[part 5 of 23: package /Cluster]
AUTOSAR XML (schema 4-3-0)
package /Cluster  (continued)
  can cluster E3V_EVCANFD: baudrate=500000, protocol-name=CAN, protocol-version=2.0, bus-off-recovery={bor-counter-l-1-to-l-2=1, bor-time-l-1=0.05, bor-time-l-2=0.2}, can-fd-baudrate=2000000  (continued)
    can physical channel CHNL: comm-connectors=CN_E3V_EVCANFD  (continued)
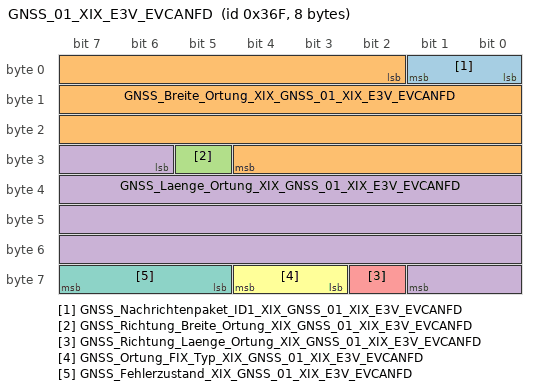
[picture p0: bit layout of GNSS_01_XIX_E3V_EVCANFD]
      frame GNSS_01_XIX_E3V_EVCANFD: id 0x36F, to Klima, frame-length=8, can-addressing-mode=STANDARD, can-frame-rx-behavior=CAN-FD, can-frame-tx-behavior=CAN-FD
        pdu GNSS_01_XIX_E3V_EVCANFD: length=8, transmission-mode-true-timing=cyclic-timing={time-offset=0.0, time-period=1.0}, unused-bit-pattern=0  # Nachricht 1 für Ortung: Position und Fixtyp.
          signal GNSS_Nachrichtenpaket_ID1_XIX_GNSS_01_XIX_E3V_EVCANFD: start 0, 2 bit, little-endian, data-type-policy=OVERRIDE, i-signal-type=PRIMITIVE, init-value=0, base-type=BT_GNSS_Nachrichtenpaket_ID1, compu {phys=raw for raw 0..3; unit Unit_Bit}, range phys 0..3 Unit_Bit, raw 0..3, unit=Unit_Bit, transfer-property=PENDING  # +1 für jedes neue Paket. Zyklische ID-Vergabe (Zähler). Zur Identifizierung zusammenhängender Nachrichten, die die Daten derselben GNSS-Ortung enthalten und somit zum selben Zyklus gehören. D.h. Daten in den Nachrichten wurden zur selben Zeit erzeugt. Der Zähler läuft um.
          signal GNSS_Breite_Ortung_XIX_GNSS_01_XIX_E3V_EVCANFD: start 2, 27 bit, little-endian, data-type-policy=OVERRIDE, i-signal-type=PRIMITIVE, init-value=134217726, base-type=BT_GNSS_Breite_Ortung, invalid-value=Invalid_GNSS_Breite_Ortung_XIX_GNSS_01_XIX_E3V_EVCANFD:134217727, compu {phys=raw*1e-06 for raw 0..90000000, 134217726=Cx7fffffe_Init (CM_GNSS_Breite_Ortung_Cx7fffffe_Init), 134217727=Cx7ffffff_Fehler (CM_GNSS_Breite_Ortung_Cx7ffffff_Fehler); unit Unit_DegreOfArc}, range phys 0..90 Unit_DegreOfArc, raw 0..134217727, unit=Unit_DegreOfArc, transfer-property=PENDING, to Klima(timeout 5 s)  # Breitengrad des Ortungsergebnisses nach WGS84 als Kombination von mehreren GNSSen
          signal GNSS_Richtung_Breite_Ortung_XIX_GNSS_01_XIX_E3V_EVCANFD: start 29, 1 bit, little-endian, data-type-policy=OVERRIDE, i-signal-type=PRIMITIVE, init-value=1, base-type=BT_GNSS_Richtung_Breite_Ortung, compu {0=Cx0_Nord (CM_GNSS_Richtung_Breite_Ortung_Cx0_Nord), 1=Cx1_Sued (CM_GNSS_Richtung_Breite_Ortung_Cx1_Sued)}, range raw 0..1, transfer-property=PENDING, to Klima(timeout 5 s)  # Richtung des Breitengrads des Ortungsergebnisses nach WGS84 als Kombination von mehreren GNSSen
          signal GNSS_Laenge_Ortung_XIX_GNSS_01_XIX_E3V_EVCANFD: start 30, 28 bit, little-endian, data-type-policy=OVERRIDE, i-signal-type=PRIMITIVE, init-value=268435454, base-type=BT_GNSS_Laenge_Ortung, invalid-value=Invalid_GNSS_Laenge_Ortung_XIX_GNSS_01_XIX_E3V_EVCANFD:268435455, compu {phys=raw*1e-06 for raw 0..180000000, 268435454=Cxffffffe_Init (CM_GNSS_Laenge_Ortung_Cxffffffe_Init), 268435455=Cxfffffff_Fehler (CM_GNSS_Laenge_Ortung_Cxfffffff_Fehler); unit Unit_DegreOfArc}, range phys 0..180 Unit_DegreOfArc, raw 0..268435455, unit=Unit_DegreOfArc, transfer-property=PENDING, to Klima(timeout 5 s)  # Längengrad des Ortungsergebnisses nach WGS84 als Kombination von mehreren GNSSen
          signal GNSS_Richtung_Laenge_Ortung_XIX_GNSS_01_XIX_E3V_EVCANFD: start 58, 1 bit, little-endian, data-type-policy=OVERRIDE, i-signal-type=PRIMITIVE, init-value=1, base-type=BT_GNSS_Richtung_Laenge_Ortung, compu {0=Cx0_Ost (CM_GNSS_Richtung_Laenge_Ortung_Cx0_Ost), 1=Cx1_West (CM_GNSS_Richtung_Laenge_Ortung_Cx1_West)}, range raw 0..1, transfer-property=PENDING, to Klima(timeout 5 s)  # Richtung des Längengrads des Ortungsergebnisses nach WGS84 als Kombination von mehreren GNSSen
          signal GNSS_Ortung_FIX_Typ_XIX_GNSS_01_XIX_E3V_EVCANFD: start 59, 2 bit, little-endian, data-type-policy=OVERRIDE, i-signal-type=PRIMITIVE, init-value=0, base-type=BT_GNSS_Ortung_FIX_Typ, compu {0=Cx0_Init (CM_GNSS_Ortung_FIX_Typ_Cx0_Init), 1=Cx1_No_Fix (CM_GNSS_Ortung_FIX_Typ_Cx1_No_Fix), 2=Cx2_2D_Fix (CM_GNSS_Ortung_FIX_Typ_Cx2_2D_Fix), 3=Cx3_3D_Fix (CM_GNSS_Ortung_FIX_Typ_Cx3_3D_Fix)}, range raw 0..3, transfer-property=PENDING  # Art des "GNSS-Fix" für die aktuelle Position auf Basis mehrerer GNSS Systeme.
          signal GNSS_Fehlerzustand_XIX_GNSS_01_XIX_E3V_EVCANFD: start 61, 3 bit, little-endian, data-type-policy=OVERRIDE, i-signal-type=PRIMITIVE, init-value=0, base-type=BT_GNSS_Fehlerzustand, compu {0=Cx0_Kein_Fehler (CM_GNSS_Fehlerzustand_Cx0_Kein_Fehler), 1=Cx1_P_Mode (CM_GNSS_Fehlerzustand_Cx1_P_Mode), 2=Cx2_T_Mode (CM_GNSS_Fehlerzustand_Cx2_T_Mode), 3=Cx3_GNSS_Receiver_Problem (CM_GNSS_Fehlerzustand_Cx3_GNSS_Receiver_Problem), 4=Cx4_Kommunikationsproblem_im_SG (CM_GNSS_Fehlerzustand_Cx4_Kommunikationsproblem_im_SG), 5=Cx5_Start_GNSS_Receiver (CM_GNSS_Fehlerzustand_Cx5_Start_GNSS_Receiver), 6=Cx6_GNSS_Receiver_aus (CM_GNSS_Fehlerzustand_Cx6_GNSS_Receiver_aus), 7=Cx7_SG_spezifischer_Fehler (CM_GNSS_Fehlerzustand_Cx7_SG_spezifischer_Fehler)}, range raw 0..7, transfer-property=PENDING  # Fehlerzustand von der GNSS-Funktion, daraufhin können keine GNSS-Daten geliefert werden
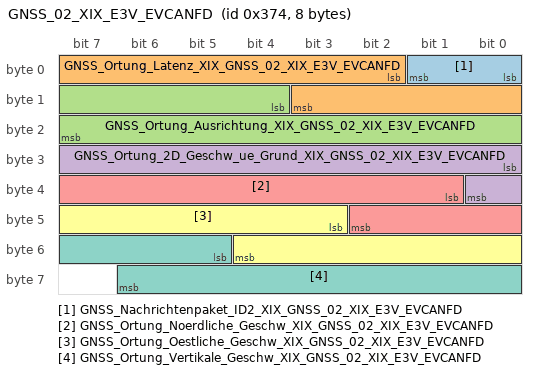
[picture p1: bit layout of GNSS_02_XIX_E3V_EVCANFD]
      frame GNSS_02_XIX_E3V_EVCANFD: id 0x374, to Klima, frame-length=8, can-addressing-mode=STANDARD, can-frame-rx-behavior=CAN-FD, can-frame-tx-behavior=CAN-FD
        pdu GNSS_02_XIX_E3V_EVCANFD: length=8, transmission-mode-true-timing=cyclic-timing={time-offset=0.0, time-period=1.0}, unused-bit-pattern=0  # Nachricht 2 für Ortung: Latenz, Geschwindigkeit und Richtung.
          signal GNSS_Nachrichtenpaket_ID2_XIX_GNSS_02_XIX_E3V_EVCANFD: start 0, 2 bit, little-endian, data-type-policy=OVERRIDE, i-signal-type=PRIMITIVE, init-value=0, base-type=BT_GNSS_Nachrichtenpaket_ID2, compu {phys=raw for raw 0..3; unit Unit_Bit}, range phys 0..3 Unit_Bit, raw 0..3, unit=Unit_Bit, transfer-property=PENDING  # +1 für jedes neue Paket. Zyklische ID-Vergabe (Zähler). Zur Identifizierung zusammenhängender Nachrichten, die die Daten derselben GNSS-Ortung enthalten und somit zum selben Zyklus gehören. D.h. Daten in den Nachrichten wurden zur selben Zeit erzeugt. Der Zähler läuft um.
          signal GNSS_Ortung_Latenz_XIX_GNSS_02_XIX_E3V_EVCANFD: start 2, 10 bit, little-endian, data-type-policy=OVERRIDE, i-signal-type=PRIMITIVE, init-value=1022, base-type=BT_GNSS_Ortung_Latenz, invalid-value=Invalid_GNSS_Ortung_Latenz_XIX_GNSS_02_XIX_E3V_EVCANFD:1023, compu {phys=raw for raw 0..1021, 1022=Cx3fe_Init (CM_GNSS_Ortung_Latenz_Cx3fe_Init), 1023=Cx3ff_Fehler (CM_GNSS_Ortung_Latenz_Cx3ff_Fehler); unit Unit_MilliSecon}, range phys 0..1021 Unit_MilliSecon, raw 0..1023, unit=Unit_MilliSecon, transfer-property=PENDING  # Latenz zwischen GNSS-Messung und aktueller Verteilung über CAN-Bus. Hinweis: Zur Stabilisierung der Latenz soll die GNSS-Zeit für die Bestimmung der CAN-Zyklendauer verwendet werden.
          signal GNSS_Ortung_Ausrichtung_XIX_GNSS_02_XIX_E3V_EVCANFD: start 12, 12 bit, little-endian, data-type-policy=OVERRIDE, i-signal-type=PRIMITIVE, init-value=4094, base-type=BT_GNSS_Ortung_Ausrichtung, invalid-value=Invalid_GNSS_Ortung_Ausrichtung_XIX_GNSS_02_XIX_E3V_EVCANFD:4095, compu {phys=raw*0.1 for raw 0..3599, 4094=Cxffe_Init (CM_GNSS_Ortung_Ausrichtung_Cxffe_Init), 4095=Cxfff_Fehler (CM_GNSS_Ortung_Ausrichtung_Cxfff_Fehler); unit Unit_DegreOfArc}, range phys 0..359.9 Unit_DegreOfArc, raw 0..4095, unit=Unit_DegreOfArc, transfer-property=PENDING, to Klima(timeout 5 s)  # Ausrichtung (Kurswinkel) der GNSS-Messung
          signal GNSS_Ortung_2D_Geschw_ue_Grund_XIX_GNSS_02_XIX_E3V_EVCANFD: start 24, 9 bit, little-endian, data-type-policy=OVERRIDE, i-signal-type=PRIMITIVE, init-value=510, base-type=BT_GNSS_Ortung_2D_Geschw_ue_Grund, invalid-value=Invalid_GNSS_Ortung_2D_Geschw_ue_Grund_XIX_GNSS_02_XIX_E3V_EVCANFD:511, compu {phys=raw*0.25 for raw 0..500, 510=Cx1fe_Init (CM_GNSS_Ortung_2D_Geschw_ue_Grund_Cx1fe_Init), 511=Cx1ff_Fehler (CM_GNSS_Ortung_2D_Geschw_ue_Grund_Cx1ff_Fehler); unit Unit_MeterPerSecon}, range phys 0..125 Unit_MeterPerSecon, raw 0..511, unit=Unit_MeterPerSecon, transfer-property=PENDING  # Geschwindigkeit in m pro Sekunde entsprechend dem GNSS-Empfänger
          signal GNSS_Ortung_Noerdliche_Geschw_XIX_GNSS_02_XIX_E3V_EVCANFD: start 33, 10 bit, little-endian, data-type-policy=OVERRIDE, i-signal-type=PRIMITIVE, init-value=1022, base-type=BT_GNSS_Ortung_Noerdliche_Geschw, invalid-value=Invalid_GNSS_Ortung_Noerdliche_Geschw_XIX_GNSS_02_XIX_E3V_EVCANFD:1023, compu {phys=raw*0.25-125 for raw 0..1000, 1022=Cx3fe_Init (CM_GNSS_Ortung_Noerdliche_Geschw_Cx3fe_Init), 1023=Cx3ff_Fehler (CM_GNSS_Ortung_Noerdliche_Geschw_Cx3ff_Fehler); unit Unit_MeterPerSecon}, range phys -125..125 Unit_MeterPerSecon, raw 0..1023, unit=Unit_MeterPerSecon, transfer-property=PENDING  # Geschwindigkeit in m pro Sekunde in Nordrichtung entsprechend dem GNSS-Empfänger
          signal GNSS_Ortung_Oestliche_Geschw_XIX_GNSS_02_XIX_E3V_EVCANFD: start 43, 10 bit, little-endian, data-type-policy=OVERRIDE, i-signal-type=PRIMITIVE, init-value=1022, base-type=BT_GNSS_Ortung_Oestliche_Geschw, invalid-value=Invalid_GNSS_Ortung_Oestliche_Geschw_XIX_GNSS_02_XIX_E3V_EVCANFD:1023, compu {phys=raw*0.25-125 for raw 0..1000, 1022=Cx3fe_Init (CM_GNSS_Ortung_Oestliche_Geschw_Cx3fe_Init), 1023=Cx3ff_Fehler (CM_GNSS_Ortung_Oestliche_Geschw_Cx3ff_Fehler); unit Unit_MeterPerSecon}, range phys -125..125 Unit_MeterPerSecon, raw 0..1023, unit=Unit_MeterPerSecon, transfer-property=PENDING  # Geschwindigkeit in m pro Sekunde in Ostrichtung entsprechend dem GNSS-Empfänger
          signal GNSS_Ortung_Vertikale_Geschw_XIX_GNSS_02_XIX_E3V_EVCANFD: start 53, 10 bit, little-endian, data-type-policy=OVERRIDE, i-signal-type=PRIMITIVE, init-value=1022, base-type=BT_GNSS_Ortung_Vertikale_Geschw, invalid-value=Invalid_GNSS_Ortung_Vertikale_Geschw_XIX_GNSS_02_XIX_E3V_EVCANFD:1023, compu {phys=raw*0.25-125 for raw 0..1000, 1022=Cx3fe_Init (CM_GNSS_Ortung_Vertikale_Geschw_Cx3fe_Init), 1023=Cx3ff_Fehler (CM_GNSS_Ortung_Vertikale_Geschw_Cx3ff_Fehler); unit Unit_MeterPerSecon}, range phys -125..125 Unit_MeterPerSecon, raw 0..1023, unit=Unit_MeterPerSecon, transfer-property=PENDING  # Geschwindigkeit in m pro Sekunde in vertikaler Richtung (aufwärts) entsprechend dem GNSS-Empfänger
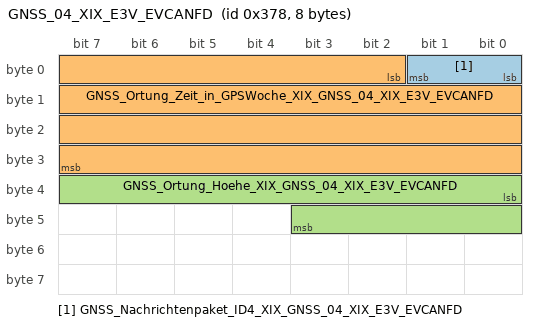
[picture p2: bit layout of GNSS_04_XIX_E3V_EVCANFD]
      frame GNSS_04_XIX_E3V_EVCANFD: id 0x378, to Klima, frame-length=8, can-addressing-mode=STANDARD, can-frame-rx-behavior=CAN-FD, can-frame-tx-behavior=CAN-FD
        pdu GNSS_04_XIX_E3V_EVCANFD: length=8, transmission-mode-true-timing=cyclic-timing={time-offset=0.0, time-period=1.0}, unused-bit-pattern=0  # Nachricht 4 für Ortung: Zeitstempel der Ortung.
          signal GNSS_Nachrichtenpaket_ID4_XIX_GNSS_04_XIX_E3V_EVCANFD: start 0, 2 bit, little-endian, data-type-policy=OVERRIDE, i-signal-type=PRIMITIVE, init-value=0, base-type=BT_GNSS_Nachrichtenpaket_ID4, compu {phys=raw for raw 0..3; unit Unit_Bit}, range phys 0..3 Unit_Bit, raw 0..3, unit=Unit_Bit, transfer-property=PENDING  # +1 für jedes neue Paket. Zyklische ID-Vergabe (Zähler). Zur Identifizierung zusammenhängender Nachrichten, die die Daten derselben GNSS-Ortung enthalten und somit zum selben Zyklus gehören. D.h. Daten in den Nachrichten wurden zur selben Zeit erzeugt. Der Zähler läuft um.
          signal GNSS_Ortung_Zeit_in_GPSWoche_XIX_GNSS_04_XIX_E3V_EVCANFD: start 2, 30 bit, little-endian, data-type-policy=OVERRIDE, i-signal-type=PRIMITIVE, init-value=1073741822, base-type=BT_GNSS_Ortung_Zeit_in_GPSWoche, invalid-value=Invalid_GNSS_Ortung_Zeit_in_GPSWoche_XIX_GNSS_04_XIX_E3V_EVCANFD:1073741823, compu {phys=raw for raw 0..604800001, 1073741822=Cx3ffffffe_Init (CM_GNSS_Ortung_Zeit_in_GPSWoche_Cx3ffffffe_Init), 1073741823=Cx3fffffff_Fehler (CM_GNSS_Ortung_Zeit_in_GPSWoche_Cx3fffffff_Fehler); unit Unit_MilliSecon}, range phys 0..604800001 Unit_MilliSecon, raw 0..1073741823, unit=Unit_MilliSecon, transfer-property=PENDING  # Zeitstempel für die Jitter-Prüfung aso. Zeit muss sychron zur Zeit der GNSS-Ortung sein.
          signal GNSS_Ortung_Hoehe_XIX_GNSS_04_XIX_E3V_EVCANFD: start 32, 12 bit, little-endian, data-type-policy=OVERRIDE, i-signal-type=PRIMITIVE, init-value=4094, base-type=BT_GNSS_Ortung_Hoehe, invalid-value=Invalid_GNSS_Ortung_Hoehe_XIX_GNSS_04_XIX_E3V_EVCANFD:4095, compu {phys=raw*2-500 for raw 0..4093, 4094=Cxffe_Init (CM_GNSS_Ortung_Hoehe_Cxffe_Init), 4095=Cxfff_Fehler (CM_GNSS_Ortung_Hoehe_Cxfff_Fehler); unit Unit_Meter}, range phys -500..7686 Unit_Meter, raw 0..4095, unit=Unit_Meter, transfer-property=PENDING, to Klima(timeout 5 s)  # Höhe über dem Meeresspiegel
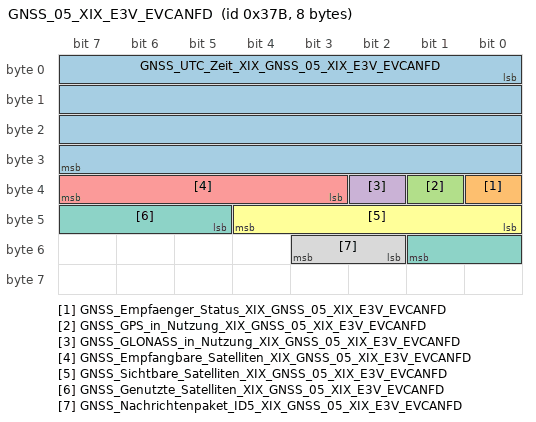
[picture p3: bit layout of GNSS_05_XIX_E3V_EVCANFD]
      frame GNSS_05_XIX_E3V_EVCANFD: id 0x37B, to Klima, frame-length=8, can-addressing-mode=STANDARD, can-frame-rx-behavior=CAN-FD, can-frame-tx-behavior=CAN-FD
        pdu GNSS_05_XIX_E3V_EVCANFD: length=8, transmission-mode-true-timing=cyclic-timing={time-offset=0.0, time-period=1.0}, unused-bit-pattern=0  # Nachricht 5: Empfängerstatus und UTC.
          signal GNSS_UTC_Zeit_XIX_GNSS_05_XIX_E3V_EVCANFD: start 0, 32 bit, little-endian, data-type-policy=OVERRIDE, i-signal-type=PRIMITIVE, init-value=0, base-type=BT_GNSS_UTC_Zeit, compu {0=Cx0_Init (CM_GNSS_UTC_Zeit_Cx0_Init), phys=raw for raw 1..4294967295; unit Unit_Secon}, range phys 1..4294967295 Unit_Secon, raw 0..4294967295, unit=Unit_Secon, transfer-property=PENDING, to Klima(timeout 5 s)  # UTC-Zeit, Sekunden seit dem 01.01.1970 00:00
          signal GNSS_Empfaenger_Status_XIX_GNSS_05_XIX_E3V_EVCANFD: start 32, 1 bit, little-endian, data-type-policy=OVERRIDE, i-signal-type=PRIMITIVE, init-value=0, base-type=BT_GNSS_Empfaenger_Status, compu {0=Cx0_Backup_Mode (CM_GNSS_Empfaenger_Status_Cx0_Backup_Mode), 1=Cx1_Live (CM_GNSS_Empfaenger_Status_Cx1_Live)}, range raw 0..1, transfer-property=PENDING  # Im "Backup Mode" wird z.B. die UTC Zeit durch eine gepufferte "Realtime Clock" bereitgestellt. Im "Live Mode" wird die UTC Zeit durch das GNSS Modul bereitgestellt.
          signal GNSS_GPS_in_Nutzung_XIX_GNSS_05_XIX_E3V_EVCANFD: start 33, 1 bit, little-endian, data-type-policy=OVERRIDE, i-signal-type=PRIMITIVE, init-value=0, base-type=BT_GNSS_GPS_in_Nutzung, compu {0=Cx0_unbenutzt (CM_GNSS_GPS_in_Nutzung_Cx0_unbenutzt), 1=Cx1_benutzt (CM_GNSS_GPS_in_Nutzung_Cx1_benutzt)}, range raw 0..1, transfer-property=PENDING  # 1: das genannte GNSS wurde für die Ortung verwendet
          signal GNSS_GLONASS_in_Nutzung_XIX_GNSS_05_XIX_E3V_EVCANFD: start 34, 1 bit, little-endian, data-type-policy=OVERRIDE, i-signal-type=PRIMITIVE, init-value=0, base-type=BT_GNSS_GLONASS_in_Nutzung, compu {0=Cx0_unbenutzt (CM_GNSS_GLONASS_in_Nutzung_Cx0_unbenutzt), 1=Cx1_benutzt (CM_GNSS_GLONASS_in_Nutzung_Cx1_benutzt)}, range raw 0..1, transfer-property=PENDING  # 1: das genannte GNSS wurde für die Ortung verwendet
          signal GNSS_Empfangbare_Satelliten_XIX_GNSS_05_XIX_E3V_EVCANFD: start 35, 5 bit, little-endian, data-type-policy=OVERRIDE, i-signal-type=PRIMITIVE, init-value=0, base-type=BT_GNSS_Empfangbare_Satelliten, compu {0=Cx0_Init (CM_GNSS_Empfangbare_Satelliten_Cx0_Init), phys=raw for raw 1..30, 31=Cx1f_31_oder_mehr (CM_GNSS_Empfangbare_Satelliten_Cx1f_31_oder_mehr); unit Unit_None}, range phys 1..30 Unit_None, raw 0..31, unit=Unit_None, transfer-property=PENDING  # Anzahl der Satelliten, welche bei der aktuellen Satellitenkonfiguration ptentiell verfügbar sind
          signal GNSS_Sichtbare_Satelliten_XIX_GNSS_05_XIX_E3V_EVCANFD: start 40, 5 bit, little-endian, data-type-policy=OVERRIDE, i-signal-type=PRIMITIVE, init-value=0, base-type=BT_GNSS_Sichtbare_Satelliten, compu {0=Cx0_Init (CM_GNSS_Sichtbare_Satelliten_Cx0_Init), phys=raw for raw 1..30, 31=Cx1f_31_oder_mehr (CM_GNSS_Sichtbare_Satelliten_Cx1f_31_oder_mehr); unit Unit_None}, range phys 1..30 Unit_None, raw 0..31, unit=Unit_None, transfer-property=PENDING  # Anzahl der Satelliten, welche aktuell empfangen werden
          signal GNSS_Genutzte_Satelliten_XIX_GNSS_05_XIX_E3V_EVCANFD: start 45, 5 bit, little-endian, data-type-policy=OVERRIDE, i-signal-type=PRIMITIVE, init-value=0, base-type=BT_GNSS_Genutzte_Satelliten, compu {0=Cx0_Init (CM_GNSS_Genutzte_Satelliten_Cx0_Init), phys=raw for raw 1..30, 31=Cx1f_31_oder_mehr (CM_GNSS_Genutzte_Satelliten_Cx1f_31_oder_mehr); unit Unit_None}, range phys 1..30 Unit_None, raw 0..31, unit=Unit_None, transfer-property=PENDING  # Anzahl der Satelliten, welche für die aktuelle Ortung verwendet werden
          signal GNSS_Nachrichtenpaket_ID5_XIX_GNSS_05_XIX_E3V_EVCANFD: start 50, 2 bit, little-endian, data-type-policy=OVERRIDE, i-signal-type=PRIMITIVE, init-value=0, base-type=BT_GNSS_Nachrichtenpaket_ID5, compu {phys=raw for raw 0..3; unit Unit_Bit}, range phys 0..3 Unit_Bit, raw 0..3, unit=Unit_Bit, transfer-property=PENDING  # +1 für jedes neue Paket. Zyklische ID-Vergabe (Zähler). Zur Identifizierung zusammenhängender Nachrichten, die die Daten derselben GNSS-Ortung enthalten und somit zum selben Zyklus gehören. D.h. Daten in den Nachrichten wurden zur selben Zeit erzeugt. Der Zähler läuft um.
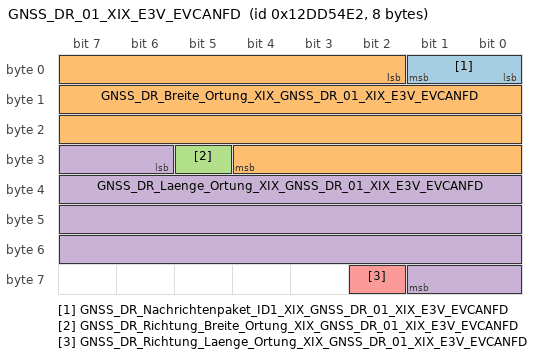
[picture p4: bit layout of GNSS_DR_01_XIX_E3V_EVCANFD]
      frame GNSS_DR_01_XIX_E3V_EVCANFD: id 0x12DD54E2, to Klima, frame-length=8, can-addressing-mode=EXTENDED, can-frame-rx-behavior=CAN-FD, can-frame-tx-behavior=CAN-FD
        pdu GNSS_DR_01_XIX_E3V_EVCANFD: length=8, transmission-mode-true-timing=cyclic-timing={time-offset=0, time-period=0.1}, unused-bit-pattern=0
          signal GNSS_DR_Nachrichtenpaket_ID1_XIX_GNSS_DR_01_XIX_E3V_EVCANFD: start 0, 2 bit, little-endian, data-type-policy=OVERRIDE, i-signal-type=PRIMITIVE, init-value=0, base-type=BT_GNSS_DR_Nachrichtenpaket_ID1, compu {phys=raw for raw 0..3; unit Unit_Bit}, range phys 0..3 Unit_Bit, raw 0..3, unit=Unit_Bit, transfer-property=PENDING  # +1 für jedes neue Paket. Zyklische ID-Vergabe (Zähler). Zur Identifizierung zusammenhängender Nachrichten, die die Daten derselben GNSS-Ortung enthalten und somit zum selben Zyklus gehören. D.h. Daten in den Nachrichten wurden zur selben Zeit erzeugt. Der Zähler läuft um.
          signal GNSS_DR_Breite_Ortung_XIX_GNSS_DR_01_XIX_E3V_EVCANFD: start 2, 27 bit, little-endian, data-type-policy=OVERRIDE, i-signal-type=PRIMITIVE, init-value=134217726, base-type=BT_GNSS_DR_Breite_Ortung, invalid-value=Invalid_GNSS_DR_Breite_Ortung_XIX_GNSS_DR_01_XIX_E3V_EVCANFD:134217727, compu {phys=raw*1e-06 for raw 0..90000000, 134217726=Cx7fffffe_Init (CM_GNSS_DR_Breite_Ortung_Cx7fffffe_Init), 134217727=Cx7ffffff_Fehler (CM_GNSS_DR_Breite_Ortung_Cx7ffffff_Fehler); unit Unit_DegreOfArc}, range phys 0..90 Unit_DegreOfArc, raw 0..134217727, unit=Unit_DegreOfArc, transfer-property=PENDING, to Klima(timeout 1 s)  # Dead Reckoning Breitengrad des Ortungsergebnisses nach WGS84 als Kombination von mehreren GNSSen
          signal GNSS_DR_Richtung_Breite_Ortung_XIX_GNSS_DR_01_XIX_E3V_EVCANFD: start 29, 1 bit, little-endian, data-type-policy=OVERRIDE, i-signal-type=PRIMITIVE, init-value=1, base-type=BT_GNSS_DR_Richtung_Breite_Ortung, compu {0=Cx0_Nord (CM_GNSS_DR_Richtung_Breite_Ortung_Cx0_Nord), 1=Cx1_Sued (CM_GNSS_DR_Richtung_Breite_Ortung_Cx1_Sued)}, range raw 0..1, transfer-property=PENDING, to Klima(timeout 1 s)  # Dead Reckoning Richtung des Breitengrads des Ortungsergebnisses nach WGS84 als Kombination von mehreren GNSSen
          signal GNSS_DR_Laenge_Ortung_XIX_GNSS_DR_01_XIX_E3V_EVCANFD: start 30, 28 bit, little-endian, data-type-policy=OVERRIDE, i-signal-type=PRIMITIVE, init-value=268435454, base-type=BT_GNSS_DR_Laenge_Ortung, invalid-value=Invalid_GNSS_DR_Laenge_Ortung_XIX_GNSS_DR_01_XIX_E3V_EVCANFD:268435455, compu {phys=raw*1e-06 for raw 0..180000000, 268435454=Cxffffffe_Init (CM_GNSS_DR_Laenge_Ortung_Cxffffffe_Init), 268435455=Cxfffffff_Fehler (CM_GNSS_DR_Laenge_Ortung_Cxfffffff_Fehler); unit Unit_DegreOfArc}, range phys 0..180 Unit_DegreOfArc, raw 0..268435455, unit=Unit_DegreOfArc, transfer-property=PENDING, to Klima(timeout 1 s)  # Dead Reckoning Längengrad des Ortungsergebnisses nach WGS84 als Kombination von mehreren GNSSen
          signal GNSS_DR_Richtung_Laenge_Ortung_XIX_GNSS_DR_01_XIX_E3V_EVCANFD: start 58, 1 bit, little-endian, data-type-policy=OVERRIDE, i-signal-type=PRIMITIVE, init-value=1, base-type=BT_GNSS_DR_Richtung_Laenge_Ortung, compu {0=Cx0_Ost (CM_GNSS_DR_Richtung_Laenge_Ortung_Cx0_Ost), 1=Cx1_West (CM_GNSS_DR_Richtung_Laenge_Ortung_Cx1_West)}, range raw 0..1, transfer-property=PENDING, to Klima(timeout 1 s)  # Dead Reckoning Richtung des Längengrads des Ortungsergebnisses nach WGS84 als Kombination von mehreren GNSSen
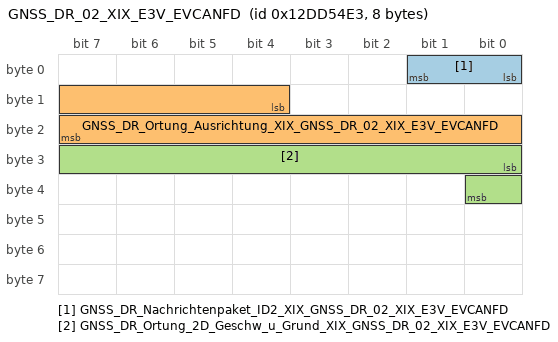
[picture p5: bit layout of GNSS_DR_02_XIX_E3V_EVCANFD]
      frame GNSS_DR_02_XIX_E3V_EVCANFD: id 0x12DD54E3, to Klima, frame-length=8, can-addressing-mode=EXTENDED, can-frame-rx-behavior=CAN-FD, can-frame-tx-behavior=CAN-FD
        pdu GNSS_DR_02_XIX_E3V_EVCANFD: length=8, transmission-mode-true-timing=cyclic-timing={time-offset=0, time-period=0.1}, unused-bit-pattern=0
          signal GNSS_DR_Nachrichtenpaket_ID2_XIX_GNSS_DR_02_XIX_E3V_EVCANFD: start 0, 2 bit, little-endian, data-type-policy=OVERRIDE, i-signal-type=PRIMITIVE, init-value=0, base-type=BT_GNSS_DR_Nachrichtenpaket_ID2, compu {phys=raw for raw 0..3; unit Unit_Bit}, range phys 0..3 Unit_Bit, raw 0..3, unit=Unit_Bit, transfer-property=PENDING  # +1 für jedes neue Paket. Zyklische ID-Vergabe (Zähler). Zur Identifizierung zusammenhängender Nachrichten, die die Daten derselben GNSS-Ortung enthalten und somit zum selben Zyklus gehören. D.h. Daten in den Nachrichten wurden zur selben Zeit erzeugt. Der Zähler läuft um.
          signal GNSS_DR_Ortung_Ausrichtung_XIX_GNSS_DR_02_XIX_E3V_EVCANFD: start 12, 12 bit, little-endian, data-type-policy=OVERRIDE, i-signal-type=PRIMITIVE, init-value=4094, base-type=BT_GNSS_DR_Ortung_Ausrichtung, invalid-value=Invalid_GNSS_DR_Ortung_Ausrichtung_XIX_GNSS_DR_02_XIX_E3V_EVCANFD:4095, compu {phys=raw*0.1 for raw 0..3599, 4094=Cxffe_Init (CM_GNSS_DR_Ortung_Ausrichtung_Cxffe_Init), 4095=Cxfff_Fehler (CM_GNSS_DR_Ortung_Ausrichtung_Cxfff_Fehler); unit Unit_DegreOfArc}, range phys 0..359.9 Unit_DegreOfArc, raw 0..4095, unit=Unit_DegreOfArc, transfer-property=PENDING, to Klima(timeout 1 s)  # Dead Reckoning Ausrichtung (Kurswinkel) der GNSS-Messung
          signal GNSS_DR_Ortung_2D_Geschw_u_Grund_XIX_GNSS_DR_02_XIX_E3V_EVCANFD: start 24, 9 bit, little-endian, data-type-policy=OVERRIDE, i-signal-type=PRIMITIVE, init-value=510, base-type=BT_GNSS_DR_Ortung_2D_Geschw_u_Grund, invalid-value=Invalid_GNSS_DR_Ortung_2D_Geschw_u_Grund_XIX_GNSS_DR_02_XIX_E3V_EVCANFD:511, compu {phys=raw*0.25 for raw 0..500, 510=Cx1fe_Init (CM_GNSS_DR_Ortung_2D_Geschw_u_Grund_Cx1fe_Init), 511=Cx1ff_Fehler (CM_GNSS_DR_Ortung_2D_Geschw_u_Grund_Cx1ff_Fehler); unit Unit_MeterPerSecon}, range phys 0..125 Unit_MeterPerSecon, raw 0..511, unit=Unit_MeterPerSecon, transfer-property=PENDING  # Dead Reckoning Geschwindigkeit in m pro Sekunde
      frame GNSS_DR_05_XIX_E3V_EVCANFD: id 0x12DD54E6, to Klima, frame-length=8, can-addressing-mode=EXTENDED, can-frame-rx-behavior=CAN-FD, can-frame-tx-behavior=CAN-FD
        pdu GNSS_DR_05_XIX_E3V_EVCANFD: length=8, transmission-mode-true-timing=cyclic-timing={time-offset=0, time-period=0.1}, unused-bit-pattern=0
          signal GNSS_DR_UTC_Zeit_XIX_GNSS_DR_05_XIX_E3V_EVCANFD: start 0, 32 bit, little-endian, data-type-policy=OVERRIDE, i-signal-type=PRIMITIVE, init-value=0, base-type=BT_GNSS_DR_UTC_Zeit, compu {0=Cx0_Init (CM_GNSS_DR_UTC_Zeit_Cx0_Init), phys=raw for raw 1..4294967295; unit Unit_Secon}, range phys 1..4294967295 Unit_Secon, raw 0..4294967295, unit=Unit_Secon, transfer-property=PENDING, to Klima(timeout 1 s)  # Dead Reckoning UTC-Zeit, Sekunden seit dem 01.01.1970 00:00
          signal GNSS_DR_Nachrichtenpaket_ID5_XIX_GNSS_DR_05_XIX_E3V_EVCANFD: start 32, 2 bit, little-endian, data-type-policy=OVERRIDE, i-signal-type=PRIMITIVE, init-value=0, base-type=BT_GNSS_DR_Nachrichtenpaket_ID5, compu {phys=raw for raw 0..3; unit Unit_Bit}, range phys 0..3 Unit_Bit, raw 0..3, unit=Unit_Bit, transfer-property=PENDING  # +1 für jedes neue Paket. Zyklische ID-Vergabe (Zähler). Zur Identifizierung zusammenhängender Nachrichten, die die Daten derselben GNSS-Ortung enthalten und somit zum selben Zyklus gehören. D.h. Daten in den Nachrichten wurden zur selben Zeit erzeugt. Der Zähler läuft um.
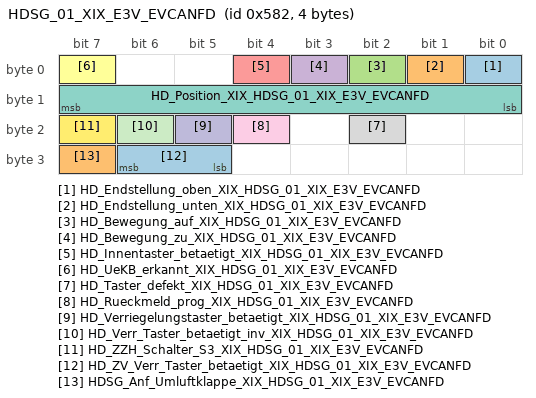
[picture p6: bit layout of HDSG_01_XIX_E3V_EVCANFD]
      frame HDSG_01_XIX_E3V_EVCANFD: id 0x582, to Klima, frame-length=4, can-addressing-mode=STANDARD, can-frame-rx-behavior=CAN-FD, can-frame-tx-behavior=CAN-FD
        pdu HDSG_01_XIX_E3V_EVCANFD: length=4, minimum-delay=0.02, transmission-mode-true-timing={cyclic-timing={time-offset=0.0, time-period=0.2}, event-controlled-timing={number-of-repetitions=0, repetition-period=0.0}}, unused-bit-pattern=0
          signal HD_Endstellung_oben_XIX_HDSG_01_XIX_E3V_EVCANFD: start 0, 1 bit, little-endian, data-type-policy=OVERRIDE, i-signal-type=PRIMITIVE, init-value=0, base-type=BT_HD_Endstellung_oben, compu {1=Cx1_HD_in_Endstellung_oben_offen (CM_HD_Endstellung_oben_Cx1_HD_in_Endstellung_oben_offen) (HD in Endstellung oben (offen))}, range raw 1, transfer-property=PENDING  # obere Endstellung HD
          signal HD_Endstellung_unten_XIX_HDSG_01_XIX_E3V_EVCANFD: start 1, 1 bit, little-endian, data-type-policy=OVERRIDE, i-signal-type=PRIMITIVE, init-value=0, base-type=BT_HD_Endstellung_unten, compu {0=Cx0_Init (CM_HD_Endstellung_unten_Cx0_Init), 1=Cx1_HD_in_Endstellung_unten_geschlossen (CM_HD_Endstellung_unten_Cx1_HD_in_Endstellung_unten_geschlossen) (HD in Endstellung unten (geschlossen))}, range raw 0..1, transfer-property=PENDING  # untere Endstellung HD
          signal HD_Bewegung_auf_XIX_HDSG_01_XIX_E3V_EVCANFD: start 2, 1 bit, little-endian, data-type-policy=OVERRIDE, i-signal-type=PRIMITIVE, init-value=0, base-type=BT_HD_Bewegung_auf, compu {0=Cx0_Init (CM_HD_Bewegung_auf_Cx0_Init), 1=Cx1_HD_in_Bewegung_auf (CM_HD_Bewegung_auf_Cx1_HD_in_Bewegung_auf) (HD in Bewegung auf)}, range raw 0..1, transfer-property=PENDING  # Bewegung HD (öffnen)
          signal HD_Bewegung_zu_XIX_HDSG_01_XIX_E3V_EVCANFD: start 3, 1 bit, little-endian, data-type-policy=OVERRIDE, i-signal-type=PRIMITIVE, init-value=0, base-type=BT_HD_Bewegung_zu, compu {0=Cx0_Init (CM_HD_Bewegung_zu_Cx0_Init), 1=Cx1_HD_in_Bewegung_zu (CM_HD_Bewegung_zu_Cx1_HD_in_Bewegung_zu) (HD in Bewegung zu)}, range raw 0..1, transfer-property=PENDING  # Bewegung HD (schließen)
          signal HD_Innentaster_betaetigt_XIX_HDSG_01_XIX_E3V_EVCANFD: start 4, 1 bit, little-endian, data-type-policy=OVERRIDE, i-signal-type=PRIMITIVE, init-value=0, base-type=BT_HD_Innentaster_betaetigt, compu {0=Cx0_HD_Innentaster_nicht_betaetigt (CM_HD_Innentaster_betaetigt_Cx0_HD_Innentaster_nicht_betaetigt), 1=Cx1_HD_Innentaster_betaetigt (CM_HD_Innentaster_betaetigt_Cx1_HD_Innentaster_betaetigt)}, range raw 0..1, transfer-property=PENDING  # Betätigung Innentaster HD
          signal HD_UeKB_erkannt_XIX_HDSG_01_XIX_E3V_EVCANFD: start 7, 1 bit, little-endian, data-type-policy=OVERRIDE, i-signal-type=PRIMITIVE, init-value=0, base-type=BT_HD_UeKB_erkannt, compu {0=Cx0_Init (CM_HD_UeKB_erkannt_Cx0_Init), 1=Cx1_Einklemmschutz_aktiv (CM_HD_UeKB_erkannt_Cx1_Einklemmschutz_aktiv) (Einklemmschutz aktiv)}, range raw 0..1, transfer-property=PENDING  # Erkennung Einklemmschutz
          signal HD_Position_XIX_HDSG_01_XIX_E3V_EVCANFD: start 8, 8 bit, little-endian, data-type-policy=OVERRIDE, i-signal-type=PRIMITIVE, init-value=0, base-type=BT_HD_Position, compu {phys=raw for raw 0..100; unit Unit_PerCent}, range phys 0..100 Unit_PerCent, raw 0..100, unit=Unit_PerCent, transfer-property=PENDING  # HD Position von 0 bis 100 %
          signal HD_Taster_defekt_XIX_HDSG_01_XIX_E3V_EVCANFD: start 18, 1 bit, little-endian, data-type-policy=OVERRIDE, i-signal-type=PRIMITIVE, init-value=0, base-type=BT_HD_Taster_defekt, compu {0=Cx0_Taster_funktionsfaehig (CM_HD_Taster_defekt_Cx0_Taster_funktionsfaehig) (Taster_funktionsfähig), 1=Cx1_Taster_defekt (CM_HD_Taster_defekt_Cx1_Taster_defekt) (Taster defekt)}, range raw 0..1, transfer-property=PENDING  # Anzeige ob Heckdeckeltaster defekt ist
          signal HD_Rueckmeld_prog_XIX_HDSG_01_XIX_E3V_EVCANFD: start 20, 1 bit, little-endian, data-type-policy=OVERRIDE, i-signal-type=PRIMITIVE, init-value=0, base-type=BT_HD_Rueckmeld_prog, compu {0=Cx0_keine_Rueckmeldung (CM_HD_Rueckmeld_prog_Cx0_keine_Rueckmeldung) (keine Rueckmeldung), 1=Cx1_Rueckmeldung_zur_Programmierung_Endstellung_aktiv (CM_HD_Rueckmeld_prog_Cx1_Rueckmeldung_zur_Programmierung_Endstellung_aktiv) (Rueckmeldung zur Programmierung Endstellung aktiv)}, range raw 0..1, transfer-property=PENDING  # Programmierung Endstellung HD
          signal HD_Verriegelungstaster_betaetigt_XIX_HDSG_01_XIX_E3V_EVCANFD: start 21, 1 bit, little-endian, data-type-policy=OVERRIDE, i-signal-type=PRIMITIVE, init-value=0, base-type=BT_HD_Verriegelungstaster_betaetigt, compu {0=Cx0_Taster_nicht_betaetigt (CM_HD_Verriegelungstaster_betaetigt_Cx0_Taster_nicht_betaetigt), 1=Cx1_Taster_betaetigt (CM_HD_Verriegelungstaster_betaetigt_Cx1_Taster_betaetigt)}, range raw 0..1, transfer-property=PENDING  # Betätigung des Verriegelungstaster für Heckdeckel
          signal HD_Verr_Taster_betaetigt_inv_XIX_HDSG_01_XIX_E3V_EVCANFD: start 22, 1 bit, little-endian, data-type-policy=OVERRIDE, i-signal-type=PRIMITIVE, base-type=BT_HD_Verr_Taster_betaetigt_inv, compu {0=Cx0_Taster_betaetigt (CM_HD_Verr_Taster_betaetigt_inv_Cx0_Taster_betaetigt), 1=Cx1_Taster_nicht_betaetigt (CM_HD_Verr_Taster_betaetigt_inv_Cx1_Taster_nicht_betaetigt)}, range raw 0..1, transfer-property=PENDING  # Inverses Bit (Fusi-Anforderung) Betätigung des Verriegelungstaster für Heckdeckel
          signal HD_ZZH_Schalter_S3_XIX_HDSG_01_XIX_E3V_EVCANFD: start 23, 1 bit, little-endian, data-type-policy=OVERRIDE, i-signal-type=PRIMITIVE, init-value=0, base-type=BT_HD_ZZH_Schalter_S3, compu {0=Cx0_nicht_betaetigt (CM_HD_ZZH_Schalter_S3_Cx0_nicht_betaetigt), 1=Cx1_betaetigt (CM_HD_ZZH_Schalter_S3_Cx1_betaetigt)}, range raw 0..1, transfer-property=TRIGGERED-ON-CHANGE-WITHOUT-REPETITION  # Teilt den Zustand des Statusschalters in einer unidirektionalen ZZH mit.
          signal HD_ZV_Verr_Taster_betaetigt_XIX_HDSG_01_XIX_E3V_EVCANFD: start 29, 2 bit, little-endian, data-type-policy=OVERRIDE, i-signal-type=PRIMITIVE, init-value=0, base-type=BT_HD_ZV_Verr_Taster_betaetigt, compu {0=Cx0_Taster_nicht_betaetigt (CM_HD_ZV_Verr_Taster_betaetigt_Cx0_Taster_nicht_betaetigt), 1=Cx1_Taster_betaetigtt (CM_HD_ZV_Verr_Taster_betaetigt_Cx1_Taster_betaetigtt)}, range raw 0..1, transfer-property=TRIGGERED-ON-CHANGE-WITHOUT-REPETITION  # Betätigung des Verriegelungstaster für Heckdeckel
          signal HDSG_Anf_Umluftklappe_XIX_HDSG_01_XIX_E3V_EVCANFD: start 31, 1 bit, little-endian, data-type-policy=OVERRIDE, i-signal-type=PRIMITIVE, init-value=0, base-type=BT_HDSG_Anf_Umluftklappe, compu {0=Cx0_aus (CM_HDSG_Anf_Umluftklappe_Cx0_aus), 1=Cx1_an (CM_HDSG_Anf_Umluftklappe_Cx1_an)}, range raw 0..1, transfer-property=TRIGGERED-ON-CHANGE-WITHOUT-REPETITION, to Klima(timeout 2 s)  # Signal zur Ansteuerung der Umluftklappe Klima.
      frame HLR_02_XIX_E3V_EVCANFD: id 0x3F8, to Klima, frame-length=8, can-addressing-mode=STANDARD, can-frame-rx-behavior=CAN-FD, can-frame-tx-behavior=CAN-FD
        pdu HLR_02_XIX_E3V_EVCANFD: length=8, minimum-delay=0.05, transmission-mode-true-timing={cyclic-timing={time-offset=0.07, time-period=0.5}, event-controlled-timing={number-of-repetitions=0, repetition-period=0.0}}, unused-bit-pattern=0  # Heizleistungsregelung MLBevo (NVEM im Gateway)
          signal HLR_FlHz_Freigabe_Ruhesitz_XIX_HLR_02_XIX_E3V_EVCANFD: start 14, 2 bit, little-endian, data-type-policy=OVERRIDE, i-signal-type=PRIMITIVE, init-value=0, base-type=BT_HLR_FlHz_Freigabe_Ruhesitz, compu {0=Cx0_0_Prozent (CM_HLR_FlHz_Freigabe_Ruhesitz_Cx0_0_Prozent), 1=Cx1_33_Prozent (CM_HLR_FlHz_Freigabe_Ruhesitz_Cx1_33_Prozent), 2=Cx2_66_Prozent (CM_HLR_FlHz_Freigabe_Ruhesitz_Cx2_66_Prozent), 3=Cx3_100_Prozent (CM_HLR_FlHz_Freigabe_Ruhesitz_Cx3_100_Prozent)}, range raw 0..3, transfer-property=TRIGGERED-ON-CHANGE-WITHOUT-REPETITION  # Freigabe des NVEM für die Flächenheizung des Ruhesitzes
          signal HLR_FlHz_Freigabe_VR_XIX_HLR_02_XIX_E3V_EVCANFD: start 16, 2 bit, little-endian, data-type-policy=OVERRIDE, i-signal-type=PRIMITIVE, init-value=0, base-type=BT_HLR_FlHz_Freigabe_VR, compu {0=Cx0_0_Prozent (CM_HLR_FlHz_Freigabe_VR_Cx0_0_Prozent), 1=Cx1_33_Prozent (CM_HLR_FlHz_Freigabe_VR_Cx1_33_Prozent), 2=Cx2_66_Prozent (CM_HLR_FlHz_Freigabe_VR_Cx2_66_Prozent), 3=Cx3_100_Prozent (CM_HLR_FlHz_Freigabe_VR_Cx3_100_Prozent)}, range raw 0..3, transfer-property=TRIGGERED-ON-CHANGE-WITHOUT-REPETITION  # Freigabe des NVEM für die Flächenheizung vorne rechts
          signal HLR_FlHz_Freigabe_VL_XIX_HLR_02_XIX_E3V_EVCANFD: start 18, 2 bit, little-endian, data-type-policy=OVERRIDE, i-signal-type=PRIMITIVE, init-value=0, base-type=BT_HLR_FlHz_Freigabe_VL, compu {0=Cx0_0_Prozent (CM_HLR_FlHz_Freigabe_VL_Cx0_0_Prozent), 1=Cx1_33_Prozent (CM_HLR_FlHz_Freigabe_VL_Cx1_33_Prozent), 2=Cx2_66_Prozent (CM_HLR_FlHz_Freigabe_VL_Cx2_66_Prozent), 3=Cx3_100_Prozent (CM_HLR_FlHz_Freigabe_VL_Cx3_100_Prozent)}, range raw 0..3, transfer-property=TRIGGERED-ON-CHANGE-WITHOUT-REPETITION  # Freigabe des NVEM für die Flächenheizung vorne links
          signal HLR_FlHz_Freigabe_HR_XIX_HLR_02_XIX_E3V_EVCANFD: start 20, 2 bit, little-endian, data-type-policy=OVERRIDE, i-signal-type=PRIMITIVE, init-value=0, base-type=BT_HLR_FlHz_Freigabe_HR, compu {0=Cx0_0_Prozent (CM_HLR_FlHz_Freigabe_HR_Cx0_0_Prozent), 1=Cx1_33_Prozent (CM_HLR_FlHz_Freigabe_HR_Cx1_33_Prozent), 2=Cx2_66_Prozent (CM_HLR_FlHz_Freigabe_HR_Cx2_66_Prozent), 3=Cx3_100_Prozent (CM_HLR_FlHz_Freigabe_HR_Cx3_100_Prozent)}, range raw 0..3, transfer-property=TRIGGERED-ON-CHANGE-WITHOUT-REPETITION  # Freigabe des NVEM für die Flächenheizung hinten rechts
          signal HLR_FlHz_Freigabe_HL_XIX_HLR_02_XIX_E3V_EVCANFD: start 22, 2 bit, little-endian, data-type-policy=OVERRIDE, i-signal-type=PRIMITIVE, init-value=0, base-type=BT_HLR_FlHz_Freigabe_HL, compu {0=Cx0_0_Prozent (CM_HLR_FlHz_Freigabe_HL_Cx0_0_Prozent), 1=Cx1_33_Prozent (CM_HLR_FlHz_Freigabe_HL_Cx1_33_Prozent), 2=Cx2_66_Prozent (CM_HLR_FlHz_Freigabe_HL_Cx2_66_Prozent), 3=Cx3_100_Prozent (CM_HLR_FlHz_Freigabe_HL_Cx3_100_Prozent)}, range raw 0..3, transfer-property=TRIGGERED-ON-CHANGE-WITHOUT-REPETITION  # Freigabe des NVEM für die Flächenheizung hinten links
          signal HLR_TCH_Freigabe_XIX_HLR_02_XIX_E3V_EVCANFD: start 24, 1 bit, little-endian, data-type-policy=OVERRIDE, i-signal-type=PRIMITIVE, init-value=0, base-type=BT_HLR_TCH_Freigabe, compu {0=Cx0_keine_Freigabe (CM_HLR_TCH_Freigabe_Cx0_keine_Freigabe), 1=Cx1_Freigabe (CM_HLR_TCH_Freigabe_Cx1_Freigabe)}, range raw 0..1, transfer-property=TRIGGERED-ON-CHANGE-WITHOUT-REPETITION  # Freigabe des NVEM für den Thermocupholder
          signal HLR_SIH_Freigabe_Fond_XIX_HLR_02_XIX_E3V_EVCANFD: start 25, 1 bit, little-endian, data-type-policy=OVERRIDE, i-signal-type=PRIMITIVE, init-value=0, base-type=BT_HLR_SIH_Freigabe_Fond, compu {0=Cx0_keine_Freigabe (CM_HLR_SIH_Freigabe_Fond_Cx0_keine_Freigabe), 1=Cx1_Freigabe (CM_HLR_SIH_Freigabe_Fond_Cx1_Freigabe)}, range raw 0..1, transfer-property=TRIGGERED-ON-CHANGE-WITHOUT-REPETITION  # Freigabe des EM für Sitzheizungen hinten
          signal HLR_Sp_Heizung_Freigabe_BT_XIX_HLR_02_XIX_E3V_EVCANFD: start 26, 1 bit, little-endian, data-type-policy=OVERRIDE, i-signal-type=PRIMITIVE, init-value=0, base-type=BT_HLR_Sp_Heizung_Freigabe_BT, compu {0=Cx0_keine_Freigabe (CM_HLR_Sp_Heizung_Freigabe_BT_Cx0_keine_Freigabe), 1=Cx1_Freigabe (CM_HLR_Sp_Heizung_Freigabe_BT_Cx1_Freigabe)}, range raw 0..1, transfer-property=TRIGGERED-ON-CHANGE-WITHOUT-REPETITION  # Freigabe der Außenspiegelheizung Beifahrerseite
          signal HLR_Sp_Heizung_Freigabe_FT_XIX_HLR_02_XIX_E3V_EVCANFD: start 27, 1 bit, little-endian, data-type-policy=OVERRIDE, i-signal-type=PRIMITIVE, init-value=0, base-type=BT_HLR_Sp_Heizung_Freigabe_FT, compu {0=Cx0_keine_Freigabe (CM_HLR_Sp_Heizung_Freigabe_FT_Cx0_keine_Freigabe), 1=Cx1_Freigabe (CM_HLR_Sp_Heizung_Freigabe_FT_Cx1_Freigabe)}, range raw 0..1, transfer-property=TRIGGERED-ON-CHANGE-WITHOUT-REPETITION  # Freigabe des EEM für die Außenspiegelheizung rechtsFreigabe der Außenspiegelheizung Fahrerseite
          signal HLR_KRH_Freigabe_VL_XIX_HLR_02_XIX_E3V_EVCANFD: start 28, 2 bit, little-endian, data-type-policy=OVERRIDE, i-signal-type=PRIMITIVE, init-value=0, base-type=BT_HLR_KRH_Freigabe_VL, compu {0=Cx0_0_Prozent (CM_HLR_KRH_Freigabe_VL_Cx0_0_Prozent), 1=Cx1_33_Prozent (CM_HLR_KRH_Freigabe_VL_Cx1_33_Prozent), 2=Cx2_66_Prozent (CM_HLR_KRH_Freigabe_VL_Cx2_66_Prozent), 3=Cx3_100_Prozent (CM_HLR_KRH_Freigabe_VL_Cx3_100_Prozent)}, range raw 0..3, transfer-property=TRIGGERED-ON-CHANGE-WITHOUT-REPETITION  # Freigabe des EEM für die Kopfraumheizung vorne links
          signal HLR_KRH_Freigabe_VR_XIX_HLR_02_XIX_E3V_EVCANFD: start 30, 2 bit, little-endian, data-type-policy=OVERRIDE, i-signal-type=PRIMITIVE, init-value=0, base-type=BT_HLR_KRH_Freigabe_VR, compu {0=Cx0_0_Prozent (CM_HLR_KRH_Freigabe_VR_Cx0_0_Prozent), 1=Cx1_33_Prozent (CM_HLR_KRH_Freigabe_VR_Cx1_33_Prozent), 2=Cx2_66_Prozent (CM_HLR_KRH_Freigabe_VR_Cx2_66_Prozent), 3=Cx3_100_Prozent (CM_HLR_KRH_Freigabe_VR_Cx3_100_Prozent)}, range raw 0..3, transfer-property=TRIGGERED-ON-CHANGE-WITHOUT-REPETITION  # Freigabe des EEM für die Kopfraumheizung vorne rechts
          signal HLR_SIH_Freigabe_VL_XIX_HLR_02_XIX_E3V_EVCANFD: start 32, 2 bit, little-endian, data-type-policy=OVERRIDE, i-signal-type=PRIMITIVE, init-value=0, base-type=BT_HLR_SIH_Freigabe_VL, compu {0=Cx0_0_Prozent (CM_HLR_SIH_Freigabe_VL_Cx0_0_Prozent), 1=Cx1_33_Prozent (CM_HLR_SIH_Freigabe_VL_Cx1_33_Prozent), 2=Cx2_66_Prozent (CM_HLR_SIH_Freigabe_VL_Cx2_66_Prozent), 3=Cx3_100_Prozent (CM_HLR_SIH_Freigabe_VL_Cx3_100_Prozent)}, range raw 0..3, transfer-property=TRIGGERED-ON-CHANGE-WITHOUT-REPETITION, to Klima(timeout 5 s)  # Freigabe des EEM für die Sitzheizung vorne links
          signal HLR_SIH_Freigabe_VR_XIX_HLR_02_XIX_E3V_EVCANFD: start 34, 2 bit, little-endian, data-type-policy=OVERRIDE, i-signal-type=PRIMITIVE, init-value=0, base-type=BT_HLR_SIH_Freigabe_VR, compu {0=Cx0_0_Prozent (CM_HLR_SIH_Freigabe_VR_Cx0_0_Prozent), 1=Cx1_33_Prozent (CM_HLR_SIH_Freigabe_VR_Cx1_33_Prozent), 2=Cx2_66_Prozent (CM_HLR_SIH_Freigabe_VR_Cx2_66_Prozent), 3=Cx3_100_Prozent (CM_HLR_SIH_Freigabe_VR_Cx3_100_Prozent)}, range raw 0..3, transfer-property=TRIGGERED-ON-CHANGE-WITHOUT-REPETITION, to Klima(timeout 5 s)  # Freigabe des EEM für die Sitzheizung vorne rechts
          signal HLR_SIH_Freigabe_HL_XIX_HLR_02_XIX_E3V_EVCANFD: start 36, 2 bit, little-endian, data-type-policy=OVERRIDE, i-signal-type=PRIMITIVE, init-value=0, base-type=BT_HLR_SIH_Freigabe_HL, compu {0=Cx0_0_Prozent (CM_HLR_SIH_Freigabe_HL_Cx0_0_Prozent), 1=Cx1_33_Prozent (CM_HLR_SIH_Freigabe_HL_Cx1_33_Prozent), 2=Cx2_66_Prozent (CM_HLR_SIH_Freigabe_HL_Cx2_66_Prozent), 3=Cx3_100_Prozent (CM_HLR_SIH_Freigabe_HL_Cx3_100_Prozent)}, range raw 0..3, transfer-property=TRIGGERED-ON-CHANGE-WITHOUT-REPETITION, to Klima(timeout 5 s)  # Freigabe des EEM für die Sitzheizung hinten links
          signal HLR_SIH_Freigabe_HR_XIX_HLR_02_XIX_E3V_EVCANFD: start 38, 2 bit, little-endian, data-type-policy=OVERRIDE, i-signal-type=PRIMITIVE, init-value=0, base-type=BT_HLR_SIH_Freigabe_HR, compu {0=Cx0_0_Prozent (CM_HLR_SIH_Freigabe_HR_Cx0_0_Prozent), 1=Cx1_33_Prozent (CM_HLR_SIH_Freigabe_HR_Cx1_33_Prozent), 2=Cx2_66_Prozent (CM_HLR_SIH_Freigabe_HR_Cx2_66_Prozent), 3=Cx3_100_Prozent (CM_HLR_SIH_Freigabe_HR_Cx3_100_Prozent)}, range raw 0..3, transfer-property=TRIGGERED-ON-CHANGE-WITHOUT-REPETITION, to Klima(timeout 5 s)  # Freigabe des EEM für die Sitzheizung hinten rechts
          signal HLR_SIL_Freigabe_VL_XIX_HLR_02_XIX_E3V_EVCANFD: start 40, 2 bit, little-endian, data-type-policy=OVERRIDE, i-signal-type=PRIMITIVE, init-value=0, base-type=BT_HLR_SIL_Freigabe_VL, compu {0=Cx0_0_Prozent (CM_HLR_SIL_Freigabe_VL_Cx0_0_Prozent), 1=Cx1_33_Prozent (CM_HLR_SIL_Freigabe_VL_Cx1_33_Prozent), 2=Cx2_66_Prozent (CM_HLR_SIL_Freigabe_VL_Cx2_66_Prozent), 3=Cx3_100_Prozent (CM_HLR_SIL_Freigabe_VL_Cx3_100_Prozent)}, range raw 0..3, transfer-property=TRIGGERED-ON-CHANGE-WITHOUT-REPETITION, to Klima(timeout 5 s)  # Freigabe des EEM für die Sitzlüftung Vorne Links
          signal HLR_SIL_Freigabe_VR_XIX_HLR_02_XIX_E3V_EVCANFD: start 42, 2 bit, little-endian, data-type-policy=OVERRIDE, i-signal-type=PRIMITIVE, init-value=0, base-type=BT_HLR_SIL_Freigabe_VR, compu {0=Cx0_0_Prozent (CM_HLR_SIL_Freigabe_VR_Cx0_0_Prozent), 1=Cx1_33_Prozent (CM_HLR_SIL_Freigabe_VR_Cx1_33_Prozent), 2=Cx2_66_Prozent (CM_HLR_SIL_Freigabe_VR_Cx2_66_Prozent), 3=Cx3_100_Prozent (CM_HLR_SIL_Freigabe_VR_Cx3_100_Prozent)}, range raw 0..3, transfer-property=TRIGGERED-ON-CHANGE-WITHOUT-REPETITION, to Klima(timeout 5 s)  # Freigabe des EEM für die Sitzlüftung vorne Rechts
          signal HLR_SIL_Freigabe_HL_XIX_HLR_02_XIX_E3V_EVCANFD: start 44, 2 bit, little-endian, data-type-policy=OVERRIDE, i-signal-type=PRIMITIVE, init-value=0, base-type=BT_HLR_SIL_Freigabe_HL, compu {0=Cx0_0_Prozent (CM_HLR_SIL_Freigabe_HL_Cx0_0_Prozent), 1=Cx1_33_Prozent (CM_HLR_SIL_Freigabe_HL_Cx1_33_Prozent), 2=Cx2_66_Prozent (CM_HLR_SIL_Freigabe_HL_Cx2_66_Prozent), 3=Cx3_100_Prozent (CM_HLR_SIL_Freigabe_HL_Cx3_100_Prozent)}, range raw 0..3, transfer-property=TRIGGERED-ON-CHANGE-WITHOUT-REPETITION, to Klima(timeout 5 s)  # Freigabe des EEM für die Sitzbelüftung hinten links
          signal HLR_SIL_Freigabe_HR_XIX_HLR_02_XIX_E3V_EVCANFD: start 46, 2 bit, little-endian, data-type-policy=OVERRIDE, i-signal-type=PRIMITIVE, init-value=0, base-type=BT_HLR_SIL_Freigabe_HR, compu {0=Cx0_0_Prozent (CM_HLR_SIL_Freigabe_HR_Cx0_0_Prozent), 1=Cx1_33_Prozent (CM_HLR_SIL_Freigabe_HR_Cx1_33_Prozent), 2=Cx2_66_Prozent (CM_HLR_SIL_Freigabe_HR_Cx2_66_Prozent), 3=Cx3_100_Prozent (CM_HLR_SIL_Freigabe_HR_Cx3_100_Prozent)}, range raw 0..3, transfer-property=TRIGGERED-ON-CHANGE-WITHOUT-REPETITION, to Klima(timeout 5 s)  # Freigabe des EEM für die Sitzlüftung hinten rechts
          signal HLR_FSH_Freigabe_XIX_HLR_02_XIX_E3V_EVCANFD: start 48, 6 bit, little-endian, data-type-policy=OVERRIDE, i-signal-type=PRIMITIVE, init-value=0, base-type=BT_HLR_FSH_Freigabe, invalid-value=Invalid_HLR_FSH_Freigabe_XIX_HLR_02_XIX_E3V_EVCANFD:63, compu {0=Cx0_AUS (CM_HLR_FSH_Freigabe_Cx0_AUS), phys=raw*20 for raw 1..62, 63=Cx3f_Fehler (CM_HLR_FSH_Freigabe_Cx3f_Fehler); unit Unit_Watt}, range phys 20..1240 Unit_Watt, raw 0..63, unit=Unit_Watt, transfer-property=TRIGGERED-ON-CHANGE-WITHOUT-REPETITION, to Klima(timeout 5 s)  # Freigabe des EEM für die Frontscheibenheizung
          signal HLR_HSH_Freigabe_XIX_HLR_02_XIX_E3V_EVCANFD: start 54, 1 bit, little-endian, data-type-policy=OVERRIDE, i-signal-type=PRIMITIVE, init-value=0, base-type=BT_HLR_HSH_Freigabe, compu {0=Cx0_keine_Freigabe (CM_HLR_HSH_Freigabe_Cx0_keine_Freigabe), 1=Cx1_Freigabe (CM_HLR_HSH_Freigabe_Cx1_Freigabe)}, range raw 0..1, transfer-property=TRIGGERED-ON-CHANGE-WITHOUT-REPETITION, to Klima(timeout 5 s)  # Freigabe des EEM für die Heckscheibenheizung
          signal HLR_LRH_Freigabe_XIX_HLR_02_XIX_E3V_EVCANFD: start 55, 1 bit, little-endian, data-type-policy=OVERRIDE, i-signal-type=PRIMITIVE, init-value=0, base-type=BT_HLR_LRH_Freigabe, compu {0=Cx0_keine_Freigabe (CM_HLR_LRH_Freigabe_Cx0_keine_Freigabe), 1=Cx1_Freigabe (CM_HLR_LRH_Freigabe_Cx1_Freigabe)}, range raw 0..1, transfer-property=TRIGGERED-ON-CHANGE-WITHOUT-REPETITION, to Klima(timeout 5 s)  # Freigabe für die Lenkradheizung
          signal HLR_PTC_linear_Freigabe_XIX_HLR_02_XIX_E3V_EVCANFD: start 56, 6 bit, little-endian, data-type-policy=OVERRIDE, i-signal-type=PRIMITIVE, init-value=0, base-type=BT_HLR_PTC_linear_Freigabe, invalid-value=Invalid_HLR_PTC_linear_Freigabe_XIX_HLR_02_XIX_E3V_EVCANFD:63, compu {phys=raw*50 for raw 0..62, 63=Cx3f_Fehler (CM_HLR_PTC_linear_Freigabe_Cx3f_Fehler); unit Unit_Watt}, range phys 0..3100 Unit_Watt, raw 0..63, unit=Unit_Watt, transfer-property=TRIGGERED-ON-CHANGE-WITHOUT-REPETITION  # Freigabe des EEM für den linearen PTC-Zuheizer
          signal HLR_PTC_Freigabe_XIX_HLR_02_XIX_E3V_EVCANFD: start 62, 2 bit, little-endian, data-type-policy=OVERRIDE, i-signal-type=PRIMITIVE, init-value=3, base-type=BT_HLR_PTC_Freigabe, compu {0=Cx0_Aus (CM_HLR_PTC_Freigabe_Cx0_Aus), 1=Cx1_Stufe_1 (CM_HLR_PTC_Freigabe_Cx1_Stufe_1), 2=Cx2_Stufe_2 (CM_HLR_PTC_Freigabe_Cx2_Stufe_2), 3=Cx3_Stufe_3 (CM_HLR_PTC_Freigabe_Cx3_Stufe_3)}, range raw 0..3, transfer-property=TRIGGERED-ON-CHANGE-WITHOUT-REPETITION  # Freigabe des elektrischen Energiemanagements für das gestufte/geregelte PTC
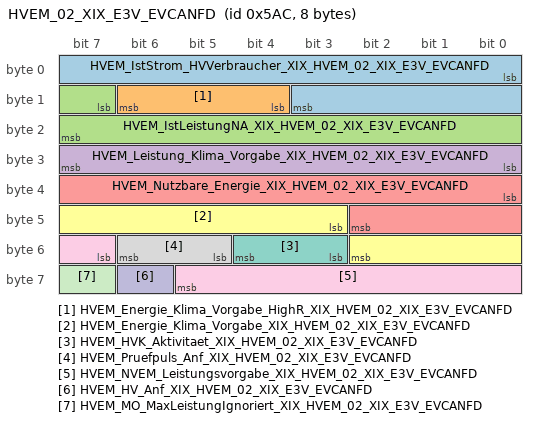
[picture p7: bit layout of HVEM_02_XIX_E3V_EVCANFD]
      frame HVEM_02_XIX_E3V_EVCANFD: id 0x5AC, to Klima, frame-length=8, can-addressing-mode=STANDARD, can-frame-rx-behavior=CAN-FD, can-frame-tx-behavior=CAN-FD
        pdu HVEM_02_XIX_E3V_EVCANFD: length=8, transmission-mode-true-timing=cyclic-timing={time-offset=0.0, time-period=0.1}, unused-bit-pattern=0
          signal HVEM_IstStrom_HVVerbraucher_XIX_HVEM_02_XIX_E3V_EVCANFD: start 0, 12 bit, little-endian, data-type-policy=OVERRIDE, i-signal-type=PRIMITIVE, init-value=4094, base-type=BT_HVEM_IstStrom_HVVerbraucher, invalid-value=Invalid_HVEM_IstStrom_HVVerbraucher_XIX_HVEM_02_XIX_E3V_EVCANFD:4095, compu {phys=raw*0.1-204.7 for raw 0..4093, 4094=Cxffe_Init (CM_HVEM_IstStrom_HVVerbraucher_Cxffe_Init), 4095=Cxfff_Fehler (CM_HVEM_IstStrom_HVVerbraucher_Cxfff_Fehler); unit Unit_Amper}, range phys -204.7..204.6 Unit_Amper, raw 0..4095, unit=Unit_Amper, transfer-property=PENDING  # Iststromaufnahme der elektrischen Nebenaggregate aus dem HV Zwischenkreis
          signal HVEM_Energie_Klima_Vorgabe_HighR_XIX_HVEM_02_XIX_E3V_EVCANFD: start 12, 3 bit, little-endian, data-type-policy=OVERRIDE, i-signal-type=PRIMITIVE, init-value=6, base-type=BT_HVEM_Energie_Klima_Vorgabe_HighR, invalid-value=Invalid_HVEM_Energie_Klima_Vorgabe_HighR_XIX_HVEM_02_XIX_E3V_EVCANFD:7, compu {phys=raw*10 for raw 0..5, 6=Cx6_Init (CM_HVEM_Energie_Klima_Vorgabe_HighR_Cx6_Init), 7=Cx7_Fehler (CM_HVEM_Energie_Klima_Vorgabe_HighR_Cx7_Fehler); unit Unit_WattHour}, range phys 0..50 Unit_WattHour, raw 0..7, unit=Unit_WattHour, transfer-property=PENDING, to Klima(timeout 1 s)  # Erweiterte Auflösung von 10Wh für Signal HVEM_Energie_Klima_Vorgabe. Signalwert wird zu HVEM_Energie_Klima_Vorgabe Addiert
          signal HVEM_IstLeistungNA_XIX_HVEM_02_XIX_E3V_EVCANFD: start 15, 9 bit, little-endian, data-type-policy=OVERRIDE, i-signal-type=PRIMITIVE, init-value=510, base-type=BT_HVEM_IstLeistungNA, invalid-value=Invalid_HVEM_IstLeistungNA_XIX_HVEM_02_XIX_E3V_EVCANFD:511, compu {phys=raw*50 for raw 0..509, 510=Cx1fe_Init (CM_HVEM_IstLeistungNA_Cx1fe_Init), 511=Cx1ff_Fehler (CM_HVEM_IstLeistungNA_Cx1ff_Fehler); unit Unit_Watt}, range phys 0..25450 Unit_Watt, raw 0..511, unit=Unit_Watt, transfer-property=PENDING  # aktuelle Leistungsaufnahme der Nebenaggregate
          signal HVEM_Leistung_Klima_Vorgabe_XIX_HVEM_02_XIX_E3V_EVCANFD: start 24, 8 bit, little-endian, data-type-policy=OVERRIDE, i-signal-type=PRIMITIVE, init-value=254, base-type=BT_HVEM_Leistung_Klima_Vorgabe, invalid-value=Invalid_HVEM_Leistung_Klima_Vorgabe_XIX_HVEM_02_XIX_E3V_EVCANFD:255, compu {phys=raw*50 for raw 0..253, 254=Cxfe_Init (CM_HVEM_Leistung_Klima_Vorgabe_Cxfe_Init), 255=Cxff_Fehler (CM_HVEM_Leistung_Klima_Vorgabe_Cxff_Fehler); unit Unit_Watt}, range phys 0..12650 Unit_Watt, raw 0..255, unit=Unit_Watt, transfer-property=PENDING, to Klima(timeout 1 s)  # Leistungsvorgabe Thermo (für Kühlen und Heizen)
          signal HVEM_Nutzbare_Energie_XIX_HVEM_02_XIX_E3V_EVCANFD: start 32, 11 bit, little-endian, data-type-policy=OVERRIDE, i-signal-type=PRIMITIVE, init-value=2046, base-type=BT_HVEM_Nutzbare_Energie, invalid-value=Invalid_HVEM_Nutzbare_Energie_XIX_HVEM_02_XIX_E3V_EVCANFD:2047, compu {phys=raw*50 for raw 0..2044, 2045=Cx7fd_Max (CM_HVEM_Nutzbare_Energie_Cx7fd_Max), 2046=Cx7fe_Init (CM_HVEM_Nutzbare_Energie_Cx7fe_Init), 2047=Cx7ff_Fehler (CM_HVEM_Nutzbare_Energie_Cx7ff_Fehler); unit Unit_WattHour}, range phys 0..102200 Unit_WattHour, raw 0..2047, unit=Unit_WattHour, transfer-property=PENDING, to Klima(timeout 1 s)  # Nutzbare Energie welche für Komfortfunktionen vom HVEM freigegeben wird.
          signal HVEM_Energie_Klima_Vorgabe_XIX_HVEM_02_XIX_E3V_EVCANFD: start 43, 8 bit, little-endian, data-type-policy=OVERRIDE, i-signal-type=PRIMITIVE, init-value=254, base-type=BT_HVEM_Energie_Klima_Vorgabe, invalid-value=Invalid_HVEM_Energie_Klima_Vorgabe_XIX_HVEM_02_XIX_E3V_EVCANFD:255, compu {phys=raw*50 for raw 0..253, 254=Cxfe_Init (CM_HVEM_Energie_Klima_Vorgabe_Cxfe_Init), 255=Cxff_Fehler (CM_HVEM_Energie_Klima_Vorgabe_Cxff_Fehler); unit Unit_WattHour}, range phys 0..12650 Unit_WattHour, raw 0..255, unit=Unit_WattHour, transfer-property=PENDING, to Klima(timeout 1 s)  # HVEM-Energievorgabe für Klima-Vorkonditionierung
          signal HVEM_HVK_Aktivitaet_XIX_HVEM_02_XIX_E3V_EVCANFD: start 51, 2 bit, little-endian, data-type-policy=OVERRIDE, i-signal-type=PRIMITIVE, init-value=2, base-type=BT_HVEM_HVK_Aktivitaet, compu {0=Cx0_keine_Aktivitaet (CM_HVEM_HVK_Aktivitaet_Cx0_keine_Aktivitaet), 1=Cx1_Aktivitaet (CM_HVEM_HVK_Aktivitaet_Cx1_Aktivitaet), 2=Cx2_Init (CM_HVEM_HVK_Aktivitaet_Cx2_Init)}, range raw 0..2, transfer-property=PENDING  # Dem HVEM sind HV-Komponenten zugeordnet. Das HVEM übermittelt an den HVK ein Hochvolt –Aktivitätsstatus dieser HV-Komponenten.
          signal HVEM_Pruefpuls_Anf_XIX_HVEM_02_XIX_E3V_EVCANFD: start 53, 2 bit, little-endian, data-type-policy=OVERRIDE, i-signal-type=PRIMITIVE, init-value=3, base-type=BT_HVEM_Pruefpuls_Anf, compu {0=Cx0_Keine_Anforderung (CM_HVEM_Pruefpuls_Anf_Cx0_Keine_Anforderung), 1=Cx1_Anforderung (CM_HVEM_Pruefpuls_Anf_Cx1_Anforderung), 2=Cx2_Reserved (CM_HVEM_Pruefpuls_Anf_Cx2_Reserved), 3=Cx3_Init (CM_HVEM_Pruefpuls_Anf_Cx3_Init)}, range raw 0..3, transfer-property=PENDING  # Prüfpulsanforderung an den HV-Koordinator
          signal HVEM_NVEM_Leistungsvorgabe_XIX_HVEM_02_XIX_E3V_EVCANFD: start 55, 7 bit, little-endian, data-type-policy=OVERRIDE, i-signal-type=PRIMITIVE, init-value=126, base-type=BT_HVEM_NVEM_Leistungsvorgabe, invalid-value=Invalid_HVEM_NVEM_Leistungsvorgabe_XIX_HVEM_02_XIX_E3V_EVCANFD:127, compu {phys=raw*50 for raw 0..125, 126=Cx7e_Init (CM_HVEM_NVEM_Leistungsvorgabe_Cx7e_Init), 127=Cx7f_Fehler (CM_HVEM_NVEM_Leistungsvorgabe_Cx7f_Fehler); unit Unit_Watt}, range phys 0..6250 Unit_Watt, raw 0..127, unit=Unit_Watt, transfer-property=PENDING  # Leistungsvorgabe des HVEM an das NVEM
          signal HVEM_HV_Anf_XIX_HVEM_02_XIX_E3V_EVCANFD: start 62, 1 bit, little-endian, data-type-policy=OVERRIDE, i-signal-type=PRIMITIVE, init-value=0, base-type=BT_HVEM_HV_Anf, compu {0=Cx0_keine_Anforderung (CM_HVEM_HV_Anf_Cx0_keine_Anforderung), 1=Cx1_HV_angefordert (CM_HVEM_HV_Anf_Cx1_HV_angefordert)}, range raw 0..1, transfer-property=PENDING, to Klima(timeout 1 s)  # HV Anforderung des HV Energiemanagements an das MSG
          signal HVEM_MO_MaxLeistungIgnoriert_XIX_HVEM_02_XIX_E3V_EVCANFD: start 63, 1 bit, little-endian, data-type-policy=OVERRIDE, i-signal-type=PRIMITIVE, init-value=0, base-type=BT_HVEM_MO_MaxLeistungIgnoriert, compu {0=Cx0_Max_Leistung_nicht_ignoriert (CM_HVEM_MO_MaxLeistungIgnoriert_Cx0_Max_Leistung_nicht_ignoriert), 1=Cx1_Max_Leistung_ignoriert (CM_HVEM_MO_MaxLeistungIgnoriert_Cx1_Max_Leistung_ignoriert)}, range raw 0..1, transfer-property=PENDING  # Rueckmeldung des HVEM ob die vorgegebene MaxLeistung vom MSG eingehalten wird.
      frame HVEM_04_XIX_E3V_EVCANFD: id 0x569, to Klima, frame-length=8, can-addressing-mode=STANDARD, can-frame-rx-behavior=CAN-FD, can-frame-tx-behavior=CAN-FD
        pdu HVEM_04_XIX_E3V_EVCANFD: length=8, minimum-delay=0.05, transmission-mode-true-timing={cyclic-timing={time-offset=0.0, time-period=0.5}, event-controlled-timing={number-of-repetitions=0, repetition-period=0.0}}, unused-bit-pattern=0
          signal HVEM_ZusatzMinLeistungNA_Anf_XIX_HVEM_04_XIX_E3V_EVCANFD: start 0, 9 bit, little-endian, data-type-policy=OVERRIDE, i-signal-type=PRIMITIVE, init-value=510, base-type=BT_HVEM_ZusatzMinLeistungNA_Anf, compu {phys=raw*50 for raw 0..509, 510=Cx1fe_Init (CM_HVEM_ZusatzMinLeistungNA_Anf_Cx1fe_Init); unit Unit_Watt}, range phys 0..25450 Unit_Watt, raw 0..510, unit=Unit_Watt, transfer-property=TRIGGERED-ON-CHANGE-WITHOUT-REPETITION  # Zusätzliche Leistungsanfrage des HVEM an das Antriebsystem in kritischen Energiezuständen für hoch priorisierte Systemanforderungen während der Fahrbereitschaft.
          signal HVEM_Betriebsart_XIX_HVEM_04_XIX_E3V_EVCANFD: start 9, 3 bit, little-endian, data-type-policy=OVERRIDE, i-signal-type=PRIMITIVE, init-value=0, base-type=BT_HVEM_Betriebsart, compu {0=Cx0_Standby (CM_HVEM_Betriebsart_Cx0_Standby), 1=Cx1_HV_Aktiv (CM_HVEM_Betriebsart_Cx1_HV_Aktiv), 3=Cx3_Fahrbereit (CM_HVEM_Betriebsart_Cx3_Fahrbereit), 4=Cx4_HV_Laden (CM_HVEM_Betriebsart_Cx4_HV_Laden), 5=Cx5_Autonom (CM_HVEM_Betriebsart_Cx5_Autonom)}, range raw 0..5, transfer-property=PENDING  # Information über die seitens HVEM aktive Betriebsart für die Leistungsverteilung
          signal HVEM_NVLeistungEmpf_XIX_HVEM_04_XIX_E3V_EVCANFD: start 12, 4 bit, little-endian, data-type-policy=OVERRIDE, i-signal-type=PRIMITIVE, init-value=0, base-type=BT_HVEM_NVLeistungEmpf, compu {phys=raw*100 for raw 0..15; unit Unit_Watt}, range phys 0..1500 Unit_Watt, raw 0..15, unit=Unit_Watt, transfer-property=TRIGGERED-ON-CHANGE-WITHOUT-REPETITION  # Maximaler Sollwert der aktuellen Leistung der NV-Seite des DCDC-Wandlers.
          signal HVEM_DCDC_Freigabe_XIX_HVEM_04_XIX_E3V_EVCANFD: start 16, 1 bit, little-endian, data-type-policy=OVERRIDE, i-signal-type=PRIMITIVE, init-value=0, base-type=BT_HVEM_DCDC_Freigabe, compu {0=Cx0_keine_Freigabe (CM_HVEM_DCDC_Freigabe_Cx0_keine_Freigabe), 1=Cx1_Freigabe (CM_HVEM_DCDC_Freigabe_Cx1_Freigabe)}, range raw 0..1, transfer-property=PENDING  # Freigabe des DCDC wenn das Fzg nicht Fahrbereit ist.
          signal HVEM_KlimaMaxHVStrom_XIX_HVEM_04_XIX_E3V_EVCANFD: start 17, 5 bit, little-endian, data-type-policy=OVERRIDE, i-signal-type=PRIMITIVE, init-value=0, base-type=BT_HVEM_KlimaMaxHVStrom, compu {phys=raw for raw 0..31; unit Unit_Amper}, range phys 0..31 Unit_Amper, raw 0..31, unit=Unit_Amper, transfer-property=TRIGGERED-ON-CHANGE-WITHOUT-REPETITION  # Kommuniziert dem Klimasteuergerät den max. Aufnahmestrom
          signal HVEM_Ladesteckerentr_Anf_XIX_HVEM_04_XIX_E3V_EVCANFD: start 23, 1 bit, little-endian, data-type-policy=OVERRIDE, i-signal-type=PRIMITIVE, init-value=0, base-type=BT_HVEM_Ladesteckerentr_Anf, compu {0=Cx0_keine_Anforderung (CM_HVEM_Ladesteckerentr_Anf_Cx0_keine_Anforderung), 1=Cx1_Anf_Ladestecker_Entr (CM_HVEM_Ladesteckerentr_Anf_Cx1_Anf_Ladestecker_Entr)}, range raw 0..1, transfer-property=TRIGGERED-ON-CHANGE-WITHOUT-REPETITION  # Anforderung Ladestecker entriegeln nach ZV Auf Befehl
          signal HVEM_LeistungsAnf_XIX_HVEM_04_XIX_E3V_EVCANFD: start 24, 1 bit, little-endian, data-type-policy=OVERRIDE, i-signal-type=PRIMITIVE, init-value=0, base-type=BT_HVEM_LeistungsAnf, compu {0=Cx0_nicht_angefordert (CM_HVEM_LeistungsAnf_Cx0_nicht_angefordert), 1=Cx1_angefordert (CM_HVEM_LeistungsAnf_Cx1_angefordert)}, range raw 0..1, transfer-property=TRIGGERED-ON-CHANGE-WITHOUT-REPETITION  # Anforderung an NV-EM zur Erhöhung der Performance den Energieverbrauch auf der NV-Seite zu reduzieren.
          signal HVEM_Nachlad_Status_XIX_HVEM_04_XIX_E3V_EVCANFD: start 25, 2 bit, little-endian, data-type-policy=OVERRIDE, i-signal-type=PRIMITIVE, init-value=3, base-type=BT_HVEM_Nachlad_Status, compu {0=Cx0_nicht_moeglich_Fehler (CM_HVEM_Nachlad_Status_Cx0_nicht_moeglich_Fehler) (nicht_moeglich__Fehler), 1=Cx1_moeglich_begonnen (CM_HVEM_Nachlad_Status_Cx1_moeglich_begonnen) (moeglich__begonnen), 2=Cx2_Beendet (CM_HVEM_Nachlad_Status_Cx2_Beendet), 3=Cx3_Init (CM_HVEM_Nachlad_Status_Cx3_Init)}, range raw 0..3, transfer-property=TRIGGERED-ON-CHANGE-WITHOUT-REPETITION  # Status der Umsetzung der Nachladeanforderung der NV-Seite.
          signal HVEM_Abschaltstatus_XIX_HVEM_04_XIX_E3V_EVCANFD: start 27, 3 bit, little-endian, data-type-policy=OVERRIDE, i-signal-type=PRIMITIVE, init-value=7, base-type=BT_HVEM_Abschaltstatus, compu {0=Cx0_100 (CM_HVEM_Abschaltstatus_Cx0_100), 1=Cx1_75 (CM_HVEM_Abschaltstatus_Cx1_75), 2=Cx2_50 (CM_HVEM_Abschaltstatus_Cx2_50), 3=Cx3_25 (CM_HVEM_Abschaltstatus_Cx3_25), 7=Cx7_Init (CM_HVEM_Abschaltstatus_Cx7_Init)}, range raw 0..7, transfer-property=TRIGGERED-ON-CHANGE-WITHOUT-REPETITION  # Status der Reduzierungsstufen der Klimakomponenten beim Laden 0 = 100% (keine Reduzierung) 1 = 75% 2 = 50% 3 = 25% 7 = Init
          signal HVEM_Anf_ReichweiteNV_XIX_HVEM_04_XIX_E3V_EVCANFD: start 30, 2 bit, little-endian, data-type-policy=OVERRIDE, i-signal-type=PRIMITIVE, init-value=0, base-type=BT_HVEM_Anf_ReichweiteNV, invalid-value=Invalid_HVEM_Anf_ReichweiteNV_XIX_HVEM_04_XIX_E3V_EVCANFD:3, compu {0=Cx0_keine_Massnahme_notwendig (CM_HVEM_Anf_ReichweiteNV_Cx0_keine_Massnahme_notwendig), 1=Cx1_Reduktion_Stufe_1 (CM_HVEM_Anf_ReichweiteNV_Cx1_Reduktion_Stufe_1), 2=Cx2_Reduktion_Stufe_2 (CM_HVEM_Anf_ReichweiteNV_Cx2_Reduktion_Stufe_2), 3=Cx3_Fehler (CM_HVEM_Anf_ReichweiteNV_Cx3_Fehler)}, range raw 0..3, transfer-property=TRIGGERED-ON-CHANGE-WITHOUT-REPETITION  # Anforderung an NV-EM zur Erhöhung der Reichweite den Energieverbrauch auf der NV-Seite zu reduzieren.
          signal HVEM_WunschLeistungNA_Anf_XIX_HVEM_04_XIX_E3V_EVCANFD: start 32, 9 bit, little-endian, data-type-policy=OVERRIDE, i-signal-type=PRIMITIVE, init-value=510, base-type=BT_HVEM_WunschLeistungNA_Anf, compu {phys=raw*50 for raw 0..509, 510=Cx1fe_Init (CM_HVEM_WunschLeistungNA_Anf_Cx1fe_Init); unit Unit_Watt}, range phys 0..25450 Unit_Watt, raw 0..510, unit=Unit_Watt, transfer-property=TRIGGERED-ON-CHANGE-WITHOUT-REPETITION  # Niederpriorisierte Leistungsanforderung an das Antriebssystem. Diese Wunsch-Leistung ist immer größer gleich der geforderten Min-Leistung.
          signal HVEM_Text_1_XIX_HVEM_04_XIX_E3V_EVCANFD: start 41, 1 bit, little-endian, data-type-policy=OVERRIDE, i-signal-type=PRIMITIVE, init-value=0, base-type=BT_HVEM_Text_1, compu {0=Cx0_kein_Text (CM_HVEM_Text_1_Cx0_kein_Text), 1=Cx1_Text (CM_HVEM_Text_1_Cx1_Text)}, range raw 0..1, transfer-property=TRIGGERED-ON-CHANGE-WITHOUT-REPETITION  # Meldung bei einem Anzeige SOC<10% ("Achtung Batterie laden. Funktionen eingeschränkt")
          signal HVEM_Nachladen_Anf_XIX_HVEM_04_XIX_E3V_EVCANFD: start 42, 1 bit, little-endian, data-type-policy=OVERRIDE, i-signal-type=PRIMITIVE, init-value=0, base-type=BT_HVEM_Nachladen_Anf, compu {0=Cx0_keine_Anforderung (CM_HVEM_Nachladen_Anf_Cx0_keine_Anforderung), 1=Cx1_Nachladen_angefordert (CM_HVEM_Nachladen_Anf_Cx1_Nachladen_angefordert)}, range raw 0..1, transfer-property=TRIGGERED-ON-CHANGE-WITHOUT-REPETITION  # Anforderung für HV Laden bei gestecktem Stecker und deaktivierter Ladeanforderung
          signal HVEM_FreigabeKlimatisierung_XIX_HVEM_04_XIX_E3V_EVCANFD: start 43, 2 bit, little-endian, data-type-policy=OVERRIDE, i-signal-type=PRIMITIVE, init-value=2, base-type=BT_HVEM_FreigabeKlimatisierung, invalid-value=Invalid_HVEM_FreigabeKlimatisierung_XIX_HVEM_04_XIX_E3V_EVCANFD:3, compu {0=Cx0_keine_Freigabe (CM_HVEM_FreigabeKlimatisierung_Cx0_keine_Freigabe), 1=Cx1_Freigabe (CM_HVEM_FreigabeKlimatisierung_Cx1_Freigabe), 2=Cx2_Init (CM_HVEM_FreigabeKlimatisierung_Cx2_Init), 3=Cx3_Fehler (CM_HVEM_FreigabeKlimatisierung_Cx3_Fehler)}, range raw 0..3, transfer-property=TRIGGERED-ON-CHANGE-WITHOUT-REPETITION, to Klima(timeout 5 s)  # Klimatisierung freigeben
          signal HVEM_FreigabeBattHeizung_XIX_HVEM_04_XIX_E3V_EVCANFD: start 45, 2 bit, little-endian, data-type-policy=OVERRIDE, i-signal-type=PRIMITIVE, init-value=2, base-type=BT_HVEM_FreigabeBattHeizung, invalid-value=Invalid_HVEM_FreigabeBattHeizung_XIX_HVEM_04_XIX_E3V_EVCANFD:3, compu {0=Cx0_keine_Freigabe (CM_HVEM_FreigabeBattHeizung_Cx0_keine_Freigabe), 1=Cx1_Freigabe (CM_HVEM_FreigabeBattHeizung_Cx1_Freigabe), 2=Cx2_Init (CM_HVEM_FreigabeBattHeizung_Cx2_Init), 3=Cx3_Fehler (CM_HVEM_FreigabeBattHeizung_Cx3_Fehler)}, range raw 0..3, transfer-property=TRIGGERED-ON-CHANGE-WITHOUT-REPETITION, to Klima(timeout 5 s)  # Freigabe des HVEM für die Batterieheizung
          signal HVEM_MinLeistungNA_Anf_XIX_HVEM_04_XIX_E3V_EVCANFD: start 47, 9 bit, little-endian, data-type-policy=OVERRIDE, i-signal-type=PRIMITIVE, init-value=510, base-type=BT_HVEM_MinLeistungNA_Anf, compu {phys=raw*50 for raw 0..509, 510=Cx1fe_Init (CM_HVEM_MinLeistungNA_Anf_Cx1fe_Init); unit Unit_Watt}, range phys 0..25450 Unit_Watt, raw 0..510, unit=Unit_Watt, transfer-property=TRIGGERED-ON-CHANGE-WITHOUT-REPETITION  # Leistungsanforderung des HVEM in Richtung Antrieb. Diese Leistung muss der Antrieb für hochpriorisierte HV-Funktionen vorhalten.
          signal HVEM_Leistung_Bat_Kond_Vorgabe_XIX_HVEM_04_XIX_E3V_EVCANFD: start 56, 8 bit, little-endian, data-type-policy=OVERRIDE, i-signal-type=PRIMITIVE, init-value=254, base-type=BT_HVEM_Leistung_Bat_Kond_Vorgabe, compu {phys=raw*50 for raw 0..253, 254=Cxfe_Init (CM_HVEM_Leistung_Bat_Kond_Vorgabe_Cxfe_Init); unit Unit_Watt}, range phys 0..12650 Unit_Watt, raw 0..254, unit=Unit_Watt, transfer-property=PENDING, to Klima(timeout 5 s)  # elektr. Leistungsvorgabe Thermo Batterie
      frame HVK_01_XIX_E3V_EVCANFD: id 0x503, to Klima, frame-length=8, can-addressing-mode=STANDARD, can-frame-rx-behavior=CAN-FD, can-frame-tx-behavior=CAN-FD
        pdu HVK_01_XIX_E3V_EVCANFD: length=8, minimum-delay=0.01, transmission-mode-true-timing={cyclic-timing={time-offset=0.0, time-period=0.1}, event-controlled-timing={number-of-repetitions=0, repetition-period=0.0}}, unused-bit-pattern=0
          signal HVK_01_CRC_XIX_HVK_01_XIX_E3V_EVCANFD: start 0, 8 bit, little-endian, data-type-policy=OVERRIDE, i-signal-type=PRIMITIVE, base-type=BT_HVK_01_CRC, compu {phys=raw for raw 0..255}, range phys 0..255, raw 0..255, transfer-property=PENDING  # Für MLB: "Berechnung siehe Lastenheft "Kommunikationsabsicherung für FlexRay und CAN"" Ab MQB und MLBevo: "Berechnung siehe Lastenheft "End-to-End Kommunikationsabsicherung"" Endwerte siehe Begleitdokument "S-PDU Kennungsfolgen"
          signal HVK_01_BZ_XIX_HVK_01_XIX_E3V_EVCANFD: start 8, 4 bit, little-endian, data-type-policy=OVERRIDE, i-signal-type=PRIMITIVE, base-type=BT_HVK_01_BZ, compu {phys=raw for raw 0..15}, range phys 0..15, raw 0..15, transfer-property=PENDING
          signal HVK_Istmodus_Anf_XIX_HVK_01_XIX_E3V_EVCANFD: start 12, 1 bit, little-endian, data-type-policy=OVERRIDE, i-signal-type=PRIMITIVE, init-value=0, base-type=BT_HVK_Istmodus_Anf, compu {0=Cx0_nicht_angefordert (CM_HVK_Istmodus_Anf_Cx0_nicht_angefordert), 1=Cx1_angefordert (CM_HVK_Istmodus_Anf_Cx1_angefordert)}, range raw 0..1, transfer-property=TRIGGERED-ON-CHANGE-WITHOUT-REPETITION  # HVK-Anforderung an alle HV-Komponenten deren Istmodus im schnellen Zyklus (Inhibitzeit) zu senden.
          signal HVK_TN1_Sollmodus_XIX_HVK_01_XIX_E3V_EVCANFD: start 13, 2 bit, little-endian, data-type-policy=OVERRIDE, i-signal-type=PRIMITIVE, init-value=3, base-type=BT_HVK_TN1_Sollmodus, compu {0=Cx0_HV_Off (CM_HVK_TN1_Sollmodus_Cx0_HV_Off), 1=Cx1_HV_On (CM_HVK_TN1_Sollmodus_Cx1_HV_On), 2=Cx2_reserviert (CM_HVK_TN1_Sollmodus_Cx2_reserviert), 3=Cx3_Initialisierung (CM_HVK_TN1_Sollmodus_Cx3_Initialisierung)}, range raw 0..3, transfer-property=TRIGGERED-ON-CHANGE-WITHOUT-REPETITION  # Angeforderter Sollmodus der Steuereinheit für das Schütze des Teilnetz1 "Ladepfad": 0 : HV_Off 1 : HV_On (Schütz geschlossen) 2 : reserviert 3 : Init (CAN-Initialisierung)
          signal HVK_Vorladung_aktiv_XIX_HVK_01_XIX_E3V_EVCANFD: start 15, 1 bit, little-endian, data-type-policy=OVERRIDE, i-signal-type=PRIMITIVE, init-value=0, base-type=BT_HVK_Vorladung_aktiv, compu {0=Cx0_Vorladung_nicht_aktiv (CM_HVK_Vorladung_aktiv_Cx0_Vorladung_nicht_aktiv), 1=Cx1_Vorladung_aktiv (CM_HVK_Vorladung_aktiv_Cx1_Vorladung_aktiv)}, range raw 0..1, transfer-property=TRIGGERED-ON-CHANGE-WITHOUT-REPETITION, to Klima(timeout 1 s)  # Systeminformation, dass aktiv vorgeladen wird
          signal HVK_BMS_Sollmodus_XIX_HVK_01_XIX_E3V_EVCANFD: start 24, 3 bit, little-endian, data-type-policy=OVERRIDE, i-signal-type=PRIMITIVE, init-value=7, base-type=BT_HVK_BMS_Sollmodus, compu {0=Cx0_HV_Off (CM_HVK_BMS_Sollmodus_Cx0_HV_Off), 1=Cx1_HV_On (CM_HVK_BMS_Sollmodus_Cx1_HV_On), 3=Cx3_AC_Laden_erw (CM_HVK_BMS_Sollmodus_Cx3_AC_Laden_erw), 4=Cx4_AC_Laden (CM_HVK_BMS_Sollmodus_Cx4_AC_Laden), 6=Cx6_DC_Laden (CM_HVK_BMS_Sollmodus_Cx6_DC_Laden), 7=Cx7_Init (CM_HVK_BMS_Sollmodus_Cx7_Init)}, range raw 0..7, transfer-property=TRIGGERED-ON-CHANGE-WITHOUT-REPETITION  # Angeforderter Sollmodus der HV-Batterie: 0 : HV_Off 1 : HV_On (HS geschlossen) 2 : nicht belegbar 3 : AC-Laden_erw (HS +AC_2-Schütze geschlossen) 4 : AC-Laden (HS +AC-Schütze geschlossen) 5 : nicht belegbar 6 : DC-Laden (HS + DC-Schütze geschlossen) 7 : Init (CAN-Initialisierung) Info: "nicht belegbar" d.h. Sollmodus nicht relevant für HVK
          signal HVK_DCDC_Sollmodus_XIX_HVK_01_XIX_E3V_EVCANFD: start 27, 3 bit, little-endian, data-type-policy=OVERRIDE, i-signal-type=PRIMITIVE, init-value=7, base-type=BT_HVK_DCDC_Sollmodus, compu {0=Cx0_Standby (CM_HVK_DCDC_Sollmodus_Cx0_Standby), 1=Cx1_HV_On_Vorladen (CM_HVK_DCDC_Sollmodus_Cx1_HV_On_Vorladen), 2=Cx2_Tiefsetzen (CM_HVK_DCDC_Sollmodus_Cx2_Tiefsetzen), 3=Cx3_Hochsetzen (CM_HVK_DCDC_Sollmodus_Cx3_Hochsetzen), 4=Cx4_Pruefpuls_12V (CM_HVK_DCDC_Sollmodus_Cx4_Pruefpuls_12V), 6=Cx6_Pruefpuls_DC_Laden (CM_HVK_DCDC_Sollmodus_Cx6_Pruefpuls_DC_Laden), 7=Cx7_Initialisierung (CM_HVK_DCDC_Sollmodus_Cx7_Initialisierung)}, range raw 0..7, transfer-property=TRIGGERED-ON-CHANGE-WITHOUT-REPETITION  # angeforderte Soll-Betriebsart des DC/DC-Wandlers: 0: Standby; Kommunikation aktiv 1: Zwischenkreis des HV-Netzes wird vorgeladen; HV-Netz wird aktiviert und darf nicht belastet werden. 2: Tiefsetzen (HV --> BN 14,4V) Sollwertvorgabe projektabhängig vom BSG/BCM über Lin/BSS oder vom MSG über 'MO_DC_SollSpannung_NV' bzw. 'MY2_DC_uSetPLV' (PQ35/PL71: Sollwertvorgabe vom BSG) 3: Hochsetzen; Nachladen des HV-Energiespeichers aus dem NV-Energiespeicher 4: Prüfpuls für die 12V-Bordnetzdiagnose. Stromvorgabe kommt von 12V-Seite 5: nicht verfügbar / Rückmeldesignal für internen Fehler DC/DC-Wandler 6: Pruefpuls auf HV-Spannung von <60V durch den DCDC für die Prüfung der Ladeinfrastruktur vor dem Start des DC-Ladevorgangs 7: MSG befindet sich in der Init-Phase; aktuelle Signalwerte nicht gültig; DC/DC soll aktuellen Modus beibehalten (Beibehalten des aktuellen Modus ohne gültigen Sollmodus nur für eine maximale Dauer erlaubt t.b.d.)
          signal HVK_EKK_Sollmodus_XIX_HVK_01_XIX_E3V_EVCANFD: start 30, 3 bit, little-endian, data-type-policy=OVERRIDE, i-signal-type=PRIMITIVE, init-value=7, base-type=BT_HVK_EKK_Sollmodus, compu {0=Cx0_Keine_Freigabe (CM_HVK_EKK_Sollmodus_Cx0_Keine_Freigabe), 1=Cx1_Freigabe (CM_HVK_EKK_Sollmodus_Cx1_Freigabe), 2=Cx2_Freigabe_ausgesetzt (CM_HVK_EKK_Sollmodus_Cx2_Freigabe_ausgesetzt), 7=Cx7_Init (CM_HVK_EKK_Sollmodus_Cx7_Init)}, range raw 0..7, transfer-property=TRIGGERED-ON-CHANGE-WITHOUT-REPETITION  # Sollmodus elektrischer Klimakompressor
          signal HVK_HVPTC_Sollmodus_XIX_HVK_01_XIX_E3V_EVCANFD: start 33, 3 bit, little-endian, data-type-policy=OVERRIDE, i-signal-type=PRIMITIVE, init-value=7, base-type=BT_HVK_HVPTC_Sollmodus, compu {0=Cx0_Keine_Freigabe (CM_HVK_HVPTC_Sollmodus_Cx0_Keine_Freigabe), 1=Cx1_Freigabe (CM_HVK_HVPTC_Sollmodus_Cx1_Freigabe), 2=Cx2_Freigabe_ausgesetzt (CM_HVK_HVPTC_Sollmodus_Cx2_Freigabe_ausgesetzt), 7=Cx7_Init (CM_HVK_HVPTC_Sollmodus_Cx7_Init)}, range raw 0..7, transfer-property=TRIGGERED-ON-CHANGE-WITHOUT-REPETITION  # Sollmodus HV-PTC 0 : keine Freigabe 1 : Freigabe 2 : Freigabe_ausgesetzt 3 : nicht belegbar 4 : nicht belegbar 5 : nicht belegbar 6 : nicht belegbar 7 : Init (CAN-Initialisierung) Info: "nicht belegbar" d.h. Sollmodus nicht relevant für HVK
          signal HVK_HVLM_Sollmodus_XIX_HVK_01_XIX_E3V_EVCANFD: start 36, 3 bit, little-endian, data-type-policy=OVERRIDE, i-signal-type=PRIMITIVE, init-value=7, base-type=BT_HVK_HVLM_Sollmodus, compu {0=Cx0_keine_Freigabe (CM_HVK_HVLM_Sollmodus_Cx0_keine_Freigabe), 1=Cx1_Freigabe_Lademanager (CM_HVK_HVLM_Sollmodus_Cx1_Freigabe_Lademanager), 2=Cx2_Vorladung_AC_Pfad (CM_HVK_HVLM_Sollmodus_Cx2_Vorladung_AC_Pfad), 7=Cx7_Init (CM_HVK_HVLM_Sollmodus_Cx7_Init)}, range raw 0..7, transfer-property=TRIGGERED-ON-CHANGE-WITHOUT-REPETITION  # Angeforderter Sollmodus des Lademanagers.
          signal HVK_HV_Netz_Warnungen_XIX_HVK_01_XIX_E3V_EVCANFD: start 39, 2 bit, little-endian, data-type-policy=OVERRIDE, i-signal-type=PRIMITIVE, init-value=0, base-type=BT_HVK_HV_Netz_Warnungen, compu {0=Cx0_Keine_Warnung (CM_HVK_HV_Netz_Warnungen_Cx0_Keine_Warnung), 1=Cx1_Warntext_HV_Netz_Anf (CM_HVK_HV_Netz_Warnungen_Cx1_Warntext_HV_Netz_Anf), 2=Cx2_Fehlertext_HV_Netz_Anf (CM_HVK_HV_Netz_Warnungen_Cx2_Fehlertext_HV_Netz_Anf), 3=Cx3_Warnung_Kein_Wiederstart_moeglich (CM_HVK_HV_Netz_Warnungen_Cx3_Warnung_Kein_Wiederstart_moeglich)}, range raw 0..3, transfer-property=TRIGGERED-ON-CHANGE-WITHOUT-REPETITION, to Klima(timeout 1 s)  # Anforderung Warnung/Fehler HV-System im Kombi 0: Keine Warnung/Init 1:Anforderung_Anzeige_Warnung_HV-Netz (gelbes Symbol) 2:Anforderung_Anzeige_Fehler_HV-Netz (rotes Symbol) 3:Anforderung_Anzeige_Warnung_Kein_Wiederstart_möglich
          signal HV_Bordnetz_aktiv_XIX_HVK_01_XIX_E3V_EVCANFD: start 41, 1 bit, little-endian, data-type-policy=OVERRIDE, i-signal-type=PRIMITIVE, init-value=0, base-type=BT_HV_Bordnetz_aktiv, compu {0=Cx0_inaktiv (CM_HV_Bordnetz_aktiv_Cx0_inaktiv), 1=Cx1_aktiv (CM_HV_Bordnetz_aktiv_Cx1_aktiv)}, range raw 0..1, transfer-property=TRIGGERED-ON-CHANGE-WITHOUT-REPETITION, to Klima(timeout 1 s)  # Signalisiert ein aktives Hochvoltbordnetz. Für die Belastbarkeit des HV-Netzes müssen Strom- bzw. Leistungsgrenzen eingehalten werden
          signal HV_Bordnetz_Fehler_XIX_HVK_01_XIX_E3V_EVCANFD: start 42, 1 bit, little-endian, data-type-policy=OVERRIDE, i-signal-type=PRIMITIVE, init-value=0, base-type=BT_HV_Bordnetz_Fehler, invalid-value=Invalid_HV_Bordnetz_Fehler_XIX_HVK_01_XIX_E3V_EVCANFD:1, compu {0=Cx0_kein_Fehler (CM_HV_Bordnetz_Fehler_Cx0_kein_Fehler), 1=Cx1_Fehler (CM_HV_Bordnetz_Fehler_Cx1_Fehler)}, range raw 0..1, transfer-property=TRIGGERED-ON-CHANGE-WITHOUT-REPETITION, to Klima(timeout 1 s)  # Status ob im HV-Netz ein Fehler detektiert wurde.
          signal HVK_Gesamtst_Spgfreiheit_XIX_HVK_01_XIX_E3V_EVCANFD: start 43, 2 bit, little-endian, data-type-policy=OVERRIDE, i-signal-type=PRIMITIVE, init-value=0, base-type=BT_HVK_Gesamtst_Spgfreiheit, invalid-value=Invalid_HVK_Gesamtst_Spgfreiheit_XIX_HVK_01_XIX_E3V_EVCANFD:3, compu {0=Cx0_Funktion_Init_ohne_Funktion (CM_HVK_Gesamtst_Spgfreiheit_Cx0_Funktion_Init_ohne_Funktion) (Funktion_Init__ohne_Funktion), 1=Cx1_HV_System_spannungsfrei (CM_HVK_Gesamtst_Spgfreiheit_Cx1_HV_System_spannungsfrei), 2=Cx2_HV_System_nicht_spannungsfrei (CM_HVK_Gesamtst_Spgfreiheit_Cx2_HV_System_nicht_spannungsfrei), 3=Cx3_Fehler (CM_HVK_Gesamtst_Spgfreiheit_Cx3_Fehler)}, range raw 0..3, transfer-property=PENDING  # Status des HV-Systems
          signal HVK_AktiveEntladung_Anf_XIX_HVK_01_XIX_E3V_EVCANFD: start 45, 1 bit, little-endian, data-type-policy=OVERRIDE, i-signal-type=PRIMITIVE, init-value=0, base-type=BT_HVK_AktiveEntladung_Anf, compu {0=Cx0_nicht_angefordert (CM_HVK_AktiveEntladung_Anf_Cx0_nicht_angefordert), 1=Cx1_angefordert (CM_HVK_AktiveEntladung_Anf_Cx1_angefordert)}, range raw 0..1, transfer-property=TRIGGERED-ON-CHANGE-WITHOUT-REPETITION, to Klima(timeout 1 s)  # Anforderung zum aktiven Entladen des HV-Netzes, während der Abschaltung des HV-Netz.
          signal HVK_HVEM_Freigabe_XIX_HVK_01_XIX_E3V_EVCANFD: start 46, 2 bit, little-endian, data-type-policy=OVERRIDE, i-signal-type=PRIMITIVE, init-value=2, base-type=BT_HVK_HVEM_Freigabe, compu {0=Cx0_keine_Freigabe (CM_HVK_HVEM_Freigabe_Cx0_keine_Freigabe), 1=Cx1_Freigabe (CM_HVK_HVEM_Freigabe_Cx1_Freigabe), 2=Cx2_Init (CM_HVK_HVEM_Freigabe_Cx2_Init)}, range raw 0..2, transfer-property=TRIGGERED-ON-CHANGE-WITHOUT-REPETITION  # Der HVK gibt das HVEM frei, um das HV-Netz unter Einhaltung von Leistungsgrenzen in Anspruch zu nehmen.
          signal HVK_Notabschaltung_Anf_XIX_HVK_01_XIX_E3V_EVCANFD: start 48, 2 bit, little-endian, data-type-policy=OVERRIDE, i-signal-type=PRIMITIVE, init-value=0, base-type=BT_HVK_Notabschaltung_Anf, compu {0=Cx0_keine_Anforderung_Notabschaltung (CM_HVK_Notabschaltung_Anf_Cx0_keine_Anforderung_Notabschaltung), 1=Cx1_Anforderung_Notabschaltung (CM_HVK_Notabschaltung_Anf_Cx1_Anforderung_Notabschaltung), 2=Cx2_Reserve (CM_HVK_Notabschaltung_Anf_Cx2_Reserve), 3=Cx3_Init (CM_HVK_Notabschaltung_Anf_Cx3_Init)}, range raw 0..3, transfer-property=TRIGGERED-ON-CHANGE-WITHOUT-REPETITION, to Klima(timeout 1 s)  # Aufforderung zur schnellstmöglichen Abschaltung des HV-Netzes aufgrund HV-Sicherheit
          signal HVK_Iso_Messung_Start_XIX_HVK_01_XIX_E3V_EVCANFD: start 50, 3 bit, little-endian, data-type-policy=OVERRIDE, i-signal-type=PRIMITIVE, init-value=0, base-type=BT_HVK_Iso_Messung_Start, compu {0=Cx0_keine_Messung (CM_HVK_Iso_Messung_Start_Cx0_keine_Messung), 1=Cx1_Messung_HV_Netz_1 (CM_HVK_Iso_Messung_Start_Cx1_Messung_HV_Netz_1), 2=Cx2_Messung_HV_Netz_2 (CM_HVK_Iso_Messung_Start_Cx2_Messung_HV_Netz_2), 4=Cx4_deaktiviert (CM_HVK_Iso_Messung_Start_Cx4_deaktiviert)}, range raw 0..4, transfer-property=PENDING, to Klima(timeout 1 s)  # Anforderung an die isolationswiderstandsüberwachenden HV-Komponenten zur Durchführung der Isolations-Widerstandsmessung.
          signal HVK_Ladebereit_XIX_HVK_01_XIX_E3V_EVCANFD: start 53, 3 bit, little-endian, data-type-policy=OVERRIDE, i-signal-type=PRIMITIVE, init-value=0, base-type=BT_HVK_Ladebereit, compu {0=Cx0_Init_oder_nicht_Ladebereit (CM_HVK_Ladebereit_Cx0_Init_oder_nicht_Ladebereit), 1=Cx1_AC_Ladebereit (CM_HVK_Ladebereit_Cx1_AC_Ladebereit), 2=Cx2_DC_Ladebereit (CM_HVK_Ladebereit_Cx2_DC_Ladebereit), 3=Cx3_AC_und_DC_Ladebereit (CM_HVK_Ladebereit_Cx3_AC_und_DC_Ladebereit), 4=Cx4_Induktiv_Ladebereit (CM_HVK_Ladebereit_Cx4_Induktiv_Ladebereit), 5=Cx5_AC_und_Induktiv_Ladebereit (CM_HVK_Ladebereit_Cx5_AC_und_Induktiv_Ladebereit), 6=Cx6_DC_und_Induktiv_Ladebereit (CM_HVK_Ladebereit_Cx6_DC_und_Induktiv_Ladebereit), 7=Cx7_AC_DC_und_Induktiv_Ladebereit (CM_HVK_Ladebereit_Cx7_AC_DC_und_Induktiv_Ladebereit)}, range raw 0..7, transfer-property=TRIGGERED-ON-CHANGE-WITHOUT-REPETITION  # Information an das Lademanagement, dass das HV-System aus Sicht des HVKs bereitgestellt werden kann.
          signal HVK_PPulsFreigabe_XIX_HVK_01_XIX_E3V_EVCANFD: start 56, 2 bit, little-endian, data-type-policy=OVERRIDE, i-signal-type=PRIMITIVE, init-value=3, base-type=BT_HVK_PPulsFreigabe, compu {0=Cx0_keine_Freigabe (CM_HVK_PPulsFreigabe_Cx0_keine_Freigabe), 1=Cx1_Freigabe (CM_HVK_PPulsFreigabe_Cx1_Freigabe), 2=Cx2_Reserve (CM_HVK_PPulsFreigabe_Cx2_Reserve), 3=Cx3_Init (CM_HVK_PPulsFreigabe_Cx3_Init)}, range raw 0..3, transfer-property=PENDING  # Prüfpuls-Freigabe seitens Hochvoltkoordinator
      frame HVLM_17_XIX_E3V_EVCANFD: id 0x12DD555C, to Klima, frame-length=24, can-addressing-mode=EXTENDED, can-frame-rx-behavior=CAN-FD, can-frame-tx-behavior=CAN-FD
        pdu HVLM_17_XIX_E3V_EVCANFD: length=24, minimum-delay=0.01, transmission-mode-true-timing={cyclic-timing={time-offset=0.0, time-period=0.2}, event-controlled-timing={number-of-repetitions=0, repetition-period=0.0}}, unused-bit-pattern=0
          signal HVLM_17_CRC_XIX_HVLM_17_XIX_E3V_EVCANFD: start 0, 8 bit, little-endian, data-type-policy=OVERRIDE, i-signal-type=PRIMITIVE, init-value=0, base-type=BT_HVLM_17_CRC, compu {phys=raw for raw 0..255}, range phys 0..255, raw 0..255, transfer-property=PENDING
          signal HVLM_17_BZ_XIX_HVLM_17_XIX_E3V_EVCANFD: start 8, 4 bit, little-endian, data-type-policy=OVERRIDE, i-signal-type=PRIMITIVE, init-value=0, base-type=BT_HVLM_17_BZ, compu {phys=raw for raw 0..15}, range phys 0..15, raw 0..15, transfer-property=PENDING
          signal HVLM_OeffnenSchliessenAnf_Lk1_XIX_HVLM_17_XIX_E3V_EVCANFD: start 12, 3 bit, little-endian, data-type-policy=OVERRIDE, i-signal-type=PRIMITIVE, init-value=0, base-type=BT_HVLM_OeffnenSchliessenAnf_Lk1, compu {0=Cx0_keine_Freigabe_Ladeklappe (CM_HVLM_OeffnenSchliessenAnf_Lk1_Cx0_keine_Freigabe_Ladeklappe), 1=Cx1_Freigabe_Ladeklappe_zu_verfahren (CM_HVLM_OeffnenSchliessenAnf_Lk1_Cx1_Freigabe_Ladeklappe_zu_verfahren), 2=Cx2_Anforderung_Ladeklappe_oeffnen (CM_HVLM_OeffnenSchliessenAnf_Lk1_Cx2_Anforderung_Ladeklappe_oeffnen), 3=Cx3_Anforderung_Ladeklappe_schliessen (CM_HVLM_OeffnenSchliessenAnf_Lk1_Cx3_Anforderung_Ladeklappe_schliessen), 4=Cx4_Initialisieren_Ladeklappe (CM_HVLM_OeffnenSchliessenAnf_Lk1_Cx4_Initialisieren_Ladeklappe)}, range raw 0..4, transfer-property=PENDING  # Ansteuerung und Freigabe zum Verfahren der elektrischen Ladeklappe
          signal HVLM_OeffnenSchliessenAnf_Lk2_XIX_HVLM_17_XIX_E3V_EVCANFD: start 15, 3 bit, little-endian, data-type-policy=OVERRIDE, i-signal-type=PRIMITIVE, init-value=0, base-type=BT_HVLM_OeffnenSchliessenAnf_Lk2, compu {0=Cx0_keine_Freigabe_Ladeklappe (CM_HVLM_OeffnenSchliessenAnf_Lk2_Cx0_keine_Freigabe_Ladeklappe), 1=Cx1_Freigabe_Ladeklappe_zu_verfahren (CM_HVLM_OeffnenSchliessenAnf_Lk2_Cx1_Freigabe_Ladeklappe_zu_verfahren), 2=Cx2_Anforderung_Ladeklappe_oeffnen (CM_HVLM_OeffnenSchliessenAnf_Lk2_Cx2_Anforderung_Ladeklappe_oeffnen), 3=Cx3_Anforderung_Ladeklappe_schliessen (CM_HVLM_OeffnenSchliessenAnf_Lk2_Cx3_Anforderung_Ladeklappe_schliessen), 4=Cx4_Initialisieren_Ladeklappe (CM_HVLM_OeffnenSchliessenAnf_Lk2_Cx4_Initialisieren_Ladeklappe)}, range raw 0..4, transfer-property=PENDING  # Ansteuerung und Freigabe zum Verfahren der elektrischen Ladeklappe
          signal HVLM_OeffnenSchliessenAnf_Lk3_XIX_HVLM_17_XIX_E3V_EVCANFD: start 18, 3 bit, little-endian, data-type-policy=OVERRIDE, i-signal-type=PRIMITIVE, init-value=0, base-type=BT_HVLM_OeffnenSchliessenAnf_Lk3, compu {0=Cx0_keine_Freigabe_Ladeklappe (CM_HVLM_OeffnenSchliessenAnf_Lk3_Cx0_keine_Freigabe_Ladeklappe), 1=Cx1_Freigabe_Ladeklappe_zu_verfahren (CM_HVLM_OeffnenSchliessenAnf_Lk3_Cx1_Freigabe_Ladeklappe_zu_verfahren), 2=Cx2_Anforderung_Ladeklappe_oeffnen (CM_HVLM_OeffnenSchliessenAnf_Lk3_Cx2_Anforderung_Ladeklappe_oeffnen), 3=Cx3_Anforderung_Ladeklappe_schliessen (CM_HVLM_OeffnenSchliessenAnf_Lk3_Cx3_Anforderung_Ladeklappe_schliessen), 4=Cx4_Initialisieren_Ladeklappe (CM_HVLM_OeffnenSchliessenAnf_Lk3_Cx4_Initialisieren_Ladeklappe)}, range raw 0..4, transfer-property=PENDING  # Ansteuerung und Freigabe zum Verfahren der elektrischen Ladeklappe
          signal HVLM_Ladeenergie_XIX_HVLM_17_XIX_E3V_EVCANFD: start 34, 14 bit, little-endian, data-type-policy=OVERRIDE, i-signal-type=PRIMITIVE, init-value=0, base-type=BT_HVLM_Ladeenergie, compu {phys=raw*0.1 for raw 0..10000; unit Unit_KiloWattHour}, range phys 0..1000 Unit_KiloWattHour, raw 0..10000, unit=Unit_KiloWattHour, transfer-property=PENDING  # Ladeenergie des Fahrzeugs
          signal HVLM_MaxLadeleistungDcFzg_XIX_HVLM_17_XIX_E3V_EVCANFD: start 48, 11 bit, little-endian, data-type-policy=OVERRIDE, i-signal-type=PRIMITIVE, init-value=2046, base-type=BT_HVLM_MaxLadeleistungDcFzg, invalid-value=Invalid_HVLM_MaxLadeleistungDcFzg_XIX_HVLM_17_XIX_E3V_EVCANFD:2047, compu {phys=raw for raw 0..1500, 2044=Cx7fc_temporaere_Nichtverfuegbarkeit (CM_HVLM_MaxLadeleistungDcFzg_Cx7fc_temporaere_Nichtverfuegbarkeit), 2045=Cx7fd_irreversibler_Fehler (CM_HVLM_MaxLadeleistungDcFzg_Cx7fd_irreversibler_Fehler), 2046=Cx7fe_Init (CM_HVLM_MaxLadeleistungDcFzg_Cx7fe_Init), 2047=Cx7ff_Fehler (CM_HVLM_MaxLadeleistungDcFzg_Cx7ff_Fehler); unit Unit_KiloWatt}, range phys 0..1500 Unit_KiloWatt, raw 0..2047, unit=Unit_KiloWatt, transfer-property=PENDING  # Maximale Ladeleistung die das Fahrzeug aus einer DC-Ladeinfrastruktur entnehmen kann
          signal HVLM_VasAnzeige_ZielSoc_XIX_HVLM_17_XIX_E3V_EVCANFD: start 59, 7 bit, little-endian, data-type-policy=OVERRIDE, i-signal-type=PRIMITIVE, init-value=127, base-type=BT_HVLM_VasAnzeige_ZielSoc, compu {phys=raw for raw 0..100, 126=Cx7e_keine_Anzeige (CM_HVLM_VasAnzeige_ZielSoc_Cx7e_keine_Anzeige), 127=Cx7f_Init (CM_HVLM_VasAnzeige_ZielSoc_Cx7f_Init); unit Unit_PerCent}, range phys 0..100 Unit_PerCent, raw 0..127, unit=Unit_PerCent, transfer-property=PENDING  # Anzeigewert des aktueller Zielladezustand an einer Wallbox, die ValueAddedServices nach VW-Spezifikation unterstützt
          signal HVLM_DCBoostLaden_Anf_XIX_HVLM_17_XIX_E3V_EVCANFD: start 66, 3 bit, little-endian, data-type-policy=OVERRIDE, i-signal-type=PRIMITIVE, init-value=0, base-type=BT_HVLM_DCBoostLaden_Anf, invalid-value=Invalid_HVLM_DCBoostLaden_Anf_XIX_HVLM_17_XIX_E3V_EVCANFD:7, compu {0=Cx0_Init (CM_HVLM_DCBoostLaden_Anf_Cx0_Init), 1=Cx1_DC_BL_nicht_angefordert (CM_HVLM_DCBoostLaden_Anf_Cx1_DC_BL_nicht_angefordert), 2=Cx2_DC_BL_angefordert (CM_HVLM_DCBoostLaden_Anf_Cx2_DC_BL_angefordert), 3=Cx3_Reserve (CM_HVLM_DCBoostLaden_Anf_Cx3_Reserve), 4=Cx4_Reserve (CM_HVLM_DCBoostLaden_Anf_Cx4_Reserve), 5=Cx5_Reserve (CM_HVLM_DCBoostLaden_Anf_Cx5_Reserve), 6=Cx6_Reserve (CM_HVLM_DCBoostLaden_Anf_Cx6_Reserve), 7=Cx7_Fehler (CM_HVLM_DCBoostLaden_Anf_Cx7_Fehler)}, range raw 0..7, transfer-property=PENDING, to Klima(timeout 2 s)  # Das Signal fordert ein "DC-Boostladen" bei der HV-Batterie an
          signal HVLM_TLS_Version_XIX_HVLM_17_XIX_E3V_EVCANFD: start 69, 3 bit, little-endian, data-type-policy=OVERRIDE, i-signal-type=PRIMITIVE, init-value=0, base-type=BT_HVLM_TLS_Version, invalid-value=Invalid_HVLM_TLS_Version_XIX_HVLM_17_XIX_E3V_EVCANFD:7, compu {0=Cx0_Init (CM_HVLM_TLS_Version_Cx0_Init), 1=Cx1_TLS_nicht_verwenden (CM_HVLM_TLS_Version_Cx1_TLS_nicht_verwenden), 2=Cx2_TLS_1_2_verwenden (CM_HVLM_TLS_Version_Cx2_TLS_1_2_verwenden), 3=Cx3_TLS_1_3_verwenden (CM_HVLM_TLS_Version_Cx3_TLS_1_3_verwenden), 7=Cx7_Fehler (CM_HVLM_TLS_Version_Cx7_Fehler)}, range raw 0..7, transfer-property=PENDING  # Anfrage über das Ladegerät an die Ladesäule, mit welcher TLS-Version das Fahrzeug die TLS-Verbindung starten möchte.
          signal HVLM_ServiceIDFzgPlc_XIX_HVLM_17_XIX_E3V_EVCANFD: start 72, 4 bit, little-endian, data-type-policy=OVERRIDE, i-signal-type=PRIMITIVE, init-value=0, base-type=BT_HVLM_ServiceIDFzgPlc, invalid-value=Invalid_HVLM_ServiceIDFzgPlc_XIX_HVLM_17_XIX_E3V_EVCANFD:15, compu {0=Cx0_Init (CM_HVLM_ServiceIDFzgPlc_Cx0_Init), 1=Cx1_AC (CM_HVLM_ServiceIDFzgPlc_Cx1_AC), 2=Cx2_DC (CM_HVLM_ServiceIDFzgPlc_Cx2_DC), 3=Cx3_WPT (CM_HVLM_ServiceIDFzgPlc_Cx3_WPT), 4=Cx4_DC_ACDP (CM_HVLM_ServiceIDFzgPlc_Cx4_DC_ACDP), 5=Cx5_AC_BPT (CM_HVLM_ServiceIDFzgPlc_Cx5_AC_BPT), 6=Cx6_DC_BPT (CM_HVLM_ServiceIDFzgPlc_Cx6_DC_BPT), 7=Cx7_DC_ACDP_BPT (CM_HVLM_ServiceIDFzgPlc_Cx7_DC_ACDP_BPT), 13=Cxd_Internet (CM_HVLM_ServiceIDFzgPlc_Cxd_Internet), 14=Cxe_ParkingStatus (CM_HVLM_ServiceIDFzgPlc_Cxe_ParkingStatus), 15=Cxf_Fehler (CM_HVLM_ServiceIDFzgPlc_Cxf_Fehler)}, range raw 0..15, transfer-property=PENDING  # Unterstützte ServiceIDs
          signal HVLM_IstSpannungFzgPlc_XIX_HVLM_17_XIX_E3V_EVCANFD: start 76, 14 bit, little-endian, data-type-policy=OVERRIDE, i-signal-type=PRIMITIVE, init-value=16382, base-type=BT_HVLM_IstSpannungFzgPlc, invalid-value=Invalid_HVLM_IstSpannungFzgPlc_XIX_HVLM_17_XIX_E3V_EVCANFD:16383, compu {phys=raw*0.0625 for raw 0..16380, 16381=Cx3ffd_Null_Bank (CM_HVLM_IstSpannungFzgPlc_Cx3ffd_Null_Bank), 16382=Cx3ffe_Init (CM_HVLM_IstSpannungFzgPlc_Cx3ffe_Init), 16383=Cx3fff_Fehler (CM_HVLM_IstSpannungFzgPlc_Cx3fff_Fehler); unit Unit_Volt}, range phys 0..1023.75 Unit_Volt, raw 0..16383, unit=Unit_Volt, transfer-property=PENDING  # Istspannung des Fahrzeugs bzw. der HV-Batterie im Fahrzeug.
          signal HVLM_MeterInfoRequestFzgPlc_XIX_HVLM_17_XIX_E3V_EVCANFD: start 90, 1 bit, little-endian, data-type-policy=OVERRIDE, i-signal-type=PRIMITIVE, init-value=0, base-type=BT_HVLM_MeterInfoRequestFzgPlc, compu {0=Cx0_False_keine_Anfrage (CM_HVLM_MeterInfoRequestFzgPlc_Cx0_False_keine_Anfrage), 1=Cx1_True_Anfrage (CM_HVLM_MeterInfoRequestFzgPlc_Cx1_True_Anfrage)}, range raw 0..1, transfer-property=PENDING  # This Parameter indicates, if set to "TRUE" that the EV wants to receive the MeterInfo by the EVSE.
          signal HVLM_Wirkleistung_XIX_HVLM_17_XIX_E3V_EVCANFD: start 91, 8 bit, little-endian, data-type-policy=OVERRIDE, i-signal-type=PRIMITIVE, init-value=254, base-type=BT_HVLM_Wirkleistung, invalid-value=Invalid_HVLM_Wirkleistung_XIX_HVLM_17_XIX_E3V_EVCANFD:255, compu {phys=raw*100 for raw 0..253, 254=Cxfe_Init (CM_HVLM_Wirkleistung_Cxfe_Init), 255=Cxff_Fehler (CM_HVLM_Wirkleistung_Cxff_Fehler); unit Unit_Watt}, range phys 0..25300 Unit_Watt, raw 0..255, unit=Unit_Watt, transfer-property=PENDING  # Present active power achieved by the EV.
          signal HVLM_Wirkleistung_2_XIX_HVLM_17_XIX_E3V_EVCANFD: start 99, 8 bit, little-endian, data-type-policy=OVERRIDE, i-signal-type=PRIMITIVE, init-value=254, base-type=BT_HVLM_Wirkleistung_2, invalid-value=Invalid_HVLM_Wirkleistung_2_XIX_HVLM_17_XIX_E3V_EVCANFD:255, compu {phys=raw*100 for raw 0..253, 254=Cxfe_Init (CM_HVLM_Wirkleistung_2_Cxfe_Init), 255=Cxff_Fehler (CM_HVLM_Wirkleistung_2_Cxff_Fehler); unit Unit_Watt}, range phys 0..25300 Unit_Watt, raw 0..255, unit=Unit_Watt, transfer-property=PENDING  # Present active power achieved by the EV.
          signal HVLM_Wirkleistung_3_XIX_HVLM_17_XIX_E3V_EVCANFD: start 107, 8 bit, little-endian, data-type-policy=OVERRIDE, i-signal-type=PRIMITIVE, init-value=254, base-type=BT_HVLM_Wirkleistung_3, invalid-value=Invalid_HVLM_Wirkleistung_3_XIX_HVLM_17_XIX_E3V_EVCANFD:255, compu {phys=raw*100 for raw 0..253, 254=Cxfe_Init (CM_HVLM_Wirkleistung_3_Cxfe_Init), 255=Cxff_Fehler (CM_HVLM_Wirkleistung_3_Cxff_Fehler); unit Unit_Watt}, range phys 0..25300 Unit_Watt, raw 0..255, unit=Unit_Watt, transfer-property=PENDING  # Present active power achieved by the EV.
          signal HVLM_Blindleistung_XIX_HVLM_17_XIX_E3V_EVCANFD: start 115, 8 bit, little-endian, data-type-policy=OVERRIDE, i-signal-type=PRIMITIVE, init-value=254, base-type=BT_HVLM_Blindleistung, invalid-value=Invalid_HVLM_Blindleistung_XIX_HVLM_17_XIX_E3V_EVCANFD:255, compu {phys=raw*100 for raw 0..253, 254=Cxfe_Init (CM_HVLM_Blindleistung_Cxfe_Init), 255=Cxff_Fehler (CM_HVLM_Blindleistung_Cxff_Fehler); unit Unit_Watt}, range phys 0..25300 Unit_Watt, raw 0..255, unit=Unit_Watt, transfer-property=PENDING  # Present reactive power achieved by the EV.
          signal HVLM_Blindleistung_2_XIX_HVLM_17_XIX_E3V_EVCANFD: start 123, 8 bit, little-endian, data-type-policy=OVERRIDE, i-signal-type=PRIMITIVE, init-value=254, base-type=BT_HVLM_Blindleistung_2, invalid-value=Invalid_HVLM_Blindleistung_2_XIX_HVLM_17_XIX_E3V_EVCANFD:255, compu {phys=raw*100 for raw 0..253, 254=Cxfe_Init (CM_HVLM_Blindleistung_2_Cxfe_Init), 255=Cxff_Fehler (CM_HVLM_Blindleistung_2_Cxff_Fehler); unit Unit_Watt}, range phys 0..25300 Unit_Watt, raw 0..255, unit=Unit_Watt, transfer-property=PENDING  # Present reactive power achieved by the EV.
          signal HVLM_Blindleistung_3_XIX_HVLM_17_XIX_E3V_EVCANFD: start 131, 8 bit, little-endian, data-type-policy=OVERRIDE, i-signal-type=PRIMITIVE, init-value=254, base-type=BT_HVLM_Blindleistung_3, invalid-value=Invalid_HVLM_Blindleistung_3_XIX_HVLM_17_XIX_E3V_EVCANFD:255, compu {phys=raw*100 for raw 0..253, 254=Cxfe_Init (CM_HVLM_Blindleistung_3_Cxfe_Init), 255=Cxff_Fehler (CM_HVLM_Blindleistung_3_Cxff_Fehler); unit Unit_Watt}, range phys 0..25300 Unit_Watt, raw 0..255, unit=Unit_Watt, transfer-property=PENDING  # Present reactive power achieved by the EV.
          signal HVLM_V2X_SollModus_XIX_HVLM_17_XIX_E3V_EVCANFD: start 147, 4 bit, little-endian, data-type-policy=OVERRIDE, i-signal-type=PRIMITIVE, init-value=0, base-type=BT_HVLM_V2X_SollModus, invalid-value=Invalid_HVLM_V2X_SollModus_XIX_HVLM_17_XIX_E3V_EVCANFD:15, compu {0=Cx0_Init (CM_HVLM_V2X_SollModus_Cx0_Init), 1=Cx1_Aus (CM_HVLM_V2X_SollModus_Cx1_Aus), 2=Cx2_STD_ein (CM_HVLM_V2X_SollModus_Cx2_STD_ein), 3=Cx3_Adapter_ein (CM_HVLM_V2X_SollModus_Cx3_Adapter_ein), 4=Cx4_STD_und_Adapter_ein (CM_HVLM_V2X_SollModus_Cx4_STD_und_Adapter_ein), 15=Cxf_Fehler (CM_HVLM_V2X_SollModus_Cxf_Fehler)}, range raw 0..15, transfer-property=PENDING  # Auswahl des V2L-Modus
          signal HVLM_V2L_EV_CAN_Wakeup_zulassen_XIX_HVLM_17_XIX_E3V_EVCANFD: start 151, 2 bit, little-endian, data-type-policy=OVERRIDE, i-signal-type=PRIMITIVE, init-value=0, base-type=BT_HVLM_V2L_EV_CAN_Wakeup_zulassen, invalid-value=Invalid_HVLM_V2L_EV_CAN_Wakeup_zulassen_XIX_HVLM_17_XIX_E3V_EVCANFD:3, compu {0=Cx0_InitWert (CM_HVLM_V2L_EV_CAN_Wakeup_zulassen_Cx0_InitWert), 1=Cx1_Nein (CM_HVLM_V2L_EV_CAN_Wakeup_zulassen_Cx1_Nein), 2=Cx2_Ja (CM_HVLM_V2L_EV_CAN_Wakeup_zulassen_Cx2_Ja), 3=Cx3_Fehler (CM_HVLM_V2L_EV_CAN_Wakeup_zulassen_Cx3_Fehler)}, range raw 0..3, transfer-property=PENDING  # Weckerlaubnis bei Verbraucher erkannt an Steckdose
          signal HVLM_SOC_Kalib_Conf_XIX_HVLM_17_XIX_E3V_EVCANFD: start 153, 6 bit, little-endian, data-type-policy=OVERRIDE, i-signal-type=PRIMITIVE, init-value=0, base-type=BT_HVLM_SOC_Kalib_Conf, compu {0=Cx0_keine_Kalibrierung_Init (CM_HVLM_SOC_Kalib_Conf_Cx0_keine_Kalibrierung_Init), 1=Cx1_Kalib_Vollladen_mit_Relax_bestae (CM_HVLM_SOC_Kalib_Conf_Cx1_Kalib_Vollladen_mit_Relax_bestae), 2=Cx2_Kalib_Vollladen_ohne_Relax_besta (CM_HVLM_SOC_Kalib_Conf_Cx2_Kalib_Vollladen_ohne_Relax_besta), 4=Cx4_Kalib_AC60_bestaetigt (CM_HVLM_SOC_Kalib_Conf_Cx4_Kalib_AC60_bestaetigt), 8=Cx8_Kalib_AC95_bestaetigt (CM_HVLM_SOC_Kalib_Conf_Cx8_Kalib_AC95_bestaetigt), 16=Cx10_Kalib_Entladen_mit_Relax_bestaet (CM_HVLM_SOC_Kalib_Conf_Cx10_Kalib_Entladen_mit_Relax_bestaet), 32=Cx20_Reserve (CM_HVLM_SOC_Kalib_Conf_Cx20_Reserve)}, range raw 0..32, transfer-property=PENDING  # Bestätigung der SOC-Kalibrierungsaufforderung vom HV-Laden an die Batterie.
          signal HVLM_TriggerScheduleRenegFzgPlc_XIX_HVLM_17_XIX_E3V_EVCANFD: start 159, 2 bit, little-endian, data-type-policy=OVERRIDE, i-signal-type=PRIMITIVE, base-type=BT_HVLM_TriggerScheduleRenegFzgPlc, invalid-value=Invalid_HVLM_TriggerScheduleRenegFzgPlc_XIX_HVLM_17_XIX_E3V_EVCANFD:3, compu {0=Cx0_Init (CM_HVLM_TriggerScheduleRenegFzgPlc_Cx0_Init), 1=Cx1_Neuverhandlung (CM_HVLM_TriggerScheduleRenegFzgPlc_Cx1_Neuverhandlung), 3=Cx3_Fehler (CM_HVLM_TriggerScheduleRenegFzgPlc_Cx3_Fehler)}, range raw 0..3, transfer-property=PENDING  # Triggersignal um die Kommunikationssteuerung für die ScheduleRenegotiation auf dem Ladegerät zu Starten und zu Beenden.
          signal HVLM_RQCP_Anf_XIX_HVLM_17_XIX_E3V_EVCANFD: start 164, 1 bit, little-endian, data-type-policy=OVERRIDE, i-signal-type=PRIMITIVE, init-value=0, base-type=BT_HVLM_RQCP_Anf, compu {0=Cx0_Keine_Anforderung (CM_HVLM_RQCP_Anf_Cx0_Keine_Anforderung), 1=Cx1_RQCP_anfordern (CM_HVLM_RQCP_Anf_Cx1_RQCP_anfordern)}, range raw 0..1, transfer-property=TRIGGERED-ON-CHANGE-WITHOUT-REPETITION  # Anforderung das reduzierte QuickCharge Protokoll zu aktivieren.
      frame ISO_Funktionaler_Req_All_XIX_E3V_EVCANFD: id 0x700, to Klima, frame-length=8, can-addressing-mode=STANDARD, can-frame-rx-behavior=CAN-FD, can-frame-tx-behavior=CAN-FD
        n pdu ISO_Funktionaler_Req_All_XIX_E3V_EVCANFD: length=8
      frame ISO_Klima_Req_XIX_E3V_EVCANFD: id 0x746, to Klima, frame-length=8, can-addressing-mode=STANDARD, can-frame-rx-behavior=CAN-FD, can-frame-tx-behavior=CAN-FD
        n pdu ISO_Klima_Req_XIX_E3V_EVCANFD: length=8
      frame ISO_Klima_Resp_XIX_E3V_EVCANFD: id 0x7B0, from Klima, frame-length=8, can-addressing-mode=STANDARD, can-frame-rx-behavior=CAN-FD, can-frame-tx-behavior=CAN-FD
        n pdu ISO_Klima_Resp_XIX_E3V_EVCANFD: length=8
      frame ISOx_Funkt_Req_All_FD_XIX_E3V_EVCANFD: id 0x1C410000, to Klima, frame-length=64, can-addressing-mode=EXTENDED, can-frame-rx-behavior=CAN-FD, can-frame-tx-behavior=CAN-FD
        n pdu ISOx_Funkt_Req_All_FD_XIX_E3V_EVCANFD: length=64
      frame ISOx_Klima_Req_FD_XIX_E3V_EVCANFD: id 0x1C400046, to Klima, frame-length=64, can-addressing-mode=EXTENDED, can-frame-rx-behavior=CAN-FD, can-frame-tx-behavior=CAN-FD
        n pdu ISOx_Klima_Req_FD_XIX_E3V_EVCANFD: length=64
      frame ISOx_Klima_Resp_FD_XIX_E3V_EVCANFD: id 0x1C420046, from Klima, frame-length=64, can-addressing-mode=EXTENDED, can-frame-rx-behavior=CAN-FD, can-frame-tx-behavior=CAN-FD
        n pdu ISOx_Klima_Resp_FD_XIX_E3V_EVCANFD: length=64
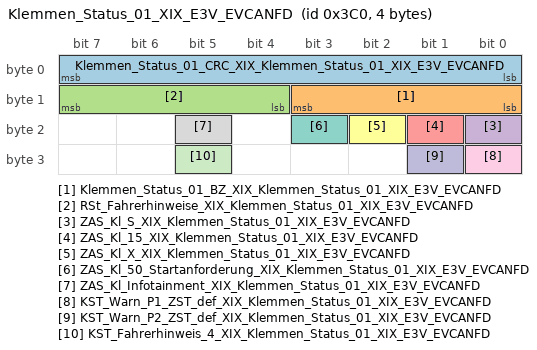
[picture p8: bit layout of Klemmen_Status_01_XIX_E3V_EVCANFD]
      frame Klemmen_Status_01_XIX_E3V_EVCANFD: id 0x3C0, to Klima, frame-length=4, can-addressing-mode=STANDARD, can-frame-rx-behavior=CAN-FD, can-frame-tx-behavior=CAN-FD
        pdu Klemmen_Status_01_XIX_E3V_EVCANFD: length=4, minimum-delay=0.01, transmission-mode-true-timing={cyclic-timing={time-offset=0.0, time-period=0.1}, event-controlled-timing={number-of-repetitions=0, repetition-period=0.0}}, unused-bit-pattern=0  # MQB
          signal Klemmen_Status_01_CRC_XIX_Klemmen_Status_01_XIX_E3V_EVCANFD: start 0, 8 bit, little-endian, data-type-policy=OVERRIDE, i-signal-type=PRIMITIVE, base-type=BT_Klemmen_Status_01_CRC, compu {phys=raw for raw 0..255}, range phys 0..255, raw 0..255, transfer-property=PENDING  # Für MLB: "Berechnung siehe Lastenheft "Kommunikationsabsicherung für FlexRay und CAN"" Ab MQB und MLBevo: "Berechnung siehe Lastenheft "End-to-End Kommunikationsabsicherung"" Endwerte siehe Begleitdokument "S-PDU Kennungsfolgen"
          signal Klemmen_Status_01_BZ_XIX_Klemmen_Status_01_XIX_E3V_EVCANFD: start 8, 4 bit, little-endian, data-type-policy=OVERRIDE, i-signal-type=PRIMITIVE, base-type=BT_Klemmen_Status_01_BZ, compu {phys=raw for raw 0..15}, range phys 0..15, raw 0..15, transfer-property=PENDING  # 4bit Botschaftszaehler; wird in jeder Sendebotschaft inkrementiert
          signal RSt_Fahrerhinweise_XIX_Klemmen_Status_01_XIX_E3V_EVCANFD: start 12, 4 bit, little-endian, data-type-policy=OVERRIDE, i-signal-type=PRIMITIVE, init-value=0, base-type=BT_RSt_Fahrerhinweise, compu {0=Cx0_Init (CM_RSt_Fahrerhinweise_Cx0_Init), 1=Cx1_Fahreruebernahme_Hinweis_ZAT_Automat_ohne_Gong (CM_RSt_Fahrerhinweise_Cx1_Fahreruebernahme_Hinweis_ZAT_Automat_ohne_Gong), 2=Cx2_Fahreruebernahme_Hinweis_ZAT_Automat_mit_Gong (CM_RSt_Fahrerhinweise_Cx2_Fahreruebernahme_Hinweis_ZAT_Automat_mit_Gong), 3=Cx3_Fahreruebernahme_Hinweis_ZAT_Handschalter_ohne_Gong (CM_RSt_Fahrerhinweise_Cx3_Fahreruebernahme_Hinweis_ZAT_Handschalter_ohne_Gong), 4=Cx4_Fahreruebernahme_Hinweis_ZAT_Handschalter_mit_Gong (CM_RSt_Fahrerhinweise_Cx4_Fahreruebernahme_Hinweis_ZAT_Handschalter_mit_Gong), 5=Cx5_Fahreruebernahme_Hinweis_ZAS_Automat_ohne_Gong (CM_RSt_Fahrerhinweise_Cx5_Fahreruebernahme_Hinweis_ZAS_Automat_ohne_Gong), 6=Cx6_Fahreruebernahme_Hinweis_ZAS_Automat_mit_Gong (CM_RSt_Fahrerhinweise_Cx6_Fahreruebernahme_Hinweis_ZAS_Automat_mit_Gong), 7=Cx7_Fahreruebernahme_Hinweis_ZAS_Handschalter_ohne_Gong (CM_RSt_Fahrerhinweise_Cx7_Fahreruebernahme_Hinweis_ZAS_Handschalter_ohne_Gong), 8=Cx8_Fahreruebernahme_Hinweis_ZAS_Handschalter_mit_Gong (CM_RSt_Fahrerhinweise_Cx8_Fahreruebernahme_Hinweis_ZAS_Handschalter_mit_Gong), 9=Cx9_RemoteStart_aktiv_ohne_Gong (CM_RSt_Fahrerhinweise_Cx9_RemoteStart_aktiv_ohne_Gong), 10=Cxa_RemoteStart_aktiv_mit_Gong (CM_RSt_Fahrerhinweise_Cxa_RemoteStart_aktiv_mit_Gong), 11=Cxb_void (CM_RSt_Fahrerhinweise_Cxb_void), 12=Cxc_void (CM_RSt_Fahrerhinweise_Cxc_void), 13=Cxd_void (CM_RSt_Fahrerhinweise_Cxd_void), 14=Cxe_void (CM_RSt_Fahrerhinweise_Cxe_void), 15=Cxf_void (CM_RSt_Fahrerhinweise_Cxf_void)}, range raw 0..15, transfer-property=TRIGGERED-ON-CHANGE-WITHOUT-REPETITION  # Über das Signal fordert das BCM Fahrerhinweise im Kombi für die Funktion RemoteStart an.
          signal ZAS_Kl_S_XIX_Klemmen_Status_01_XIX_E3V_EVCANFD: start 16, 1 bit, little-endian, data-type-policy=OVERRIDE, i-signal-type=PRIMITIVE, init-value=0, base-type=BT_ZAS_Kl_S, compu {0=Cx0_aus (CM_ZAS_Kl_S_Cx0_aus), 1=Cx1_S_Kontakt_ein (CM_ZAS_Kl_S_Cx1_S_Kontakt_ein)}, range raw 0..1, transfer-property=TRIGGERED-ON-CHANGE-WITHOUT-REPETITION, to Klima(timeout 1 s)  # Klemme S: S-Kontakt (Schluessel steckt)
          signal ZAS_Kl_15_XIX_Klemmen_Status_01_XIX_E3V_EVCANFD: start 17, 1 bit, little-endian, data-type-policy=OVERRIDE, i-signal-type=PRIMITIVE, init-value=0, base-type=BT_ZAS_Kl_15, compu {0=Cx0_aus (CM_ZAS_Kl_15_Cx0_aus), 1=Cx1_ein (CM_ZAS_Kl_15_Cx1_ein)}, range raw 0..1, transfer-property=TRIGGERED-ON-CHANGE-WITHOUT-REPETITION, to Klima(timeout 1 s)  # Klemme 15: Zuendung (SW-Kl.15)
          signal ZAS_Kl_X_XIX_Klemmen_Status_01_XIX_E3V_EVCANFD: start 18, 1 bit, little-endian, data-type-policy=OVERRIDE, i-signal-type=PRIMITIVE, init-value=0, base-type=BT_ZAS_Kl_X, compu {0=Cx0_aus (CM_ZAS_Kl_X_Cx0_aus), 1=Cx1_ein (CM_ZAS_Kl_X_Cx1_ein)}, range raw 0..1, transfer-property=TRIGGERED-ON-CHANGE-WITHOUT-REPETITION  # Klemme 75
          signal ZAS_Kl_50_Startanforderung_XIX_Klemmen_Status_01_XIX_E3V_EVCANFD: start 19, 1 bit, little-endian, data-type-policy=OVERRIDE, i-signal-type=PRIMITIVE, init-value=0, base-type=BT_ZAS_Kl_50_Startanforderung, compu {0=Cx0_aus (CM_ZAS_Kl_50_Startanforderung_Cx0_aus), 1=Cx1_KL50_ein_Startwunsch_Fahrer (CM_ZAS_Kl_50_Startanforderung_Cx1_KL50_ein_Startwunsch_Fahrer)}, range raw 0..1, transfer-property=TRIGGERED-ON-CHANGE-WITHOUT-REPETITION  # Klemme 50: Startwunsch Fahrer
          signal ZAS_Kl_Infotainment_XIX_Klemmen_Status_01_XIX_E3V_EVCANFD: start 21, 1 bit, little-endian, data-type-policy=OVERRIDE, i-signal-type=PRIMITIVE, init-value=0, base-type=BT_ZAS_Kl_Infotainment, compu {0=Cx0_inaktiv (CM_ZAS_Kl_Infotainment_Cx0_inaktiv), 1=Cx1_aktiv (CM_ZAS_Kl_Infotainment_Cx1_aktiv)}, range raw 0..1, transfer-property=TRIGGERED-ON-CHANGE-WITHOUT-REPETITION  # Separate Klemmeninformation für das Infotainment. Signal entspricht im wesentlichen einer Klemme S Information, kann aber über einen Vor - bzw. Nachlauf zu Klemme S verfügen. Ein konkreter Anwendungsfall für einen Nachlauf ist die Abschaltung der Klemme 15 über Verlassenskonzept, bei der ein Nachlauf des Infotainments benötigt wird.
          signal KST_Warn_P1_ZST_def_XIX_Klemmen_Status_01_XIX_E3V_EVCANFD: start 24, 1 bit, little-endian, data-type-policy=OVERRIDE, i-signal-type=PRIMITIVE, init-value=0, base-type=BT_KST_Warn_P1_ZST_def, compu {0=Cx0_nicht_defekt (CM_KST_Warn_P1_ZST_def_Cx0_nicht_defekt), 1=Cx1_defekt (CM_KST_Warn_P1_ZST_def_Cx1_defekt)}, range raw 0..1, transfer-property=TRIGGERED-ON-CHANGE-WITHOUT-REPETITION  # Kombi Prio Warnung Klemmensteuerung Zündschloß defekt, Service aufsuchen!
          signal KST_Warn_P2_ZST_def_XIX_Klemmen_Status_01_XIX_E3V_EVCANFD: start 25, 1 bit, little-endian, data-type-policy=OVERRIDE, i-signal-type=PRIMITIVE, init-value=0, base-type=BT_KST_Warn_P2_ZST_def, compu {0=Cx0_nicht_defekt (CM_KST_Warn_P2_ZST_def_Cx0_nicht_defekt), 1=Cx1_defekt (CM_KST_Warn_P2_ZST_def_Cx1_defekt)}, range raw 0..1, transfer-property=TRIGGERED-ON-CHANGE-WITHOUT-REPETITION  # Kombi Prio Warnung Klemmensteuerung Zündschloß defekt!
          signal KST_Fahrerhinweis_4_XIX_Klemmen_Status_01_XIX_E3V_EVCANFD: start 29, 1 bit, little-endian, data-type-policy=OVERRIDE, i-signal-type=PRIMITIVE, init-value=0, base-type=BT_KST_Fahrerhinweis_4, compu {0=Cx0_inaktiv (CM_KST_Fahrerhinweis_4_Cx0_inaktiv), 1=Cx1_aktiv (CM_KST_Fahrerhinweis_4_Cx1_aktiv)}, range raw 0..1, transfer-property=TRIGGERED-ON-CHANGE-WITHOUT-REPETITION  # Signalisierung Fahrerhinweis 4 der Klemmensteuerung an das Kombi
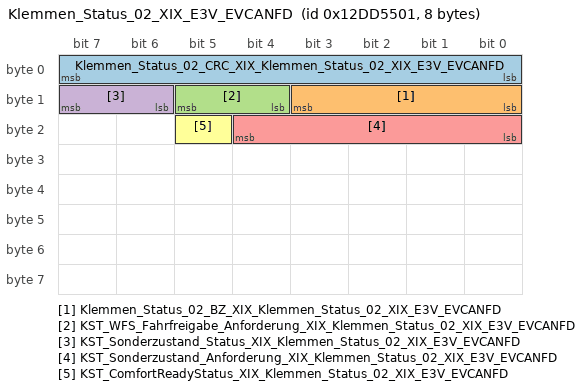
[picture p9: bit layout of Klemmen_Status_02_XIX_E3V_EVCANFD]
      frame Klemmen_Status_02_XIX_E3V_EVCANFD: id 0x12DD5501, to Klima, frame-length=8, can-addressing-mode=EXTENDED, can-frame-rx-behavior=CAN-FD, can-frame-tx-behavior=CAN-FD
        pdu Klemmen_Status_02_XIX_E3V_EVCANFD: length=8, minimum-delay=0.01, transmission-mode-true-timing={cyclic-timing={time-offset=0.0, time-period=1.0}, event-controlled-timing={number-of-repetitions=5, repetition-period=0.1}}, unused-bit-pattern=0
          signal Klemmen_Status_02_CRC_XIX_Klemmen_Status_02_XIX_E3V_EVCANFD: start 0, 8 bit, little-endian, data-type-policy=OVERRIDE, i-signal-type=PRIMITIVE, base-type=BT_Klemmen_Status_02_CRC, compu {phys=raw for raw 0..255}, range phys 0..255, raw 0..255, transfer-property=PENDING  # Für MLB: Berechnung siehe Lastenheft "Kommunikationsabsicherung für FlexRay und CAN" Ab MQB und MLBevo: Berechnung siehe Lastenheft "End-to-End Kommunikationsabsicherung" Endwerte siehe Begleitdokument "S-PDU Kennungsfolgen"
          signal Klemmen_Status_02_BZ_XIX_Klemmen_Status_02_XIX_E3V_EVCANFD: start 8, 4 bit, little-endian, data-type-policy=OVERRIDE, i-signal-type=PRIMITIVE, base-type=BT_Klemmen_Status_02_BZ, compu {phys=raw for raw 0..15}, range phys 0..15, raw 0..15, transfer-property=PENDING  # 4bit Botschaftszähler, wird mit jeder Sendebotschaft inkrementiert
          signal KST_WFS_Fahrfreigabe_Anforderung_XIX_Klemmen_Status_02_XIX_E3V_EVCANFD: start 12, 2 bit, little-endian, data-type-policy=OVERRIDE, i-signal-type=PRIMITIVE, init-value=0, base-type=BT_KST_WFS_Fahrfreigabe_Anforderung, compu {0=Cx0_Keine (CM_KST_WFS_Fahrfreigabe_Anforderung_Cx0_Keine), 1=Cx1_Uneingeschraenkt (CM_KST_WFS_Fahrfreigabe_Anforderung_Cx1_Uneingeschraenkt), 2=Cx2_Eingeschraenkt (CM_KST_WFS_Fahrfreigabe_Anforderung_Cx2_Eingeschraenkt)}, range raw 0..2, transfer-property=TRIGGERED-ON-CHANGE  # Hiermit wird den Wegfahrsperren-Teilnehmern signalisiert welche Art der Fahrfreigabe von der anfordernden Sonderfunktion benötigt wird
          signal KST_Sonderzustand_Status_XIX_Klemmen_Status_02_XIX_E3V_EVCANFD: start 14, 2 bit, little-endian, data-type-policy=OVERRIDE, i-signal-type=PRIMITIVE, init-value=0, base-type=BT_KST_Sonderzustand_Status, invalid-value=Invalid_KST_Sonderzustand_Status_XIX_Klemmen_Status_02_XIX_E3V_EVCANFD:3, compu {0=Cx0_Init (CM_KST_Sonderzustand_Status_Cx0_Init), 1=Cx1_Uebergang_neue_Anforderung (CM_KST_Sonderzustand_Status_Cx1_Uebergang_neue_Anforderung), 2=Cx2_Aktiv (CM_KST_Sonderzustand_Status_Cx2_Aktiv), 3=Cx3_Fehler (CM_KST_Sonderzustand_Status_Cx3_Fehler)}, range raw 0..3, transfer-property=TRIGGERED-ON-CHANGE, to Klima(timeout 5 s)  # Hiermit wird signalisiert, dass eine Sonderfunktion aktiv ist und die Klemme 15 durch diese angefordert wurde bzw. ein Übergang von Sonderfunktionen stattfindet
          signal KST_Sonderzustand_Anforderung_XIX_Klemmen_Status_02_XIX_E3V_EVCANFD: start 16, 5 bit, little-endian, data-type-policy=OVERRIDE, i-signal-type=PRIMITIVE, init-value=0, base-type=BT_KST_Sonderzustand_Anforderung, invalid-value=Invalid_KST_Sonderzustand_Anforderung_XIX_Klemmen_Status_02_XIX_E3V_EVCANFD:31, compu {0=Cx0_Init (CM_KST_Sonderzustand_Anforderung_Cx0_Init), 1=Cx1_RemoteStart (CM_KST_Sonderzustand_Anforderung_Cx1_RemoteStart), 2=Cx2_RemoteParkAssist (CM_KST_Sonderzustand_Anforderung_Cx2_RemoteParkAssist), 3=Cx3_IntelligentParkAssist (CM_KST_Sonderzustand_Anforderung_Cx3_IntelligentParkAssist), 4=Cx4_TrainiertesParken (CM_KST_Sonderzustand_Anforderung_Cx4_TrainiertesParken), 5=Cx5_OnlineRemoteUpdate (CM_KST_Sonderzustand_Anforderung_Cx5_OnlineRemoteUpdate), 6=Cx6_Einfrierschutz (CM_KST_Sonderzustand_Anforderung_Cx6_Einfrierschutz), 7=Cx7_Klemme15ViaDiagnose (CM_KST_Sonderzustand_Anforderung_Cx7_Klemme15ViaDiagnose), 8=Cx8_RueckwandklappenSicherungPDC (CM_KST_Sonderzustand_Anforderung_Cx8_RueckwandklappenSicherungPDC), 9=Cx9_ParkHausPilot (CM_KST_Sonderzustand_Anforderung_Cx9_ParkHausPilot), 10=Cxa_AnhaengerAnkuppelAssistent (CM_KST_Sonderzustand_Anforderung_Cxa_AnhaengerAnkuppelAssistent), 11=Cxb_MotorWeiterlaufSchaltung (CM_KST_Sonderzustand_Anforderung_Cxb_MotorWeiterlaufSchaltung), 12=Cxc_RemoteActivationDeactivationAD (CM_KST_Sonderzustand_Anforderung_Cxc_RemoteActivationDeactivationAD), 31=Cx1f_Fehler (CM_KST_Sonderzustand_Anforderung_Cx1f_Fehler)}, range raw 0..31, transfer-property=TRIGGERED-ON-CHANGE  # Hiermit wird die aktive bzw. aktuell angeforderte (s. KST_Sonderzustand_Status) Sonderfunktion identifiziert
          signal KST_ComfortReadyStatus_XIX_Klemmen_Status_02_XIX_E3V_EVCANFD: start 21, 1 bit, little-endian, data-type-policy=OVERRIDE, i-signal-type=PRIMITIVE, init-value=0, base-type=BT_KST_ComfortReadyStatus, compu {0=Cx0_aus (CM_KST_ComfortReadyStatus_Cx0_aus), 1=Cx1_ComfortReadyStatus_ein (CM_KST_ComfortReadyStatus_Cx1_ComfortReadyStatus_ein)}, range raw 0..1, transfer-property=TRIGGERED-ON-CHANGE  # Zustand des ComfortReadyStatus über den Komfortfunktionen aktiviert werden können.
      frame Klima_03_XIX_E3V_EVCANFD: id 0x66E, from Klima, frame-length=8, can-addressing-mode=STANDARD, can-frame-rx-behavior=CAN-FD, can-frame-tx-behavior=CAN-FD
        pdu Klima_03_XIX_E3V_EVCANFD: length=8, minimum-delay=0.2, transmission-mode-true-timing={cyclic-timing={time-offset=0.0, time-period=2.0}, event-controlled-timing={number-of-repetitions=0, repetition-period=0.0}}, unused-bit-pattern=0  # ab MQB 7.3
          signal KL_STL_aktiv_XIX_Klima_03_XIX_E3V_EVCANFD: start 0, 1 bit, little-endian, data-type-policy=OVERRIDE, i-signal-type=PRIMITIVE, init-value=0, base-type=BT_KL_STL_aktiv, compu {0=Cx0_Standlueftung_nicht_aktiv (CM_KL_STL_aktiv_Cx0_Standlueftung_nicht_aktiv), 1=Cx1_Standlueftung_aktiv (CM_KL_STL_aktiv_Cx1_Standlueftung_aktiv)}, range raw 0..1, transfer-property=TRIGGERED-ON-CHANGE-WITHOUT-REPETITION  # Betriebsstatus Standlueftung
          signal KL_STH_aktiv_XIX_Klima_03_XIX_E3V_EVCANFD: start 1, 1 bit, little-endian, data-type-policy=OVERRIDE, i-signal-type=PRIMITIVE, init-value=0, base-type=BT_KL_STH_aktiv, compu {0=Cx0_Standheizung_nicht_aktiv (CM_KL_STH_aktiv_Cx0_Standheizung_nicht_aktiv), 1=Cx1_Standheizung_aktiv (CM_KL_STH_aktiv_Cx1_Standheizung_aktiv)}, range raw 0..1, transfer-property=TRIGGERED-ON-CHANGE-WITHOUT-REPETITION  # Betriebsstatus Standheizung
          signal KL_Solarluefter_aktiv_XIX_Klima_03_XIX_E3V_EVCANFD: start 2, 1 bit, little-endian, data-type-policy=OVERRIDE, i-signal-type=PRIMITIVE, init-value=0, base-type=BT_KL_Solarluefter_aktiv, compu {0=Cx0_Solarluefter_nicht_aktiv (CM_KL_Solarluefter_aktiv_Cx0_Solarluefter_nicht_aktiv), 1=Cx1_Solarluefter_aktiv_auto (CM_KL_Solarluefter_aktiv_Cx1_Solarluefter_aktiv_auto) (Solarluefter_aktiv__auto)}, range raw 0..1, transfer-property=TRIGGERED-ON-CHANGE-WITHOUT-REPETITION  # Betriebsstatus Solarluefter
          signal KL_Umluft_Taste_XIX_Klima_03_XIX_E3V_EVCANFD: start 3, 1 bit, little-endian, data-type-policy=OVERRIDE, i-signal-type=PRIMITIVE, init-value=0, base-type=BT_KL_Umluft_Taste, compu {0=Cx0_Taste_nicht_gedrueckt (CM_KL_Umluft_Taste_Cx0_Taste_nicht_gedrueckt), 1=Cx1_Taste_gedrueckt (CM_KL_Umluft_Taste_Cx1_Taste_gedrueckt)}, range raw 0..1, transfer-property=TRIGGERED-ON-CHANGE-WITHOUT-REPETITION  # Betaetigung Umlufttaste
          signal KL_Geblaese_Fond_Status_XIX_Klima_03_XIX_E3V_EVCANFD: start 4, 4 bit, little-endian, data-type-policy=OVERRIDE, i-signal-type=PRIMITIVE, init-value=14, base-type=BT_KL_Geblaese_Fond_Status, invalid-value=Invalid_KL_Geblaese_Fond_Status_XIX_Klima_03_XIX_E3V_EVCANFD:15, compu {0=Cx0_Geblaese_aus (CM_KL_Geblaese_Fond_Status_Cx0_Geblaese_aus), 1=Cx1_Geblaesestufe_10 (CM_KL_Geblaese_Fond_Status_Cx1_Geblaesestufe_10), 2=Cx2_Geblaesestufe_20 (CM_KL_Geblaese_Fond_Status_Cx2_Geblaesestufe_20), 3=Cx3_Geblaesestufe_30 (CM_KL_Geblaese_Fond_Status_Cx3_Geblaesestufe_30), 4=Cx4_Geblaesestufe_40 (CM_KL_Geblaese_Fond_Status_Cx4_Geblaesestufe_40), 5=Cx5_Geblaesestufe_50 (CM_KL_Geblaese_Fond_Status_Cx5_Geblaesestufe_50), 6=Cx6_Geblaesestufe_60 (CM_KL_Geblaese_Fond_Status_Cx6_Geblaesestufe_60), 7=Cx7_Geblaesestufe_70 (CM_KL_Geblaese_Fond_Status_Cx7_Geblaesestufe_70), 8=Cx8_Geblaesestufe_80 (CM_KL_Geblaese_Fond_Status_Cx8_Geblaesestufe_80), 9=Cx9_Geblaesestufe_90 (CM_KL_Geblaese_Fond_Status_Cx9_Geblaesestufe_90), 10=Cxa_Geblaesestufe_100 (CM_KL_Geblaese_Fond_Status_Cxa_Geblaesestufe_100), 14=Cxe_Init (CM_KL_Geblaese_Fond_Status_Cxe_Init), 15=Cxf_Fehler (CM_KL_Geblaese_Fond_Status_Cxf_Fehler)}, range raw 0..15, transfer-property=PENDING  # Status Geblaese
          signal KL_STH_Ansteuerung_XIX_Klima_03_XIX_E3V_EVCANFD: start 8, 2 bit, little-endian, data-type-policy=OVERRIDE, i-signal-type=PRIMITIVE, init-value=0, base-type=BT_KL_STH_Ansteuerung, compu {0=Cx0_Aus (CM_KL_STH_Ansteuerung_Cx0_Aus), 1=Cx1_Ein (CM_KL_STH_Ansteuerung_Cx1_Ein), 2=Cx2_Ein_mit_Motorvorwaermung (CM_KL_STH_Ansteuerung_Cx2_Ein_mit_Motorvorwaermung), 3=Cx3_Heizleistung_reduziert (CM_KL_STH_Ansteuerung_Cx3_Heizleistung_reduziert)}, range raw 0..3, transfer-property=TRIGGERED-ON-CHANGE-WITHOUT-REPETITION  # Ansteuerung STH
          signal KL_STH_Betriebsdauer_XIX_Klima_03_XIX_E3V_EVCANFD: start 10, 6 bit, little-endian, data-type-policy=OVERRIDE, i-signal-type=PRIMITIVE, init-value=0, base-type=BT_KL_STH_Betriebsdauer, compu {phys=raw for raw 0..60; unit Unit_Minut}, range phys 0..60 Unit_Minut, raw 0..60, unit=Unit_Minut, transfer-property=TRIGGERED-ON-CHANGE-WITHOUT-REPETITION  # Betriebsdauer STH
          signal KL_Magnetventil_XIX_Klima_03_XIX_E3V_EVCANFD: start 16, 1 bit, little-endian, data-type-policy=OVERRIDE, i-signal-type=PRIMITIVE, init-value=0, base-type=BT_KL_Magnetventil, compu {0=Cx0_Aus (CM_KL_Magnetventil_Cx0_Aus), 1=Cx1_Ein (CM_KL_Magnetventil_Cx1_Ein)}, range raw 0..1, transfer-property=TRIGGERED-ON-CHANGE-WITHOUT-REPETITION  # Anforderung des Bypassventils.
          signal KL_WaPu_XIX_Klima_03_XIX_E3V_EVCANFD: start 17, 1 bit, little-endian, data-type-policy=OVERRIDE, i-signal-type=PRIMITIVE, init-value=0, base-type=BT_KL_WaPu, compu {0=Cx0_Wasserpumpe_aus (CM_KL_WaPu_Cx0_Wasserpumpe_aus), 1=Cx1_Wasserpumpe_aktiv (CM_KL_WaPu_Cx1_Wasserpumpe_aktiv)}, range raw 0..1, transfer-property=TRIGGERED-ON-CHANGE-WITHOUT-REPETITION  # Ansteuerung der Standheizungswasserpumpe
          signal KL_Geblaese_Status_XIX_Klima_03_XIX_E3V_EVCANFD: start 18, 4 bit, little-endian, data-type-policy=OVERRIDE, i-signal-type=PRIMITIVE, init-value=14, base-type=BT_KL_Geblaese_Status, invalid-value=Invalid_KL_Geblaese_Status_XIX_Klima_03_XIX_E3V_EVCANFD:15, compu {0=Cx0_Geblaese_aus (CM_KL_Geblaese_Status_Cx0_Geblaese_aus), 1=Cx1_Geblaesestufe_10 (CM_KL_Geblaese_Status_Cx1_Geblaesestufe_10), 2=Cx2_Geblaesestufe_20 (CM_KL_Geblaese_Status_Cx2_Geblaesestufe_20), 3=Cx3_Geblaesestufe_30 (CM_KL_Geblaese_Status_Cx3_Geblaesestufe_30), 4=Cx4_Geblaesestufe_40 (CM_KL_Geblaese_Status_Cx4_Geblaesestufe_40), 5=Cx5_Geblaesestufe_50 (CM_KL_Geblaese_Status_Cx5_Geblaesestufe_50), 6=Cx6_Geblaesestufe_60 (CM_KL_Geblaese_Status_Cx6_Geblaesestufe_60), 7=Cx7_Geblaesestufe_70 (CM_KL_Geblaese_Status_Cx7_Geblaesestufe_70), 8=Cx8_Geblaesestufe_80 (CM_KL_Geblaese_Status_Cx8_Geblaesestufe_80), 9=Cx9_Geblaesestufe_90 (CM_KL_Geblaese_Status_Cx9_Geblaesestufe_90), 10=Cxa_Geblaesestufe_100 (CM_KL_Geblaese_Status_Cxa_Geblaesestufe_100), 14=Cxe_Init (CM_KL_Geblaese_Status_Cxe_Init), 15=Cxf_Fehler (CM_KL_Geblaese_Status_Cxf_Fehler)}, range raw 0..15, transfer-property=PENDING  # Status Geblaese
          signal KL_Restwaerme_aktiv_XIX_Klima_03_XIX_E3V_EVCANFD: start 22, 1 bit, little-endian, data-type-policy=OVERRIDE, i-signal-type=PRIMITIVE, init-value=0, base-type=BT_KL_Restwaerme_aktiv, compu {0=Cx0_inaktiv (CM_KL_Restwaerme_aktiv_Cx0_inaktiv), 1=Cx1_aktiv (CM_KL_Restwaerme_aktiv_Cx1_aktiv)}, range raw 0..1, transfer-property=TRIGGERED-ON-CHANGE-WITHOUT-REPETITION  # Signal zur Aktivierung/Deaktivierung der Wasserpumpe bei Restwärme; reduzierte IRÜ Empfindlichkeit
          signal KL_Kompressorkupplung_XIX_Klima_03_XIX_E3V_EVCANFD: start 23, 1 bit, little-endian, data-type-policy=OVERRIDE, i-signal-type=PRIMITIVE, init-value=0, base-type=BT_KL_Kompressorkupplung, compu {0=Cx0_oeffnen (CM_KL_Kompressorkupplung_Cx0_oeffnen), 1=Cx1_schliessen (CM_KL_Kompressorkupplung_Cx1_schliessen)}, range raw 0..1, transfer-property=TRIGGERED-ON-CHANGE-WITHOUT-REPETITION  # Signal zur Aktivierung/Deaktivierung der Kompressorkupplung
          signal KL_BCmE_Livetip_Freigabe_XIX_Klima_03_XIX_E3V_EVCANFD: start 24, 1 bit, little-endian, data-type-policy=OVERRIDE, i-signal-type=PRIMITIVE, init-value=0, base-type=BT_KL_BCmE_Livetip_Freigabe, compu {0=Cx0_Anzeige_Livetip_nicht_zulaessig (CM_KL_BCmE_Livetip_Freigabe_Cx0_Anzeige_Livetip_nicht_zulaessig), 1=Cx1_Anzeige_Livetip_zulaessig (CM_KL_BCmE_Livetip_Freigabe_Cx1_Anzeige_Livetip_zulaessig)}, range raw 0..1, transfer-property=TRIGGERED-ON-CHANGE-WITHOUT-REPETITION  # Status der Klimaanlage. Zeigt an, ob der Livetip "Fenster schließen wegen Ineffizienz Klimaanlage" sinvollerweise angezeigt werden soll
          signal KL_SH_Soll_hl_XIX_Klima_03_XIX_E3V_EVCANFD: start 25, 3 bit, little-endian, data-type-policy=OVERRIDE, i-signal-type=PRIMITIVE, init-value=0, base-type=BT_KL_SH_Soll_hl, transfer-property=TRIGGERED-ON-CHANGE-WITHOUT-REPETITION  # Einstellung Sitzheizung hinten links (0...6)
          signal KL_SH_Soll_hr_XIX_Klima_03_XIX_E3V_EVCANFD: start 28, 3 bit, little-endian, data-type-policy=OVERRIDE, i-signal-type=PRIMITIVE, init-value=0, base-type=BT_KL_SH_Soll_hr, transfer-property=TRIGGERED-ON-CHANGE-WITHOUT-REPETITION  # Einstellung Sitzheizung hinten rechts (0...6)
          signal KL_ErwVK_Anf_XIX_Klima_03_XIX_E3V_EVCANFD: start 31, 1 bit, little-endian, data-type-policy=OVERRIDE, i-signal-type=PRIMITIVE, init-value=0, base-type=BT_KL_ErwVK_Anf, compu {0=Cx0_nicht_angefordert (CM_KL_ErwVK_Anf_Cx0_nicht_angefordert), 1=Cx1_angefordert (CM_KL_ErwVK_Anf_Cx1_angefordert)}, range raw 0..1, transfer-property=TRIGGERED-ON-CHANGE-WITHOUT-REPETITION  # Erweiterte Voko angefordertert / aktiv
          signal KL_Innen_Temp_XIX_Klima_03_XIX_E3V_EVCANFD: start 32, 8 bit, little-endian, data-type-policy=OVERRIDE, i-signal-type=PRIMITIVE, init-value=254, base-type=BT_KL_Innen_Temp, invalid-value=Invalid_KL_Innen_Temp_XIX_Klima_03_XIX_E3V_EVCANFD:255, compu {phys=raw*0.5-50 for raw 0..252, 253=Cxfd_nicht_verbaut (CM_KL_Innen_Temp_Cxfd_nicht_verbaut), 254=Cxfe_nicht_verfuegbar (CM_KL_Innen_Temp_Cxfe_nicht_verfuegbar), 255=Cxff_Fehler (CM_KL_Innen_Temp_Cxff_Fehler); unit Unit_DegreCelsi}, range phys -50..76 Unit_DegreCelsi, raw 0..255, unit=Unit_DegreCelsi, transfer-property=PENDING  # Innentemperatur
          signal KL_I_Geblaese_Fond_XIX_Klima_03_XIX_E3V_EVCANFD: start 40, 8 bit, little-endian, data-type-policy=OVERRIDE, i-signal-type=PRIMITIVE, init-value=0, base-type=BT_KL_I_Geblaese_Fond, invalid-value=Invalid_KL_I_Geblaese_Fond_XIX_Klima_03_XIX_E3V_EVCANFD:255, compu {phys=raw*0.25 for raw 0..254, 255=Cxff_Fehler (CM_KL_I_Geblaese_Fond_Cxff_Fehler); unit Unit_Amper}, range phys 0..63.5 Unit_Amper, raw 0..255, unit=Unit_Amper, transfer-property=TRIGGERED-ON-CHANGE-WITHOUT-REPETITION  # Stromaufnahme Gebläse Heck
          signal KL_Anf_AussenspiegelHzg_XIX_Klima_03_XIX_E3V_EVCANFD: start 48, 1 bit, little-endian, data-type-policy=OVERRIDE, i-signal-type=PRIMITIVE, init-value=0, base-type=BT_KL_Anf_AussenspiegelHzg, compu {0=Cx0_nicht_angefordert (CM_KL_Anf_AussenspiegelHzg_Cx0_nicht_angefordert), 1=Cx1_angefordert (CM_KL_Anf_AussenspiegelHzg_Cx1_angefordert)}, range raw 0..1, transfer-property=TRIGGERED-ON-CHANGE-WITHOUT-REPETITION  # Anforderung Außenspiegelheizung seitens Klimafunktion (z.B. bei Erweiterter VoKo)
          signal KL_Heizkreisventilstellung_XIX_Klima_03_XIX_E3V_EVCANFD: start 49, 2 bit, little-endian, data-type-policy=OVERRIDE, i-signal-type=PRIMITIVE, init-value=0, base-type=BT_KL_Heizkreisventilstellung, invalid-value=Invalid_KL_Heizkreisventilstellung_XIX_Klima_03_XIX_E3V_EVCANFD:3, compu {0=Cx0_Init (CM_KL_Heizkreisventilstellung_Cx0_Init), 1=Cx1_Ventilstellung_gem_Anforderung (CM_KL_Heizkreisventilstellung_Cx1_Ventilstellung_gem_Anforderung), 2=Cx2_Ventilstellung_abweichend_Anf (CM_KL_Heizkreisventilstellung_Cx2_Ventilstellung_abweichend_Anf), 3=Cx3_Fehler (CM_KL_Heizkreisventilstellung_Cx3_Fehler)}, range raw 0..3, transfer-property=PENDING  # Bei MQB PHEV: Stellung Heizkreisventil Motor
          signal KL_FSH_Automatikbetrieb_XIX_Klima_03_XIX_E3V_EVCANFD: start 51, 1 bit, little-endian, data-type-policy=OVERRIDE, i-signal-type=PRIMITIVE, init-value=0, base-type=BT_KL_FSH_Automatikbetrieb, compu {0=Cx0_aus (CM_KL_FSH_Automatikbetrieb_Cx0_aus), 1=Cx1_angefordert_durch_Regelung (CM_KL_FSH_Automatikbetrieb_Cx1_angefordert_durch_Regelung)}, range raw 0..1, transfer-property=TRIGGERED-ON-CHANGE-WITHOUT-REPETITION  # Ermöglicht eine Unterscheidung von Anforderung FSH durch Kundenwunsch und Anforderung FSH durch Regelung des Klimasteuergeräts. Das Signal liegt als Pegel an.
          signal KL_SIH_LEH_Verteilung_VL_XIX_Klima_03_XIX_E3V_EVCANFD: start 52, 3 bit, little-endian, data-type-policy=OVERRIDE, i-signal-type=PRIMITIVE, init-value=0, base-type=BT_KL_SIH_LEH_Verteilung_VL, compu {0=Cx0_gleichmaessige_Verteilung (CM_KL_SIH_LEH_Verteilung_VL_Cx0_gleichmaessige_Verteilung), 1=Cx1_Sitz_Prio_Hoch (CM_KL_SIH_LEH_Verteilung_VL_Cx1_Sitz_Prio_Hoch), 2=Cx2_Sitz_Prio_Mittel (CM_KL_SIH_LEH_Verteilung_VL_Cx2_Sitz_Prio_Mittel), 3=Cx3_Sitz_Prio_Niedrig (CM_KL_SIH_LEH_Verteilung_VL_Cx3_Sitz_Prio_Niedrig), 4=Cx4_Lehne_Prio_Niedrig (CM_KL_SIH_LEH_Verteilung_VL_Cx4_Lehne_Prio_Niedrig), 5=Cx5_Lehne_Prio_Mittel (CM_KL_SIH_LEH_Verteilung_VL_Cx5_Lehne_Prio_Mittel), 6=Cx6_Lehne_Prio_Hoch (CM_KL_SIH_LEH_Verteilung_VL_Cx6_Lehne_Prio_Hoch)}, range raw 0..6, transfer-property=TRIGGERED-ON-CHANGE-WITHOUT-REPETITION  # Vom Kunden eingestellte Aufteilung der Heizleistung auf Sitzfläche und Lehnefläche für Sitz vorne links
          signal KL_SIH_LEL_Verteilung_VL_XIX_Klima_03_XIX_E3V_EVCANFD: start 55, 3 bit, little-endian, data-type-policy=OVERRIDE, i-signal-type=PRIMITIVE, init-value=0, base-type=BT_KL_SIH_LEL_Verteilung_VL, compu {0=Cx0_gleichmaessige_Verteilung (CM_KL_SIH_LEL_Verteilung_VL_Cx0_gleichmaessige_Verteilung), 1=Cx1_Sitz_Prio_Hoch (CM_KL_SIH_LEL_Verteilung_VL_Cx1_Sitz_Prio_Hoch), 2=Cx2_Sitz_Prio_Mittel (CM_KL_SIH_LEL_Verteilung_VL_Cx2_Sitz_Prio_Mittel), 3=Cx3_Sitz_Prio_Niedrig (CM_KL_SIH_LEL_Verteilung_VL_Cx3_Sitz_Prio_Niedrig), 4=Cx4_Lehne_Prio_Niedrig (CM_KL_SIH_LEL_Verteilung_VL_Cx4_Lehne_Prio_Niedrig), 5=Cx5_Lehne_Prio_Mittel (CM_KL_SIH_LEL_Verteilung_VL_Cx5_Lehne_Prio_Mittel), 6=Cx6_Lehne_Prio_Hoch (CM_KL_SIH_LEL_Verteilung_VL_Cx6_Lehne_Prio_Hoch)}, range raw 0..6, transfer-property=TRIGGERED-ON-CHANGE-WITHOUT-REPETITION  # Vom Kunden eingestellte Aufteilung der Lüftungsleistung auf Sitzfläche und Lehnenfläche für Sitz vorne links
          signal KL_SIH_LEH_Verteilung_VR_XIX_Klima_03_XIX_E3V_EVCANFD: start 58, 3 bit, little-endian, data-type-policy=OVERRIDE, i-signal-type=PRIMITIVE, init-value=0, base-type=BT_KL_SIH_LEH_Verteilung_VR, compu {0=Cx0_gleichmaessige_Verteilung (CM_KL_SIH_LEH_Verteilung_VR_Cx0_gleichmaessige_Verteilung), 1=Cx1_Sitz_Prio_Hoch (CM_KL_SIH_LEH_Verteilung_VR_Cx1_Sitz_Prio_Hoch), 2=Cx2_Sitz_Prio_Mittel (CM_KL_SIH_LEH_Verteilung_VR_Cx2_Sitz_Prio_Mittel), 3=Cx3_Sitz_Prio_Niedrig (CM_KL_SIH_LEH_Verteilung_VR_Cx3_Sitz_Prio_Niedrig), 4=Cx4_Lehne_Prio_Niedrig (CM_KL_SIH_LEH_Verteilung_VR_Cx4_Lehne_Prio_Niedrig), 5=Cx5_Lehne_Prio_Mittel (CM_KL_SIH_LEH_Verteilung_VR_Cx5_Lehne_Prio_Mittel), 6=Cx6_Lehne_Prio_Hoch (CM_KL_SIH_LEH_Verteilung_VR_Cx6_Lehne_Prio_Hoch)}, range raw 0..6, transfer-property=TRIGGERED-ON-CHANGE-WITHOUT-REPETITION  # Vom Kunden eingestellte Aufteilung der Heizleistung auf Sitzfläche und Lehnefläche für Sitz vorne rechts
          signal KL_SIH_LEL_Verteilung_VR_XIX_Klima_03_XIX_E3V_EVCANFD: start 61, 3 bit, little-endian, data-type-policy=OVERRIDE, i-signal-type=PRIMITIVE, init-value=0, base-type=BT_KL_SIH_LEL_Verteilung_VR, compu {0=Cx0_gleichmaessige_Verteilung (CM_KL_SIH_LEL_Verteilung_VR_Cx0_gleichmaessige_Verteilung), 1=Cx1_Sitz_Prio_Hoch (CM_KL_SIH_LEL_Verteilung_VR_Cx1_Sitz_Prio_Hoch), 2=Cx2_Sitz_Prio_Mittel (CM_KL_SIH_LEL_Verteilung_VR_Cx2_Sitz_Prio_Mittel), 3=Cx3_Sitz_Prio_Niedrig (CM_KL_SIH_LEL_Verteilung_VR_Cx3_Sitz_Prio_Niedrig), 4=Cx4_Lehne_Prio_Niedrig (CM_KL_SIH_LEL_Verteilung_VR_Cx4_Lehne_Prio_Niedrig), 5=Cx5_Lehne_Prio_Mittel (CM_KL_SIH_LEL_Verteilung_VR_Cx5_Lehne_Prio_Mittel), 6=Cx6_Lehne_Prio_Hoch (CM_KL_SIH_LEL_Verteilung_VR_Cx6_Lehne_Prio_Hoch)}, range raw 0..6, transfer-property=TRIGGERED-ON-CHANGE-WITHOUT-REPETITION  # Vom Kunden eingestellte Aufteilung der Lüftungsleistung auf Sitzfläche und Lehnenfläche für Sitz vorne rechts
      frame Klima_06_XIX_E3V_EVCANFD: id 0x671, from Klima, frame-length=8, can-addressing-mode=STANDARD, can-frame-rx-behavior=CAN-FD, can-frame-tx-behavior=CAN-FD
        pdu Klima_06_XIX_E3V_EVCANFD: length=8, minimum-delay=0.2, transmission-mode-true-timing={cyclic-timing={time-offset=0.0, time-period=2.0}, event-controlled-timing={number-of-repetitions=0, repetition-period=0.0}}, unused-bit-pattern=0
          signal KL_ZZ_Minute_XIX_Klima_06_XIX_E3V_EVCANFD: start 0, 6 bit, little-endian, data-type-policy=OVERRIDE, i-signal-type=PRIMITIVE, init-value=0, base-type=BT_KL_ZZ_Minute, compu {phys=raw for raw 0..59; unit Unit_Minut}, range phys 0..59 Unit_Minut, raw 0..59, unit=Unit_Minut, transfer-property=TRIGGERED-ON-CHANGE-WITHOUT-REPETITION  # Zielzeittimeranzeige im Display der Funkfernbedienung (Minute); Initwert ist der zuletzt gültige Wert
          signal KL_ZZ_Status_Timer_XIX_Klima_06_XIX_E3V_EVCANFD: start 6, 2 bit, little-endian, data-type-policy=OVERRIDE, i-signal-type=PRIMITIVE, init-value=0, base-type=BT_KL_ZZ_Status_Timer, compu {0=Cx0_Timer_n_aktiv_bzw_loeschen (CM_KL_ZZ_Status_Timer_Cx0_Timer_n_aktiv_bzw_loeschen), 1=Cx1_Timer_aktiv_bzw_aktivieren (CM_KL_ZZ_Status_Timer_Cx1_Timer_aktiv_bzw_aktivieren)}, range raw 0..1, transfer-property=TRIGGERED-ON-CHANGE-WITHOUT-REPETITION  # Timerstatusanzeige im Display der Funkfernbedienung (Timer aktiv/n.aktiv)
          signal KL_ZZ_Monat_XIX_Klima_06_XIX_E3V_EVCANFD: start 8, 4 bit, little-endian, data-type-policy=OVERRIDE, i-signal-type=PRIMITIVE, init-value=0, base-type=BT_KL_ZZ_Monat, compu {0=Cx0_Init (CM_KL_ZZ_Monat_Cx0_Init), phys=raw for raw 1..12; unit Unit_Month}, range phys 1..12 Unit_Month, raw 0..12, unit=Unit_Month, transfer-property=TRIGGERED-ON-CHANGE-WITHOUT-REPETITION  # Zielzeittimeranzeige im Display der Funkfernbedienung (Datum, Monat); Initwert ist der zuletzt gültige Wert
          signal KL_ErwVK_Scheibenheizung_XIX_Klima_06_XIX_E3V_EVCANFD: start 12, 1 bit, little-endian, data-type-policy=OVERRIDE, i-signal-type=PRIMITIVE, init-value=0, base-type=BT_KL_ErwVK_Scheibenheizung, compu {0=Cx0_nicht_aktiv (CM_KL_ErwVK_Scheibenheizung_Cx0_nicht_aktiv), 1=Cx1_Scheibenheizung_aktiv (CM_KL_ErwVK_Scheibenheizung_Cx1_Scheibenheizung_aktiv)}, range raw 0..1, transfer-property=TRIGGERED-ON-CHANGE-WITHOUT-REPETITION  # Erweiterte Voko Scheibenheizung
          signal KL_ZZ_Stunde_XIX_Klima_06_XIX_E3V_EVCANFD: start 16, 5 bit, little-endian, data-type-policy=OVERRIDE, i-signal-type=PRIMITIVE, init-value=0, base-type=BT_KL_ZZ_Stunde, compu {phys=raw for raw 0..23; unit Unit_Hours}, range phys 0..23 Unit_Hours, raw 0..23, unit=Unit_Hours, transfer-property=TRIGGERED-ON-CHANGE-WITHOUT-REPETITION  # Zielzeittimeranzeige im Display der Funkfernbedienung (Stunde); Initwert ist der zuletzt gültige Wert
          signal KL_ZZ_Betriebsmodus_XIX_Klima_06_XIX_E3V_EVCANFD: start 21, 3 bit, little-endian, data-type-policy=OVERRIDE, i-signal-type=PRIMITIVE, init-value=0, base-type=BT_KL_ZZ_Betriebsmodus, compu {0=Cx0_Do_not_Care (CM_KL_ZZ_Betriebsmodus_Cx0_Do_not_Care), 1=Cx1_ECO (CM_KL_ZZ_Betriebsmodus_Cx1_ECO), 2=Cx2_Standard (CM_KL_ZZ_Betriebsmodus_Cx2_Standard), 3=Cx3_Standard_plus (CM_KL_ZZ_Betriebsmodus_Cx3_Standard_plus), 4=Cx4_Comfort (CM_KL_ZZ_Betriebsmodus_Cx4_Comfort)}, range raw 0..4, transfer-property=TRIGGERED-ON-CHANGE-WITHOUT-REPETITION  # Betriebsdauerberechnung anhand Aussentemperaturauswertung mit Faktor "ZZ_Betriebsmodus"
          signal KL_ZZ_Tag_XIX_Klima_06_XIX_E3V_EVCANFD: start 24, 5 bit, little-endian, data-type-policy=OVERRIDE, i-signal-type=PRIMITIVE, init-value=0, base-type=BT_KL_ZZ_Tag, compu {0=Cx0_Init (CM_KL_ZZ_Tag_Cx0_Init), phys=raw for raw 1..31; unit Unit_Day}, range phys 1..31 Unit_Day, raw 0..31, unit=Unit_Day, transfer-property=TRIGGERED-ON-CHANGE-WITHOUT-REPETITION  # Zielzeittimeranzeige im Display der Funkfernbedienung (Datum, Tag); Initwert ist der zuletzt gültige Wert
          signal KL_Betriebsmodus_FH_XIX_Klima_06_XIX_E3V_EVCANFD: start 29, 3 bit, little-endian, data-type-policy=OVERRIDE, i-signal-type=PRIMITIVE, init-value=0, base-type=BT_KL_Betriebsmodus_FH, compu {0=Cx0_undefined_init (CM_KL_Betriebsmodus_FH_Cx0_undefined_init) (undefined__init), 1=Cx1_Klemme15 (CM_KL_Betriebsmodus_FH_Cx1_Klemme15), 2=Cx2_Standheizung (CM_KL_Betriebsmodus_FH_Cx2_Standheizung), 3=Cx3_Restwaerme (CM_KL_Betriebsmodus_FH_Cx3_Restwaerme), 4=Cx4_Nachlauf (CM_KL_Betriebsmodus_FH_Cx4_Nachlauf), 5=Cx5_Standlueften (CM_KL_Betriebsmodus_FH_Cx5_Standlueften), 6=Cx6_Betriebsart_X (CM_KL_Betriebsmodus_FH_Cx6_Betriebsart_X), 7=Cx7_Betriebsart_Y (CM_KL_Betriebsmodus_FH_Cx7_Betriebsart_Y)}, range raw 0..7, transfer-property=TRIGGERED-ON-CHANGE-WITHOUT-REPETITION  # Synchronisation des Betriebsmodus zwischen Front und Fond
          signal KL_Stopp_Wiederstart_Anz_01_XIX_Klima_06_XIX_E3V_EVCANFD: start 32, 1 bit, little-endian, data-type-policy=OVERRIDE, i-signal-type=PRIMITIVE, init-value=0, base-type=BT_KL_Stopp_Wiederstart_Anz_01, compu {0=Cx0_keine_Anzeige (CM_KL_Stopp_Wiederstart_Anz_01_Cx0_keine_Anzeige), 1=Cx1_Geblaese (CM_KL_Stopp_Wiederstart_Anz_01_Cx1_Geblaese)}, range raw 0..1, transfer-property=TRIGGERED-ON-CHANGE-WITHOUT-REPETITION  # Dieses Signal gibt die detaillierte Begründung für eine Stoppverbot-/Wiederstartanfrage der Klima-SG an.
          signal KL_Stopp_Wiederstart_Anz_02_XIX_Klima_06_XIX_E3V_EVCANFD: start 33, 1 bit, little-endian, data-type-policy=OVERRIDE, i-signal-type=PRIMITIVE, init-value=0, base-type=BT_KL_Stopp_Wiederstart_Anz_02, compu {0=Cx0_keine_Anzeige (CM_KL_Stopp_Wiederstart_Anz_02_Cx0_keine_Anzeige), 1=Cx1_Differenz_Soll_Ausblas_zu_Ist_Ausblastemperatur (CM_KL_Stopp_Wiederstart_Anz_02_Cx1_Differenz_Soll_Ausblas_zu_Ist_Ausblastemperatur)}, range raw 0..1, transfer-property=TRIGGERED-ON-CHANGE-WITHOUT-REPETITION  # Dieses Signal gibt die detaillierte Begründung für eine Stoppverbot-/Wiederstartanfrage der Klima-SG an.
          signal KL_Stopp_Wiederstart_Anz_03_XIX_Klima_06_XIX_E3V_EVCANFD: start 34, 1 bit, little-endian, data-type-policy=OVERRIDE, i-signal-type=PRIMITIVE, init-value=0, base-type=BT_KL_Stopp_Wiederstart_Anz_03, compu {0=Cx0_keine_Anzeige (CM_KL_Stopp_Wiederstart_Anz_03_Cx0_keine_Anzeige), 1=Cx1_Beschlagsgefahr (CM_KL_Stopp_Wiederstart_Anz_03_Cx1_Beschlagsgefahr)}, range raw 0..1, transfer-property=TRIGGERED-ON-CHANGE-WITHOUT-REPETITION  # Dieses Signal gibt die detaillierte Begründung für eine Stoppverbot-/Wiederstartanfrage der Klima-SG an.
          signal KL_Stopp_Wiederstart_Anz_04_XIX_Klima_06_XIX_E3V_EVCANFD: start 35, 1 bit, little-endian, data-type-policy=OVERRIDE, i-signal-type=PRIMITIVE, init-value=0, base-type=BT_KL_Stopp_Wiederstart_Anz_04, compu {0=Cx0_keine_Anzeige (CM_KL_Stopp_Wiederstart_Anz_04_Cx0_keine_Anzeige), 1=Cx1_Differenz_Soll_Innentemperatur_zu_Ist_Innenraumtemperatur (CM_KL_Stopp_Wiederstart_Anz_04_Cx1_Differenz_Soll_Innentemperatur_zu_Ist_Innenraumtemperatur)}, range raw 0..1, transfer-property=TRIGGERED-ON-CHANGE-WITHOUT-REPETITION  # Dieses Signal gibt die detaillierte Begründung für eine Stoppverbot-/Wiederstartanfrage der Klima-SG an.
          signal KL_Stopp_Wiederstart_Anz_05_XIX_Klima_06_XIX_E3V_EVCANFD: start 36, 1 bit, little-endian, data-type-policy=OVERRIDE, i-signal-type=PRIMITIVE, init-value=0, base-type=BT_KL_Stopp_Wiederstart_Anz_05, compu {0=Cx0_keine_Anzeige (CM_KL_Stopp_Wiederstart_Anz_05_Cx0_keine_Anzeige), 1=Cx1_Komfortfeuchte (CM_KL_Stopp_Wiederstart_Anz_05_Cx1_Komfortfeuchte)}, range raw 0..1, transfer-property=TRIGGERED-ON-CHANGE-WITHOUT-REPETITION  # Dieses Signal gibt die detaillierte Begründung für eine Stoppverbot-/Wiederstartanfrage der Klima-SG an.
          signal KL_Stopp_Wiederstart_Anz_06_XIX_Klima_06_XIX_E3V_EVCANFD: start 37, 1 bit, little-endian, data-type-policy=OVERRIDE, i-signal-type=PRIMITIVE, init-value=0, base-type=BT_KL_Stopp_Wiederstart_Anz_06, compu {0=Cx0_keine_Anzeige (CM_KL_Stopp_Wiederstart_Anz_06_Cx0_keine_Anzeige), 1=Cx1_Aussentemperatur (CM_KL_Stopp_Wiederstart_Anz_06_Cx1_Aussentemperatur)}, range raw 0..1, transfer-property=TRIGGERED-ON-CHANGE-WITHOUT-REPETITION  # Dieses Signal gibt die detaillierte Begründung für eine Stoppverbot-/Wiederstartanfrage der Klima-SG an.
          signal KL_Stopp_Wiederstart_Anz_07_XIX_Klima_06_XIX_E3V_EVCANFD: start 38, 1 bit, little-endian, data-type-policy=OVERRIDE, i-signal-type=PRIMITIVE, init-value=0, base-type=BT_KL_Stopp_Wiederstart_Anz_07, compu {0=Cx0_keine_Anzeige (CM_KL_Stopp_Wiederstart_Anz_07_Cx0_keine_Anzeige), 1=Cx1_Defrost (CM_KL_Stopp_Wiederstart_Anz_07_Cx1_Defrost)}, range raw 0..1, transfer-property=TRIGGERED-ON-CHANGE-WITHOUT-REPETITION  # Dieses Signal gibt die detaillierte Begründung für eine Stoppverbot-/Wiederstartanfrage der Klima-SG an.
          signal KL_Stopp_Wiederstart_Anz_08_XIX_Klima_06_XIX_E3V_EVCANFD: start 39, 1 bit, little-endian, data-type-policy=OVERRIDE, i-signal-type=PRIMITIVE, init-value=0, base-type=BT_KL_Stopp_Wiederstart_Anz_08, compu {0=Cx0_keine_Anzeige (CM_KL_Stopp_Wiederstart_Anz_08_Cx0_keine_Anzeige), 1=Cx1_High_Low (CM_KL_Stopp_Wiederstart_Anz_08_Cx1_High_Low)}, range raw 0..1, transfer-property=TRIGGERED-ON-CHANGE-WITHOUT-REPETITION  # Dieses Signal gibt die detaillierte Begründung für eine Stoppverbot-/Wiederstartanfrage der Klima-SG an.
          signal KL_Stopp_Wiederstart_Anz_09_XIX_Klima_06_XIX_E3V_EVCANFD: start 40, 1 bit, little-endian, data-type-policy=OVERRIDE, i-signal-type=PRIMITIVE, init-value=0, base-type=BT_KL_Stopp_Wiederstart_Anz_09, compu {0=Cx0_keine_Anzeige (CM_KL_Stopp_Wiederstart_Anz_09_Cx0_keine_Anzeige), 1=Cx1_Frontscheibenheizung (CM_KL_Stopp_Wiederstart_Anz_09_Cx1_Frontscheibenheizung)}, range raw 0..1, transfer-property=TRIGGERED-ON-CHANGE-WITHOUT-REPETITION  # Dieses Signal gibt die detaillierte Begründung für eine Stoppverbot-/Wiederstartanfrage der Klima-SG an.
          signal KL_Stopp_Wiederstart_Anz_Std1_XIX_Klima_06_XIX_E3V_EVCANFD: start 41, 1 bit, little-endian, data-type-policy=OVERRIDE, i-signal-type=PRIMITIVE, init-value=0, base-type=BT_KL_Stopp_Wiederstart_Anz_Std1, compu {0=Cx0_keine_Anzeige (CM_KL_Stopp_Wiederstart_Anz_Std1_Cx0_keine_Anzeige), 1=Cx1_maxA_C (CM_KL_Stopp_Wiederstart_Anz_Std1_Cx1_maxA_C) (maxA/C)}, range raw 0..1, transfer-property=TRIGGERED-ON-CHANGE-WITHOUT-REPETITION  # Dieses Signal gibt die detaillierte Begründung für eine Stoppverbot-/Wiederstartanfrage der Klima-SG an.
          signal KL_Stopp_Wiederstart_Anz_Std2_XIX_Klima_06_XIX_E3V_EVCANFD: start 42, 1 bit, little-endian, data-type-policy=OVERRIDE, i-signal-type=PRIMITIVE, init-value=0, base-type=BT_KL_Stopp_Wiederstart_Anz_Std2, compu {0=Cx0_keine_Anzeige (CM_KL_Stopp_Wiederstart_Anz_Std2_Cx0_keine_Anzeige), 1=Cx1_Sitzlueftung (CM_KL_Stopp_Wiederstart_Anz_Std2_Cx1_Sitzlueftung)}, range raw 0..1, transfer-property=TRIGGERED-ON-CHANGE-WITHOUT-REPETITION  # Dieses Signal gibt die detaillierte Begründung für eine Stoppverbot-/Wiederstartanfrage der Klima-SG an.
          signal KL_STH_Betriebsdauer_lang_XIX_Klima_06_XIX_E3V_EVCANFD: start 43, 7 bit, little-endian, data-type-policy=OVERRIDE, i-signal-type=PRIMITIVE, init-value=0, base-type=BT_KL_STH_Betriebsdauer_lang, compu {phys=raw for raw 0..120; unit Unit_Minut}, range phys 0..120 Unit_Minut, raw 0..120, unit=Unit_Minut, transfer-property=TRIGGERED-ON-CHANGE-WITHOUT-REPETITION  # Betriebsdauer STH im Falle eines möglichen 120min Betriebes.
          signal KL_Meldung_Status_XIX_Klima_06_XIX_E3V_EVCANFD: start 50, 4 bit, little-endian, data-type-policy=OVERRIDE, i-signal-type=PRIMITIVE, init-value=0, base-type=BT_KL_Meldung_Status, compu {0=Cx0_keine_notification (CM_KL_Meldung_Status_Cx0_keine_notification), 1=Cx1_Klima_eingeschraenkt (CM_KL_Meldung_Status_Cx1_Klima_eingeschraenkt), 2=Cx2_Klima_Warnung (CM_KL_Meldung_Status_Cx2_Klima_Warnung), 3=Cx3_Service_Klima (CM_KL_Meldung_Status_Cx3_Service_Klima), 4=Cx4_Fahrzeug_Lueften_Gelb (CM_KL_Meldung_Status_Cx4_Fahrzeug_Lueften_Gelb), 5=Cx5_Fahrzeug_Lueften_Rot (CM_KL_Meldung_Status_Cx5_Fahrzeug_Lueften_Rot), 6=Cx6_Fahrzeug_Lueften_3 (CM_KL_Meldung_Status_Cx6_Fahrzeug_Lueften_3), 7=Cx7_Klima_Abwurf (CM_KL_Meldung_Status_Cx7_Klima_Abwurf), 8=Cx8_reserve_1 (CM_KL_Meldung_Status_Cx8_reserve_1), 9=Cx9_reserve_2 (CM_KL_Meldung_Status_Cx9_reserve_2)}, range raw 0..9, transfer-property=TRIGGERED-ON-CHANGE-WITHOUT-REPETITION  # Klima gibt den Status der Fahrermeldungen aus.
          signal KL_ErwVK_Status_XIX_Klima_06_XIX_E3V_EVCANFD: start 54, 4 bit, little-endian, data-type-policy=OVERRIDE, i-signal-type=PRIMITIVE, init-value=0, base-type=BT_KL_ErwVK_Status, compu {0=Cx0_nicht_angefordert (CM_KL_ErwVK_Status_Cx0_nicht_angefordert), 1=Cx1_Fahrerzone_aktiv (CM_KL_ErwVK_Status_Cx1_Fahrerzone_aktiv), 2=Cx2_Beifahrerzone_aktiv (CM_KL_ErwVK_Status_Cx2_Beifahrerzone_aktiv), 3=Cx3_Heckzone_links_aktiv (CM_KL_ErwVK_Status_Cx3_Heckzone_links_aktiv), 4=Cx4_Heckzone_recht_aktiv (CM_KL_ErwVK_Status_Cx4_Heckzone_recht_aktiv), 5=Cx5_Scheibenheizung_aktiv (CM_KL_ErwVK_Status_Cx5_Scheibenheizung_aktiv)}, range raw 0..5, transfer-property=TRIGGERED-ON-CHANGE-WITHOUT-REPETITION  # Erweiterte Voko angefordert für Fahrerzone_aktiv Alle Zonen_aktiv Beifahrerzone_aktiv Heckzone_aktiv Scheibenheizung_aktiv
          signal KL_Hinweis_Kuehlmodus_XIX_Klima_06_XIX_E3V_EVCANFD: start 58, 2 bit, little-endian, data-type-policy=OVERRIDE, i-signal-type=PRIMITIVE, init-value=0, base-type=BT_KL_Hinweis_Kuehlmodus, compu {0=Cx0_aus (CM_KL_Hinweis_Kuehlmodus_Cx0_aus), 1=Cx1_Stufe1 (CM_KL_Hinweis_Kuehlmodus_Cx1_Stufe1), 2=Cx2_Stufe2 (CM_KL_Hinweis_Kuehlmodus_Cx2_Stufe2), 3=Cx3_Stufe3 (CM_KL_Hinweis_Kuehlmodus_Cx3_Stufe3)}, range raw 0..3, transfer-property=TRIGGERED-ON-CHANGE-WITHOUT-REPETITION  # Signal generiert einen Kundenhinweis, ob eine normale Klimatisierung umgesetzt werden kann, oder ein Sondermodus aktiv ist
          signal KL_ErwVK_Beifahrerzone_XIX_Klima_06_XIX_E3V_EVCANFD: start 60, 1 bit, little-endian, data-type-policy=OVERRIDE, i-signal-type=PRIMITIVE, init-value=0, base-type=BT_KL_ErwVK_Beifahrerzone, compu {0=Cx0_nicht_aktiv (CM_KL_ErwVK_Beifahrerzone_Cx0_nicht_aktiv), 1=Cx1_Beifahrerzone_aktiv (CM_KL_ErwVK_Beifahrerzone_Cx1_Beifahrerzone_aktiv)}, range raw 0..1, transfer-property=TRIGGERED-ON-CHANGE-WITHOUT-REPETITION  # Erweiterte Voko Beifahrerseite
          signal KL_ErwVK_Fahrerzone_XIX_Klima_06_XIX_E3V_EVCANFD: start 61, 1 bit, little-endian, data-type-policy=OVERRIDE, i-signal-type=PRIMITIVE, init-value=0, base-type=BT_KL_ErwVK_Fahrerzone, compu {0=Cx0_nicht_aktiv (CM_KL_ErwVK_Fahrerzone_Cx0_nicht_aktiv), 1=Cx1_Fahrerzone_aktiv (CM_KL_ErwVK_Fahrerzone_Cx1_Fahrerzone_aktiv)}, range raw 0..1, transfer-property=TRIGGERED-ON-CHANGE-WITHOUT-REPETITION  # Erweiterte Voko Fahrerseite
          signal KL_ErwVK_Heckzone_links_XIX_Klima_06_XIX_E3V_EVCANFD: start 62, 1 bit, little-endian, data-type-policy=OVERRIDE, i-signal-type=PRIMITIVE, init-value=0, base-type=BT_KL_ErwVK_Heckzone_links, compu {0=Cx0_nicht_aktiv (CM_KL_ErwVK_Heckzone_links_Cx0_nicht_aktiv), 1=Cx1_Heckzone_links_aktiv (CM_KL_ErwVK_Heckzone_links_Cx1_Heckzone_links_aktiv)}, range raw 0..1, transfer-property=TRIGGERED-ON-CHANGE-WITHOUT-REPETITION  # Erweiterte Voko Heckzone links
          signal Kl_ErwVK_Heckzone_rechts_XIX_Klima_06_XIX_E3V_EVCANFD: start 63, 1 bit, little-endian, data-type-policy=OVERRIDE, i-signal-type=PRIMITIVE, init-value=0, base-type=BT_Kl_ErwVK_Heckzone_rechts, compu {0=Cx0_nicht_aktiv (CM_Kl_ErwVK_Heckzone_rechts_Cx0_nicht_aktiv), 1=Cx1_Heckzone_rechts_aktiv (CM_Kl_ErwVK_Heckzone_rechts_Cx1_Heckzone_rechts_aktiv)}, range raw 0..1, transfer-property=TRIGGERED-ON-CHANGE-WITHOUT-REPETITION  # Erweiterte Voko Heckzone rechts.
      frame Klima_11_XIX_E3V_EVCANFD: id 0x3B5, from Klima, frame-length=8, can-addressing-mode=STANDARD, can-frame-rx-behavior=CAN-FD, can-frame-tx-behavior=CAN-FD
        pdu Klima_11_XIX_E3V_EVCANFD: length=8, transmission-mode-true-timing=cyclic-timing={time-offset=0.0, time-period=0.1}, unused-bit-pattern=0  # ab MQB 7.4
          signal KL_Drehz_Anh_XIX_Klima_11_XIX_E3V_EVCANFD: start 0, 1 bit, little-endian, data-type-policy=OVERRIDE, i-signal-type=PRIMITIVE, init-value=0, base-type=BT_KL_Drehz_Anh, compu {0=Cx0_keine_Anhebung (CM_KL_Drehz_Anh_Cx0_keine_Anhebung), 1=Cx1_Drehzahlanhebung_vom_Motor_angefordert (CM_KL_Drehz_Anh_Cx1_Drehzahlanhebung_vom_Motor_angefordert)}, range raw 0..1, transfer-property=PENDING  # Drehzahlanhebung vom Motor angefordert
          signal KL_Vorwarn_Komp_ein_XIX_Klima_11_XIX_E3V_EVCANFD: start 1, 1 bit, little-endian, data-type-policy=OVERRIDE, i-signal-type=PRIMITIVE, init-value=0, base-type=BT_KL_Vorwarn_Komp_ein, compu {0=Cx0_Init (CM_KL_Vorwarn_Komp_ein_Cx0_Init), 1=Cx1_Vorwarnung_Kompressor_ein (CM_KL_Vorwarn_Komp_ein_Cx1_Vorwarnung_Kompressor_ein)}, range raw 0..1, transfer-property=PENDING  # Vorwarnung Kompressor ein; 140ms vorher; Information für Motor zum Aufbau Momentenreserve
          signal KL_AC_Schalter_XIX_Klima_11_XIX_E3V_EVCANFD: start 2, 1 bit, little-endian, data-type-policy=OVERRIDE, i-signal-type=PRIMITIVE, init-value=0, base-type=BT_KL_AC_Schalter, compu {0=Cx0_aus (CM_KL_AC_Schalter_Cx0_aus), 1=Cx1_ein (CM_KL_AC_Schalter_Cx1_ein)}, range raw 0..1, transfer-property=PENDING  # AC Schalter
          signal KL_Komp_Moment_alt_XIX_Klima_11_XIX_E3V_EVCANFD: start 3, 1 bit, little-endian, data-type-policy=OVERRIDE, i-signal-type=PRIMITIVE, init-value=0, base-type=BT_KL_Komp_Moment_alt, compu {1=Cx1_veraltet_bzw_Ermittlung_des_Moments_nicht_moeglich_zB_keine_Drehzahl_kein_Kaeltemitteldruck (CM_KL_Komp_Moment_alt_Cx1_veraltet_bzw_Ermittlung_des_Moments_nicht_moeglich_zB_keine_Drehzahl_kein_Kaeltemitteldruck) (veraltet_bzw_Ermittlung_des_Moments_nicht_moeglich__zB_keine_Drehzahl_kein_Kaeltemitteldruck)}, range raw 1, transfer-property=PENDING
          signal KL_Vorwarn_Zuheizer_ein_XIX_Klima_11_XIX_E3V_EVCANFD: start 6, 1 bit, little-endian, data-type-policy=OVERRIDE, i-signal-type=PRIMITIVE, init-value=0, base-type=BT_KL_Vorwarn_Zuheizer_ein, compu {0=Cx0_keine_Vorwarnung (CM_KL_Vorwarn_Zuheizer_ein_Cx0_keine_Vorwarnung), 1=Cx1_Vorwarnung_Zuheizer_ein (CM_KL_Vorwarn_Zuheizer_ein_Cx1_Vorwarnung_Zuheizer_ein)}, range raw 0..1, transfer-property=PENDING  # Vorwarnung Zuheizerbetrieb
          signal KL_Zustand_XIX_Klima_11_XIX_E3V_EVCANFD: start 7, 1 bit, little-endian, data-type-policy=OVERRIDE, i-signal-type=PRIMITIVE, init-value=0, base-type=BT_KL_Zustand, compu {0=Cx0_Aus (CM_KL_Zustand_Cx0_Aus), 1=Cx1_Ein (CM_KL_Zustand_Cx1_Ein)}, range raw 0..1, transfer-property=PENDING  # Beschreibt den Zustand des Klima-/Heizungsbedienteils. (OFF-Mode Bedienteil) PAG (MLB): Beschreibt den Zustand des Kompressors
          signal KL_Kompressorkupplung_linear_XIX_Klima_11_XIX_E3V_EVCANFD: start 8, 8 bit, little-endian, data-type-policy=OVERRIDE, i-signal-type=PRIMITIVE, init-value=254, base-type=BT_KL_Kompressorkupplung_linear, compu {phys=raw*20 for raw 0..200, 253=Cxfd_volle_Ansteuerung (CM_KL_Kompressorkupplung_linear_Cxfd_volle_Ansteuerung), 254=Cxfe_Init_nicht_bedient (CM_KL_Kompressorkupplung_linear_Cxfe_Init_nicht_bedient) (Init__nicht_bedient); unit Unit_MilliAmper}, range phys 0..4000 Unit_MilliAmper, raw 0..254, unit=Unit_MilliAmper, transfer-property=PENDING  # Sollwert zur Ansteuerung der Kompressorkupplung
          signal KL_Charisma_FahrPr_XIX_Klima_11_XIX_E3V_EVCANFD: start 16, 4 bit, little-endian, data-type-policy=OVERRIDE, i-signal-type=PRIMITIVE, init-value=0, base-type=BT_KL_Charisma_FahrPr, compu {0=Cx0_keine_Funktion (CM_KL_Charisma_FahrPr_Cx0_keine_Funktion), 1=Cx1_Programm_1 (CM_KL_Charisma_FahrPr_Cx1_Programm_1), 2=Cx2_Programm_2 (CM_KL_Charisma_FahrPr_Cx2_Programm_2), 3=Cx3_Programm_3 (CM_KL_Charisma_FahrPr_Cx3_Programm_3), 4=Cx4_Programm_4 (CM_KL_Charisma_FahrPr_Cx4_Programm_4), 5=Cx5_Programm_5 (CM_KL_Charisma_FahrPr_Cx5_Programm_5), 6=Cx6_Programm_6 (CM_KL_Charisma_FahrPr_Cx6_Programm_6), 7=Cx7_Programm_7 (CM_KL_Charisma_FahrPr_Cx7_Programm_7), 8=Cx8_Programm_8 (CM_KL_Charisma_FahrPr_Cx8_Programm_8), 9=Cx9_Programm_9 (CM_KL_Charisma_FahrPr_Cx9_Programm_9), 10=Cxa_Programm_10 (CM_KL_Charisma_FahrPr_Cxa_Programm_10), 11=Cxb_Programm_11 (CM_KL_Charisma_FahrPr_Cxb_Programm_11), 12=Cxc_Programm_12 (CM_KL_Charisma_FahrPr_Cxc_Programm_12), 13=Cxd_Programm_13 (CM_KL_Charisma_FahrPr_Cxd_Programm_13), 14=Cxe_Programm_14 (CM_KL_Charisma_FahrPr_Cxe_Programm_14), 15=Cxf_Programm_15 (CM_KL_Charisma_FahrPr_Cxf_Programm_15)}, range raw 0..15, transfer-property=PENDING  # MLBevo: Aktuelles Fahrprogramm des Charisma-Teilnehmers (siehe Systemlastenheft Drive Select) MQB: Istwert der Kennlinie (siehe Systemlastenheft MQB FPA)
          signal KL_Charisma_Status_XIX_Klima_11_XIX_E3V_EVCANFD: start 20, 2 bit, little-endian, data-type-policy=OVERRIDE, i-signal-type=PRIMITIVE, init-value=0, base-type=BT_KL_Charisma_Status, compu {0=Cx0_Init (CM_KL_Charisma_Status_Cx0_Init), 1=Cx1_verfuegbar (CM_KL_Charisma_Status_Cx1_verfuegbar), 2=Cx2_nicht_verfuegbar (CM_KL_Charisma_Status_Cx2_nicht_verfuegbar), 3=Cx3_asynchron_durch_Fahrerwunsch (CM_KL_Charisma_Status_Cx3_asynchron_durch_Fahrerwunsch)}, range raw 0..3, transfer-property=PENDING  # Charisma Systemstatus des Charisma-Teilnehmers Wert 0x3 ist nur für Fahrzeuge ab MQB relevant
          signal KL_nachtr_Stopp_Anf_XIX_Klima_11_XIX_E3V_EVCANFD: start 22, 1 bit, little-endian, data-type-policy=OVERRIDE, i-signal-type=PRIMITIVE, init-value=0, base-type=BT_KL_nachtr_Stopp_Anf, compu {0=Cx0_nicht_angefordert (CM_KL_nachtr_Stopp_Anf_Cx0_nicht_angefordert), 1=Cx1_angefordert (CM_KL_nachtr_Stopp_Anf_Cx1_angefordert)}, range raw 0..1, transfer-property=PENDING  # Dieses Signal dient dem Motor als Trigger, dass ein nachträglicher Motorstopp eingeleitet werden kann, wenn es die Bedingungen des StSt Koordinators dies zulassen.
          signal KL_T_Charge_XIX_Klima_11_XIX_E3V_EVCANFD: start 23, 1 bit, little-endian, data-type-policy=OVERRIDE, i-signal-type=PRIMITIVE, init-value=0, base-type=BT_KL_T_Charge, compu {0=Cx0_Taster_nicht_betaetigt (CM_KL_T_Charge_Cx0_Taster_nicht_betaetigt), 1=Cx1_Taster_betaetigt (CM_KL_T_Charge_Cx1_Taster_betaetigt)}, range raw 0..1, transfer-property=PENDING  # Signal für Tastenbetätigung Charge-Taste (SOC Increasing)
          signal KL_Last_Kompr_XIX_Klima_11_XIX_E3V_EVCANFD: start 24, 8 bit, little-endian, data-type-policy=OVERRIDE, i-signal-type=PRIMITIVE, init-value=0, base-type=BT_KL_Last_Kompr, invalid-value=Invalid_KL_Last_Kompr_XIX_Klima_11_XIX_E3V_EVCANFD:255, compu {phys=raw*0.25 for raw 0..254, 255=Cxff_Fehler (CM_KL_Last_Kompr_Cxff_Fehler); unit Unit_NewtoMeter}, range phys 0..63.5 Unit_NewtoMeter, raw 0..255, unit=Unit_NewtoMeter, transfer-property=PENDING  # Aktuelles Verlustmoment der Klimaanlage bezogen auf die Kurbelwelle. Wird der Klimakompressor nicht angesteuert, ist das Schleppmoment bezogen auf die Kurbelwelle zu senden.
          signal KL_Spannungs_Anf_XIX_Klima_11_XIX_E3V_EVCANFD: start 32, 2 bit, little-endian, data-type-policy=OVERRIDE, i-signal-type=PRIMITIVE, init-value=0, base-type=BT_KL_Spannungs_Anf, compu {0=Cx0_keine_Anforderung (CM_KL_Spannungs_Anf_Cx0_keine_Anforderung), 1=Cx1_Anforderung_Stufe_1 (CM_KL_Spannungs_Anf_Cx1_Anforderung_Stufe_1), 2=Cx2_Anforderung_Stufe_2 (CM_KL_Spannungs_Anf_Cx2_Anforderung_Stufe_2), 3=Cx3_Anforderung_Stufe_3 (CM_KL_Spannungs_Anf_Cx3_Anforderung_Stufe_3)}, range raw 0..3, transfer-property=PENDING  # Forderung des Klima-SG's zur Spannungsanhebung.
          signal KL_Thermomanagement_XIX_Klima_11_XIX_E3V_EVCANFD: start 34, 2 bit, little-endian, data-type-policy=OVERRIDE, i-signal-type=PRIMITIVE, init-value=0, base-type=BT_KL_Thermomanagement, compu {0=Cx0_keine_Freigabe_TMM_max_Heizbedarf (CM_KL_Thermomanagement_Cx0_keine_Freigabe_TMM_max_Heizbedarf) (keine_Freigabe_TMM__max_Heizbedarf), 1=Cx1_kleine_Freigabe_TMM (CM_KL_Thermomanagement_Cx1_kleine_Freigabe_TMM), 2=Cx2_mittlere_Freigabe_TMM (CM_KL_Thermomanagement_Cx2_mittlere_Freigabe_TMM), 3=Cx3_volle_Freigabe_TMM_kein_Heizbedarf (CM_KL_Thermomanagement_Cx3_volle_Freigabe_TMM_kein_Heizbedarf) (volle_Freigabe_TMM__kein_Heizbedarf)}, range raw 0..3, transfer-property=PENDING  # Stufen des Thermomanagements; Bei Klemme 15 AUS und erkannten Timeout zum Klimabedienteil (z.B. Klimabedienteil während des Motorsteuergeräte-Kommunikations-Nachlaufs bereits im NM-Zustand ¿Bus Sleep¿) erfolgt keine Ansteuerung der Wasserpumpe durch die ITM Funktion. In dem konkreten Fall wird der definierte Initwert von der ITM-Funktion nicht als Ersatzwert verwendet. Parallel ist eine Ansteuerung zur Restwärmenutzung außerhalb der ITM-Funktion möglich.
          signal KL_StartStopp_Info_XIX_Klima_11_XIX_E3V_EVCANFD: start 36, 2 bit, little-endian, data-type-policy=OVERRIDE, i-signal-type=PRIMITIVE, init-value=0, base-type=BT_KL_StartStopp_Info, compu {0=Cx0_Motorlauf_nicht_notwendig_Stoppfreigabe (CM_KL_StartStopp_Info_Cx0_Motorlauf_nicht_notwendig_Stoppfreigabe) (Motorlauf_nicht_notwendig_(Stoppfreigabe)), 1=Cx1_Motoranlauf_nicht_zwingend_notwendig_Stoppverbot_keine_Startanforderung (CM_KL_StartStopp_Info_Cx1_Motoranlauf_nicht_zwingend_notwendig_Stoppverbot_keine_Startanforderung) (Motoranlauf_nicht_zwingend_notwendig_(Stoppverbot,keine_Startanforderung)), 2=Cx2_Motoranlauf_zwingend_notwendig_Startanforderung (CM_KL_StartStopp_Info_Cx2_Motoranlauf_zwingend_notwendig_Startanforderung) (Motoranlauf_zwingend_notwendig_(Startanforderung)), 3=Cx3_Systemfehler (CM_KL_StartStopp_Info_Cx3_Systemfehler)}, range raw 0..3, transfer-property=PENDING  # Stopp-Freigabe und Start-Anforderung an den Start-Stopp-Koordinator
          signal KL_Freilauf_Info_XIX_Klima_11_XIX_E3V_EVCANFD: start 38, 2 bit, little-endian, data-type-policy=OVERRIDE, i-signal-type=PRIMITIVE, init-value=0, base-type=BT_KL_Freilauf_Info, compu {0=Cx0_Freilauf_freigegeben (CM_KL_Freilauf_Info_Cx0_Freilauf_freigegeben), 1=Cx1_Uebergang_in_Freilauf_unzulaessig (CM_KL_Freilauf_Info_Cx1_Uebergang_in_Freilauf_unzulaessig), 2=Cx2_Freilauf_nicht_freigegeben_Abbruch (CM_KL_Freilauf_Info_Cx2_Freilauf_nicht_freigegeben_Abbruch), 3=Cx3_Freilauf_Anforderung (CM_KL_Freilauf_Info_Cx3_Freilauf_Anforderung)}, range raw 0..3, transfer-property=PENDING  # Freilauf Informationssignal von Klima zum Freilaufkoordinator. Klima kann über dieses Signal den Freilauf freigeben, verhindern bzw. explizit anfordern.
          signal KL_Anf_KL_XIX_Klima_11_XIX_E3V_EVCANFD: start 40, 8 bit, little-endian, data-type-policy=OVERRIDE, i-signal-type=PRIMITIVE, init-value=0, base-type=BT_KL_Anf_KL, invalid-value=Invalid_KL_Anf_KL_XIX_Klima_11_XIX_E3V_EVCANFD:255, compu {phys=raw*0.4 for raw 0..254, 255=Cxff_Fehler (CM_KL_Anf_KL_Cxff_Fehler); unit Unit_PerCent}, range phys 0..101.6 Unit_PerCent, raw 0..255, unit=Unit_PerCent, transfer-property=PENDING  # Anforderung Kühlerlüfter der Klimaanlage in Prozent
          signal KL_el_Zuheizer_Stufe_XIX_Klima_11_XIX_E3V_EVCANFD: start 48, 3 bit, little-endian, data-type-policy=OVERRIDE, i-signal-type=PRIMITIVE, init-value=0, base-type=BT_KL_el_Zuheizer_Stufe, compu {0=Cx0_Aus (CM_KL_el_Zuheizer_Stufe_Cx0_Aus), 1=Cx1_Stufe_1 (CM_KL_el_Zuheizer_Stufe_Cx1_Stufe_1), 2=Cx2_Stufe_2 (CM_KL_el_Zuheizer_Stufe_Cx2_Stufe_2), 3=Cx3_Stufe_3 (CM_KL_el_Zuheizer_Stufe_Cx3_Stufe_3)}, range raw 0..3, transfer-property=PENDING  # Vorgabe für Motorsteuergeraet PTC-Stufe; im MLB-B8 und MQB nur Stufe 0...3
          signal KL_Ausstattung_Klima_XIX_Klima_11_XIX_E3V_EVCANFD: start 51, 3 bit, little-endian, data-type-policy=OVERRIDE, i-signal-type=PRIMITIVE, init-value=0, base-type=BT_KL_Ausstattung_Klima, compu {0=Cx0_Heizung_elektrisch (CM_KL_Ausstattung_Klima_Cx0_Heizung_elektrisch), 1=Cx1_Klimamanuell_elektrisch (CM_KL_Ausstattung_Klima_Cx1_Klimamanuell_elektrisch), 2=Cx2_Climatic_1_Zone (CM_KL_Ausstattung_Klima_Cx2_Climatic_1_Zone) (Climatic__1_Zone), 3=Cx3_Climatronic_1_Zone (CM_KL_Ausstattung_Klima_Cx3_Climatronic_1_Zone) (Climatronic__1_Zone), 4=Cx4_Climatronic_2_Zonen (CM_KL_Ausstattung_Klima_Cx4_Climatronic_2_Zonen) (Climatronic__2_Zonen), 5=Cx5_Climatronic_3_Zonen (CM_KL_Ausstattung_Klima_Cx5_Climatronic_3_Zonen) (Climatronic__3_Zonen), 6=Cx6_Climatronic_4_Zonen (CM_KL_Ausstattung_Klima_Cx6_Climatronic_4_Zonen) (Climatronic__4_Zonen), 7=Cx7_reserviert (CM_KL_Ausstattung_Klima_Cx7_reserviert)}, range raw 0..7, transfer-property=PENDING  # Austtattungsart der Klimabedienung
          signal KL_Variante_Standheizung_XIX_Klima_11_XIX_E3V_EVCANFD: start 54, 2 bit, little-endian, data-type-policy=OVERRIDE, i-signal-type=PRIMITIVE, init-value=0, base-type=BT_KL_Variante_Standheizung, compu {0=Cx0_Wasserstandheizung_60_min_Laufzeit (CM_KL_Variante_Standheizung_Cx0_Wasserstandheizung_60_min_Laufzeit), 1=Cx1_Luftstandheizung_120_min_Laufzeit (CM_KL_Variante_Standheizung_Cx1_Luftstandheizung_120_min_Laufzeit), 2=Cx2_Wasserstandheizung_120_min_Laufzeit (CM_KL_Variante_Standheizung_Cx2_Wasserstandheizung_120_min_Laufzeit), 3=Cx3_Wasser_und_Luftstandheizung_120_min_Laufzeit (CM_KL_Variante_Standheizung_Cx3_Wasser_und_Luftstandheizung_120_min_Laufzeit)}, range raw 0..3, transfer-property=PENDING  # Identifikation der Variante der Standheizungen zur Berechnung der energetischen Zielzeit
          signal KL_AirCleaner_aktiv_XIX_Klima_11_XIX_E3V_EVCANFD: start 56, 1 bit, little-endian, data-type-policy=OVERRIDE, i-signal-type=PRIMITIVE, init-value=0, base-type=BT_KL_AirCleaner_aktiv, compu {0=Cx0_AirCleaner_nicht_aktiv (CM_KL_AirCleaner_aktiv_Cx0_AirCleaner_nicht_aktiv), 1=Cx1_AirCleaner_aktiv (CM_KL_AirCleaner_aktiv_Cx1_AirCleaner_aktiv)}, range raw 0..1, transfer-property=PENDING  # Status des Zustands der AirCare Funktion (Umluft) im Fahrzeug
          signal KL_Anf_KV_XIX_Klima_11_XIX_E3V_EVCANFD: start 57, 7 bit, little-endian, data-type-policy=OVERRIDE, i-signal-type=PRIMITIVE, init-value=126, base-type=BT_KL_Anf_KV, compu {phys=raw for raw 0..100, 126=Cx7e_Init (CM_KL_Anf_KV_Cx7e_Init); unit Unit_PerCent}, range phys 0..100 Unit_PerCent, raw 0..126, unit=Unit_PerCent, transfer-property=PENDING  # Anforderung des Kühlerrollos in %
      frame Klima_12_XIX_E3V_EVCANFD: id 0x668, from Klima, frame-length=8, can-addressing-mode=STANDARD, can-frame-rx-behavior=CAN-FD, can-frame-tx-behavior=CAN-FD
        pdu Klima_12_XIX_E3V_EVCANFD: length=8, minimum-delay=0.05, transmission-mode-true-timing={cyclic-timing={time-offset=0.0, time-period=0.2}, event-controlled-timing={number-of-repetitions=5, repetition-period=0.1}}, unused-bit-pattern=0  # ab MQB IS-4
          signal KL_LRH_Taster_XIX_Klima_12_XIX_E3V_EVCANFD: start 0, 1 bit, little-endian, data-type-policy=OVERRIDE, i-signal-type=PRIMITIVE, init-value=0, base-type=BT_KL_LRH_Taster, compu {0=Cx0_nicht_betaetigt (CM_KL_LRH_Taster_Cx0_nicht_betaetigt), 1=Cx1_betaetigt (CM_KL_LRH_Taster_Cx1_betaetigt)}, range raw 0..1, transfer-property=TRIGGERED-ON-CHANGE  # Tasterbetätigung Lenkradheizung
          signal KL_LRH_Stufe_XIX_Klima_12_XIX_E3V_EVCANFD: start 1, 2 bit, little-endian, data-type-policy=OVERRIDE, i-signal-type=PRIMITIVE, init-value=1, base-type=BT_KL_LRH_Stufe, compu {0=Cx0_Stufe_niedrig (CM_KL_LRH_Stufe_Cx0_Stufe_niedrig), 1=Cx1_Stufe_mittel (CM_KL_LRH_Stufe_Cx1_Stufe_mittel), 2=Cx2_Stufe_hoch (CM_KL_LRH_Stufe_Cx2_Stufe_hoch), 3=Cx3_AUS (CM_KL_LRH_Stufe_Cx3_AUS)}, range raw 0..3, transfer-property=TRIGGERED-ON-CHANGE-WITHOUT-REPETITION  # Eingestellte Temperaturstufe der Lenkradheizung
          signal HSH_Taster_XIX_Klima_12_XIX_E3V_EVCANFD: start 3, 2 bit, little-endian, data-type-policy=OVERRIDE, i-signal-type=PRIMITIVE, init-value=0, base-type=BT_HSH_Taster, compu {0=Cx0_nicht_betaetigt (CM_HSH_Taster_Cx0_nicht_betaetigt), 1=Cx1_short_push (CM_HSH_Taster_Cx1_short_push), 2=Cx2_long_push (CM_HSH_Taster_Cx2_long_push), 3=Cx3_tbd (CM_HSH_Taster_Cx3_tbd)}, range raw 0..3, transfer-property=TRIGGERED-ON-CHANGE  # An-/Abforderung Heckscheibenheizung über spezielles Tastersignal
          signal FSH_Taster_XIX_Klima_12_XIX_E3V_EVCANFD: start 5, 1 bit, little-endian, data-type-policy=OVERRIDE, i-signal-type=PRIMITIVE, init-value=0, base-type=BT_FSH_Taster, compu {0=Cx0_nicht_betaetigt (CM_FSH_Taster_Cx0_nicht_betaetigt), 1=Cx1_betaetigt (CM_FSH_Taster_Cx1_betaetigt)}, range raw 0..1, transfer-property=TRIGGERED-ON-CHANGE  # Tasterbetätigung Frontscheibenheizung
          signal KL_Zuheizer_Freigabe_XIX_Klima_12_XIX_E3V_EVCANFD: start 6, 1 bit, little-endian, data-type-policy=OVERRIDE, i-signal-type=PRIMITIVE, init-value=0, base-type=BT_KL_Zuheizer_Freigabe, compu {0=Cx0_keine_Freigabe_Zuheizer (CM_KL_Zuheizer_Freigabe_Cx0_keine_Freigabe_Zuheizer), 1=Cx1_Zuheizerfreigabe (CM_KL_Zuheizer_Freigabe_Cx1_Zuheizerfreigabe)}, range raw 0..1, transfer-property=TRIGGERED-ON-CHANGE-WITHOUT-REPETITION  # Freigabe Zuheizer
          signal KL_Beschlagsgefahr_XIX_Klima_12_XIX_E3V_EVCANFD: start 7, 1 bit, little-endian, data-type-policy=OVERRIDE, i-signal-type=PRIMITIVE, init-value=0, base-type=BT_KL_Beschlagsgefahr, compu {0=Cx0_keine_Beschlagsgefahr (CM_KL_Beschlagsgefahr_Cx0_keine_Beschlagsgefahr), 1=Cx1_Beschlagsgefahr (CM_KL_Beschlagsgefahr_Cx1_Beschlagsgefahr)}, range raw 0..1, transfer-property=TRIGGERED-ON-CHANGE-WITHOUT-REPETITION  # Beschlagsgefahr auf der Frontscheibe im Bereich des Spiegelfusses. Dient zur präventiven Ansteuerung der Kamera-Scheibenheizung, um Kamera-Blindheit zu vermeiden PHEV: volle Leistungsfreigabe HV Heizer und HV EKK bei Scheibenbeschlag
          signal KL_SIH_Soll_li_XIX_Klima_12_XIX_E3V_EVCANFD: start 8, 3 bit, little-endian, data-type-policy=OVERRIDE, i-signal-type=PRIMITIVE, init-value=0, base-type=BT_KL_SIH_Soll_li, compu {phys=raw for raw 0..6}, range phys 0..6, raw 0..6, transfer-property=TRIGGERED-ON-CHANGE-WITHOUT-REPETITION  # Einstellung Sitzheizung Fahrer (0...6)
          signal KL_SIH_Soll_re_XIX_Klima_12_XIX_E3V_EVCANFD: start 11, 3 bit, little-endian, data-type-policy=OVERRIDE, i-signal-type=PRIMITIVE, init-value=0, base-type=BT_KL_SIH_Soll_re, compu {phys=raw for raw 0..6}, range phys 0..6, raw 0..6, transfer-property=TRIGGERED-ON-CHANGE-WITHOUT-REPETITION  # Einstellung Sitzheizung Beifahrer (0...6)
          signal KRH_Soll_li_XIX_Klima_12_XIX_E3V_EVCANFD: start 14, 2 bit, little-endian, data-type-policy=OVERRIDE, i-signal-type=PRIMITIVE, init-value=0, base-type=BT_KRH_Soll_li, compu {0=Cx0_aus (CM_KRH_Soll_li_Cx0_aus), 1=Cx1_Stufe_1 (CM_KRH_Soll_li_Cx1_Stufe_1), 2=Cx2_Stufe_2 (CM_KRH_Soll_li_Cx2_Stufe_2), 3=Cx3_Stufe_3 (CM_KRH_Soll_li_Cx3_Stufe_3)}, range raw 0..3, transfer-property=TRIGGERED-ON-CHANGE-WITHOUT-REPETITION  # Ausgabe des Sollwertes für die Kopfraumheizung links.
          signal KL_SIL_Soll_li_XIX_Klima_12_XIX_E3V_EVCANFD: start 16, 3 bit, little-endian, data-type-policy=OVERRIDE, i-signal-type=PRIMITIVE, init-value=0, base-type=BT_KL_SIL_Soll_li, compu {phys=raw for raw 0..6}, range phys 0..6, raw 0..6, transfer-property=TRIGGERED-ON-CHANGE-WITHOUT-REPETITION  # Einstellung Sitzlüftung Fahrer (0...6)
          signal KL_SIL_Soll_re_XIX_Klima_12_XIX_E3V_EVCANFD: start 19, 3 bit, little-endian, data-type-policy=OVERRIDE, i-signal-type=PRIMITIVE, init-value=0, base-type=BT_KL_SIL_Soll_re, compu {phys=raw for raw 0..6}, range phys 0..6, raw 0..6, transfer-property=TRIGGERED-ON-CHANGE-WITHOUT-REPETITION  # Einstellung Sitzlüftung Beifahrer (0...6)
          signal KRH_Soll_re_XIX_Klima_12_XIX_E3V_EVCANFD: start 22, 2 bit, little-endian, data-type-policy=OVERRIDE, i-signal-type=PRIMITIVE, init-value=0, base-type=BT_KRH_Soll_re, compu {0=Cx0_aus (CM_KRH_Soll_re_Cx0_aus), 1=Cx1_Stufe_1 (CM_KRH_Soll_re_Cx1_Stufe_1), 2=Cx2_Stufe_2 (CM_KRH_Soll_re_Cx2_Stufe_2), 3=Cx3_Stufe_3 (CM_KRH_Soll_re_Cx3_Stufe_3)}, range raw 0..3, transfer-property=TRIGGERED-ON-CHANGE-WITHOUT-REPETITION  # Ausgabe des Sollwertes für die Kopfraumheizung rechts.
          signal KL_Geblspng_Soll_XIX_Klima_12_XIX_E3V_EVCANFD: start 24, 8 bit, little-endian, data-type-policy=OVERRIDE, i-signal-type=PRIMITIVE, init-value=0, base-type=BT_KL_Geblspng_Soll, invalid-value=Invalid_KL_Geblspng_Soll_XIX_Klima_12_XIX_E3V_EVCANFD:255, compu {0=Cx0_0V_Motorspannung (CM_KL_Geblspng_Soll_Cx0_0V_Motorspannung), phys=raw*0.05+1.45 for raw 1..251, 252=Cxfc_0V_sofort_Abschalten (CM_KL_Geblspng_Soll_Cxfc_0V_sofort_Abschalten), 253=Cxfd_0V_senken_mit_Rampe (CM_KL_Geblspng_Soll_Cxfd_0V_senken_mit_Rampe), 254=Cxfe_reserviert (CM_KL_Geblspng_Soll_Cxfe_reserviert), 255=Cxff_Fehler (CM_KL_Geblspng_Soll_Cxff_Fehler); unit Unit_Volt}, range phys 1.5..14 Unit_Volt, raw 0..255, unit=Unit_Volt, transfer-property=PENDING  # Ausgabe des Sollwertes für die Spannung des Klimagebläsemotores vorne.
          signal KL_Geblspng_Fond_Soll_XIX_Klima_12_XIX_E3V_EVCANFD: start 32, 8 bit, little-endian, data-type-policy=OVERRIDE, i-signal-type=PRIMITIVE, init-value=0, base-type=BT_KL_Geblspng_Fond_Soll, invalid-value=Invalid_KL_Geblspng_Fond_Soll_XIX_Klima_12_XIX_E3V_EVCANFD:255, compu {0=Cx0_0V_Motorspannung (CM_KL_Geblspng_Fond_Soll_Cx0_0V_Motorspannung), phys=raw*0.05+1.45 for raw 1..251, 252=Cxfc_0V_sofort_Abschalten (CM_KL_Geblspng_Fond_Soll_Cxfc_0V_sofort_Abschalten), 253=Cxfd_0V_senken_mit_Rampe (CM_KL_Geblspng_Fond_Soll_Cxfd_0V_senken_mit_Rampe), 254=Cxfe_reserviert (CM_KL_Geblspng_Fond_Soll_Cxfe_reserviert), 255=Cxff_Fehler (CM_KL_Geblspng_Fond_Soll_Cxff_Fehler); unit Unit_Volt}, range phys 1.5..14 Unit_Volt, raw 0..255, unit=Unit_Volt, transfer-property=PENDING  # Ausgabe des Sollwertes für die Spannung des Klimagebläsemotores hinten.
          signal KL_I_Geblaese_XIX_Klima_12_XIX_E3V_EVCANFD: start 40, 8 bit, little-endian, data-type-policy=OVERRIDE, i-signal-type=PRIMITIVE, init-value=0, base-type=BT_KL_I_Geblaese, invalid-value=Invalid_KL_I_Geblaese_XIX_Klima_12_XIX_E3V_EVCANFD:255, compu {phys=raw*0.25 for raw 0..254, 255=Cxff_Fehler (CM_KL_I_Geblaese_Cxff_Fehler); unit Unit_Amper}, range phys 0..63.5 Unit_Amper, raw 0..255, unit=Unit_Amper, transfer-property=PENDING  # Stromaufnahme Gebläse
          signal KL_Kompressorstrom_soll_XIX_Klima_12_XIX_E3V_EVCANFD: start 48, 10 bit, little-endian, data-type-policy=OVERRIDE, i-signal-type=PRIMITIVE, init-value=1022, base-type=BT_KL_Kompressorstrom_soll, invalid-value=Invalid_KL_Kompressorstrom_soll_XIX_Klima_12_XIX_E3V_EVCANFD:1023, compu {phys=raw for raw 0..1021, 1022=Cx3fe_Init (CM_KL_Kompressorstrom_soll_Cx3fe_Init), 1023=Cx3ff_Fehler (CM_KL_Kompressorstrom_soll_Cx3ff_Fehler)}, range phys 0..1021, raw 0..1023, transfer-property=PENDING  # Sollvorgabe Klima-Kompressorstrom
          signal KL_Umluftklappe_Status_XIX_Klima_12_XIX_E3V_EVCANFD: start 58, 4 bit, little-endian, data-type-policy=OVERRIDE, i-signal-type=PRIMITIVE, init-value=14, base-type=BT_KL_Umluftklappe_Status, invalid-value=Invalid_KL_Umluftklappe_Status_XIX_Klima_12_XIX_E3V_EVCANFD:15, compu {0=Cx0_Frischluft (CM_KL_Umluftklappe_Status_Cx0_Frischluft), 1=Cx1_Teilumluft_10 (CM_KL_Umluftklappe_Status_Cx1_Teilumluft_10), 2=Cx2_Teilumluft_20 (CM_KL_Umluftklappe_Status_Cx2_Teilumluft_20), 3=Cx3_Teilumluft_30 (CM_KL_Umluftklappe_Status_Cx3_Teilumluft_30), 4=Cx4_Teilumluft_40 (CM_KL_Umluftklappe_Status_Cx4_Teilumluft_40), 5=Cx5_Teilumluft_50 (CM_KL_Umluftklappe_Status_Cx5_Teilumluft_50), 6=Cx6_Teilumluft_60 (CM_KL_Umluftklappe_Status_Cx6_Teilumluft_60), 7=Cx7_Teilumluft_70 (CM_KL_Umluftklappe_Status_Cx7_Teilumluft_70), 8=Cx8_Teilumluft_80 (CM_KL_Umluftklappe_Status_Cx8_Teilumluft_80), 9=Cx9_Teilumluft_90 (CM_KL_Umluftklappe_Status_Cx9_Teilumluft_90), 10=Cxa_Umluft (CM_KL_Umluftklappe_Status_Cxa_Umluft), 14=Cxe_Init (CM_KL_Umluftklappe_Status_Cxe_Init), 15=Cxf_Fehler (CM_KL_Umluftklappe_Status_Cxf_Fehler)}, range raw 0..15, transfer-property=PENDING  # Status Umluftklappe
          signal KL_PTC_Verbauinfo_XIX_Klima_12_XIX_E3V_EVCANFD: start 62, 2 bit, little-endian, data-type-policy=OVERRIDE, i-signal-type=PRIMITIVE, init-value=0, base-type=BT_KL_PTC_Verbauinfo, compu {0=Cx0_kein_PTC (CM_KL_PTC_Verbauinfo_Cx0_kein_PTC), 1=Cx1_600W_geschaltet (CM_KL_PTC_Verbauinfo_Cx1_600W_geschaltet), 2=Cx2_1000W_geschaltet (CM_KL_PTC_Verbauinfo_Cx2_1000W_geschaltet), 3=Cx3_1400W_LIN (CM_KL_PTC_Verbauinfo_Cx3_1400W_LIN)}, range raw 0..3, transfer-property=PENDING  # Im Klima- bzw. Heizungsbedienteil wird der Verbau eines PTCs und dessen elektr. Leistungsklasse codiert
      frame Klima_16_XIX_E3V_EVCANFD: id 0x16A95493, from Klima, frame-length=8, can-addressing-mode=EXTENDED, can-frame-rx-behavior=CAN-FD, can-frame-tx-behavior=CAN-FD
        pdu Klima_16_XIX_E3V_EVCANFD: length=8, minimum-delay=0.2, transmission-mode-true-timing={cyclic-timing={time-offset=0.0, time-period=2.0}, event-controlled-timing={number-of-repetitions=0, repetition-period=0.0}}, unused-bit-pattern=0
          signal KL_Voko_Status_XIX_Klima_16_XIX_E3V_EVCANFD: start 0, 4 bit, little-endian, data-type-policy=OVERRIDE, i-signal-type=PRIMITIVE, init-value=14, base-type=BT_KL_Voko_Status, invalid-value=Invalid_KL_Voko_Status_XIX_Klima_16_XIX_E3V_EVCANFD:15, compu {0=Cx0_aus (CM_KL_Voko_Status_Cx0_aus), 1=Cx1_ein (CM_KL_Voko_Status_Cx1_ein), 14=Cxe_Init (CM_KL_Voko_Status_Cxe_Init), 15=Cxf_Fehler (CM_KL_Voko_Status_Cxf_Fehler)}, range raw 0..15, transfer-property=TRIGGERED-ON-CHANGE-WITHOUT-REPETITION  # Status der Vorkonditionierung. 0 = aus 1 = ein 14 = Init 15 = Fehler
          signal KL_LRH_PWM_XIX_Klima_16_XIX_E3V_EVCANFD: start 4, 7 bit, little-endian, data-type-policy=OVERRIDE, i-signal-type=PRIMITIVE, init-value=0, base-type=BT_KL_LRH_PWM, compu {phys=raw for raw 0..100; unit Unit_PerCent}, range phys 0..100 Unit_PerCent, raw 0..100, unit=Unit_PerCent, transfer-property=TRIGGERED-ON-CHANGE-WITHOUT-REPETITION  # LRH PWM Signal zur Ansteuerung der Treiberstufe im SMLS (0% - 100%)
          signal KL_LRH_Soll_XIX_Klima_16_XIX_E3V_EVCANFD: start 11, 1 bit, little-endian, data-type-policy=OVERRIDE, i-signal-type=PRIMITIVE, init-value=0, base-type=BT_KL_LRH_Soll, compu {0=Cx0_nicht_angefordert (CM_KL_LRH_Soll_Cx0_nicht_angefordert), 1=Cx1_angefordert (CM_KL_LRH_Soll_Cx1_angefordert)}, range raw 0..1, transfer-property=TRIGGERED-ON-CHANGE-WITHOUT-REPETITION  # Sollstatus der Lenkradheizung
          signal KL_AL_VR_Anf_XIX_Klima_16_XIX_E3V_EVCANFD: start 12, 2 bit, little-endian, data-type-policy=OVERRIDE, i-signal-type=PRIMITIVE, init-value=0, base-type=BT_KL_AL_VR_Anf, compu {0=Cx0_neutral (CM_KL_AL_VR_Anf_Cx0_neutral), 1=Cx1_waermer (CM_KL_AL_VR_Anf_Cx1_waermer), 2=Cx2_kaelter (CM_KL_AL_VR_Anf_Cx2_kaelter)}, range raw 0..2, transfer-property=TRIGGERED-ON-CHANGE-WITHOUT-REPETITION  # Anforderung an das funktionale Ambientelicht eine Solltemperaturveränderung vorn rechts darzustellen.
          signal KL_AL_VL_Anf_XIX_Klima_16_XIX_E3V_EVCANFD: start 14, 2 bit, little-endian, data-type-policy=OVERRIDE, i-signal-type=PRIMITIVE, init-value=0, base-type=BT_KL_AL_VL_Anf, compu {0=Cx0_neutral (CM_KL_AL_VL_Anf_Cx0_neutral), 1=Cx1_waermer (CM_KL_AL_VL_Anf_Cx1_waermer), 2=Cx2_kaelter (CM_KL_AL_VL_Anf_Cx2_kaelter)}, range raw 0..2, transfer-property=TRIGGERED-ON-CHANGE-WITHOUT-REPETITION  # Anforderung an das funktionale Ambientelicht eine Solltemperaturveränderung vorn links darzustellen.
          signal KL_AL_HR_Anf_XIX_Klima_16_XIX_E3V_EVCANFD: start 16, 2 bit, little-endian, data-type-policy=OVERRIDE, i-signal-type=PRIMITIVE, init-value=0, base-type=BT_KL_AL_HR_Anf, compu {0=Cx0_neutral (CM_KL_AL_HR_Anf_Cx0_neutral), 1=Cx1_waermer (CM_KL_AL_HR_Anf_Cx1_waermer), 2=Cx2_kaelter (CM_KL_AL_HR_Anf_Cx2_kaelter)}, range raw 0..2, transfer-property=TRIGGERED-ON-CHANGE-WITHOUT-REPETITION  # Anforderung an das funktionale Ambientelicht eine Solltemperaturveränderung hinten rechts darzustellen.
          signal KL_AL_HL_Anf_XIX_Klima_16_XIX_E3V_EVCANFD: start 18, 2 bit, little-endian, data-type-policy=OVERRIDE, i-signal-type=PRIMITIVE, init-value=0, base-type=BT_KL_AL_HL_Anf, compu {0=Cx0_neutral (CM_KL_AL_HL_Anf_Cx0_neutral), 1=Cx1_waermer (CM_KL_AL_HL_Anf_Cx1_waermer), 2=Cx2_kaelter (CM_KL_AL_HL_Anf_Cx2_kaelter)}, range raw 0..2, transfer-property=TRIGGERED-ON-CHANGE-WITHOUT-REPETITION  # Anforderung an das funktionale Ambientelicht eine Solltemperaturveränderung hinten links darzustellen.
          signal KL_HSH_Soll_XIX_Klima_16_XIX_E3V_EVCANFD: start 20, 1 bit, little-endian, data-type-policy=OVERRIDE, i-signal-type=PRIMITIVE, init-value=0, base-type=BT_KL_HSH_Soll, compu {0=Cx0_nicht_angefordert (CM_KL_HSH_Soll_Cx0_nicht_angefordert), 1=Cx1_angefordert (CM_KL_HSH_Soll_Cx1_angefordert)}, range raw 0..1, transfer-property=TRIGGERED-ON-CHANGE-WITHOUT-REPETITION  # Sollstatus Heckscheibenheizung
          signal KL_FSH_Soll_XIX_Klima_16_XIX_E3V_EVCANFD: start 21, 1 bit, little-endian, data-type-policy=OVERRIDE, i-signal-type=PRIMITIVE, init-value=0, base-type=BT_KL_FSH_Soll, compu {0=Cx0_nicht_angefordert (CM_KL_FSH_Soll_Cx0_nicht_angefordert), 1=Cx1_angefordert (CM_KL_FSH_Soll_Cx1_angefordert)}, range raw 0..1, transfer-property=TRIGGERED-ON-CHANGE-WITHOUT-REPETITION  # Sollstatus der Frontscheibenheizung
          signal KL_ZR_Anforderung_XIX_Klima_16_XIX_E3V_EVCANFD: start 22, 2 bit, little-endian, data-type-policy=OVERRIDE, i-signal-type=PRIMITIVE, init-value=0, base-type=BT_KL_ZR_Anforderung, compu {0=Cx0_init (CM_KL_ZR_Anforderung_Cx0_init), 1=Cx1_inaktiv (CM_KL_ZR_Anforderung_Cx1_inaktiv), 2=Cx2_aktiv (CM_KL_ZR_Anforderung_Cx2_aktiv), 3=Cx3_reserviert (CM_KL_ZR_Anforderung_Cx3_reserviert)}, range raw 0..3, transfer-property=TRIGGERED-ON-CHANGE-WITHOUT-REPETITION  # Anforderung an MIB die Displays zu aktivieren
          signal KL_VoKo_LED_XIX_Klima_16_XIX_E3V_EVCANFD: start 24, 1 bit, little-endian, data-type-policy=OVERRIDE, i-signal-type=PRIMITIVE, init-value=0, base-type=BT_KL_VoKo_LED, compu {0=Cx0_Aus (CM_KL_VoKo_LED_Cx0_Aus), 1=Cx1_Ein (CM_KL_VoKo_LED_Cx1_Ein)}, range raw 0..1, transfer-property=TRIGGERED-ON-CHANGE-WITHOUT-REPETITION  # Signalisierung Vorkonditionierung
          signal KL_Defrost_LED_XIX_Klima_16_XIX_E3V_EVCANFD: start 25, 1 bit, little-endian, data-type-policy=OVERRIDE, i-signal-type=PRIMITIVE, init-value=0, base-type=BT_KL_Defrost_LED, compu {0=Cx0_Aus (CM_KL_Defrost_LED_Cx0_Aus), 1=Cx1_Ein (CM_KL_Defrost_LED_Cx1_Ein)}, range raw 0..1, transfer-property=TRIGGERED-ON-CHANGE-WITHOUT-REPETITION  # Beleuchtung LED Defrost
          signal KL_HSH_LED_XIX_Klima_16_XIX_E3V_EVCANFD: start 26, 1 bit, little-endian, data-type-policy=OVERRIDE, i-signal-type=PRIMITIVE, init-value=0, base-type=BT_KL_HSH_LED, compu {0=Cx0_Aus (CM_KL_HSH_LED_Cx0_Aus), 1=Cx1_Ein (CM_KL_HSH_LED_Cx1_Ein)}, range raw 0..1, transfer-property=TRIGGERED-ON-CHANGE-WITHOUT-REPETITION  # Beleuchtung LED Heckscheibenheizung
          signal HSH_Relais_Anf_XIX_Klima_16_XIX_E3V_EVCANFD: start 27, 1 bit, little-endian, data-type-policy=OVERRIDE, i-signal-type=PRIMITIVE, init-value=0, base-type=BT_HSH_Relais_Anf, compu {0=Cx0_nicht_angefordert (CM_HSH_Relais_Anf_Cx0_nicht_angefordert), 1=Cx1_angefordert (CM_HSH_Relais_Anf_Cx1_angefordert)}, range raw 0..1, transfer-property=TRIGGERED-ON-CHANGE-WITHOUT-REPETITION  # Relaisanforderung Heckscheibenheizung
          signal FSH_Status_XIX_Klima_16_XIX_E3V_EVCANFD: start 28, 2 bit, little-endian, data-type-policy=OVERRIDE, i-signal-type=PRIMITIVE, init-value=0, base-type=BT_FSH_Status, invalid-value=Invalid_FSH_Status_XIX_Klima_16_XIX_E3V_EVCANFD:3, compu {0=Cx0_aus (CM_FSH_Status_Cx0_aus), 1=Cx1_ein (CM_FSH_Status_Cx1_ein), 2=Cx2_tbd (CM_FSH_Status_Cx2_tbd), 3=Cx3_Fehler (CM_FSH_Status_Cx3_Fehler)}, range raw 0..3, transfer-property=PENDING  # Fehlerstatus der Frontscheibenheizung
          signal SIH_Stufe_LED_li_XIX_Klima_16_XIX_E3V_EVCANFD: start 30, 3 bit, little-endian, data-type-policy=OVERRIDE, i-signal-type=PRIMITIVE, init-value=0, base-type=BT_SIH_Stufe_LED_li, compu {0=Cx0_Aus (CM_SIH_Stufe_LED_li_Cx0_Aus), 2=Cx2_Stufe_2 (CM_SIH_Stufe_LED_li_Cx2_Stufe_2), 4=Cx4_Stufe_4 (CM_SIH_Stufe_LED_li_Cx4_Stufe_4), 6=Cx6_Stufe_6 (CM_SIH_Stufe_LED_li_Cx6_Stufe_6)}, range raw 0..6, transfer-property=TRIGGERED-ON-CHANGE-WITHOUT-REPETITION  # Statusmeldung Sitzheizung links
          signal SIH_Stufe_LED_re_XIX_Klima_16_XIX_E3V_EVCANFD: start 33, 3 bit, little-endian, data-type-policy=OVERRIDE, i-signal-type=PRIMITIVE, init-value=0, base-type=BT_SIH_Stufe_LED_re, compu {0=Cx0_Aus (CM_SIH_Stufe_LED_re_Cx0_Aus), 2=Cx2_Stufe_2 (CM_SIH_Stufe_LED_re_Cx2_Stufe_2), 4=Cx4_Stufe_4 (CM_SIH_Stufe_LED_re_Cx4_Stufe_4), 6=Cx6_Stufe_6 (CM_SIH_Stufe_LED_re_Cx6_Stufe_6)}, range raw 0..6, transfer-property=TRIGGERED-ON-CHANGE-WITHOUT-REPETITION  # Statusmeldung Sitzheizung rechts
          signal KL_FSH_LED_XIX_Klima_16_XIX_E3V_EVCANFD: start 36, 1 bit, little-endian, data-type-policy=OVERRIDE, i-signal-type=PRIMITIVE, init-value=0, base-type=BT_KL_FSH_LED, compu {0=Cx0_Aus (CM_KL_FSH_LED_Cx0_Aus), 1=Cx1_Ein (CM_KL_FSH_LED_Cx1_Ein)}, range raw 0..1, transfer-property=TRIGGERED-ON-CHANGE-WITHOUT-REPETITION  # Beleuchtung LED Frontscheibenheizung
          signal KL_HUP_aktiv_XIX_Klima_16_XIX_E3V_EVCANFD: start 37, 1 bit, little-endian, data-type-policy=OVERRIDE, i-signal-type=PRIMITIVE, init-value=0, base-type=BT_KL_HUP_aktiv, compu {0=Cx0_Aus (CM_KL_HUP_aktiv_Cx0_Aus), 1=Cx1_Ein (CM_KL_HUP_aktiv_Cx1_Ein)}, range raw 0..1, transfer-property=TRIGGERED-ON-CHANGE-WITHOUT-REPETITION  # Signal des Klimabedienteils ob HUP aktiv ist. 0 = HUP aus 1 = HUP ein
          signal KL_LSH_DBetr_Ein_XIX_Klima_16_XIX_E3V_EVCANFD: start 38, 1 bit, little-endian, data-type-policy=OVERRIDE, i-signal-type=PRIMITIVE, init-value=0, base-type=BT_KL_LSH_DBetr_Ein, compu {0=Cx0_Dauerbetrieb_nicht_gefordert (CM_KL_LSH_DBetr_Ein_Cx0_Dauerbetrieb_nicht_gefordert), 1=Cx1_Dauerbetrieb_gefordert (CM_KL_LSH_DBetr_Ein_Cx1_Dauerbetrieb_gefordert)}, range raw 0..1, transfer-property=TRIGGERED-ON-CHANGE-WITHOUT-REPETITION  # Dauerbetrieb der Luftstandheizung Ein
          signal KL_LSH_DBetr_Bestaet_XIX_Klima_16_XIX_E3V_EVCANFD: start 39, 1 bit, little-endian, data-type-policy=OVERRIDE, i-signal-type=PRIMITIVE, init-value=0, base-type=BT_KL_LSH_DBetr_Bestaet, compu {0=Cx0_kein_Dauerbetrieb (CM_KL_LSH_DBetr_Bestaet_Cx0_kein_Dauerbetrieb), 1=Cx1_Dauerbetrieb_bestaetigt (CM_KL_LSH_DBetr_Bestaet_Cx1_Dauerbetrieb_bestaetigt)}, range raw 0..1, transfer-property=TRIGGERED-ON-CHANGE-WITHOUT-REPETITION  # Bestätigung des Klimabedienteils an die LSH das Dauerbetrieb tatsächlich angefordert ist.
          signal KL_Klappe_Status_XIX_Klima_16_XIX_E3V_EVCANFD: start 40, 3 bit, little-endian, data-type-policy=OVERRIDE, i-signal-type=PRIMITIVE, init-value=0, base-type=BT_KL_Klappe_Status, compu {0=Cx0_Init (CM_KL_Klappe_Status_Cx0_Init), 1=Cx1_Front (CM_KL_Klappe_Status_Cx1_Front), 2=Cx2_Heck (CM_KL_Klappe_Status_Cx2_Heck), 3=Cx3_Front_u_Heck (CM_KL_Klappe_Status_Cx3_Front_u_Heck), 4=Cx4_misch_Front_u_Heck (CM_KL_Klappe_Status_Cx4_misch_Front_u_Heck)}, range raw 0..4, transfer-property=TRIGGERED-ON-CHANGE-WITHOUT-REPETITION  # Status Luftklappe
          signal KL_LSH_Ansteuerung_XIX_Klima_16_XIX_E3V_EVCANFD: start 43, 2 bit, little-endian, data-type-policy=OVERRIDE, i-signal-type=PRIMITIVE, init-value=0, base-type=BT_KL_LSH_Ansteuerung, compu {0=Cx0_Aus (CM_KL_LSH_Ansteuerung_Cx0_Aus), 1=Cx1_Ein (CM_KL_LSH_Ansteuerung_Cx1_Ein), 2=Cx2_Kombi_Betrieb (CM_KL_LSH_Ansteuerung_Cx2_Kombi_Betrieb), 3=Cx3_Heizleistung_reduziert (CM_KL_LSH_Ansteuerung_Cx3_Heizleistung_reduziert)}, range raw 0..3, transfer-property=TRIGGERED-ON-CHANGE-WITHOUT-REPETITION  # Ansteuerung LSH
          signal KL_Heizstufe_LSH_XIX_Klima_16_XIX_E3V_EVCANFD: start 45, 4 bit, little-endian, data-type-policy=OVERRIDE, i-signal-type=PRIMITIVE, init-value=0, base-type=BT_KL_Heizstufe_LSH, invalid-value=Invalid_KL_Heizstufe_LSH_XIX_Klima_16_XIX_E3V_EVCANFD:15, compu {0=Cx0_Init (CM_KL_Heizstufe_LSH_Cx0_Init), 1=Cx1_Stufe_1 (CM_KL_Heizstufe_LSH_Cx1_Stufe_1), 2=Cx2_Stufe_2 (CM_KL_Heizstufe_LSH_Cx2_Stufe_2), 3=Cx3_Stufe_3 (CM_KL_Heizstufe_LSH_Cx3_Stufe_3), 4=Cx4_Stufe_4 (CM_KL_Heizstufe_LSH_Cx4_Stufe_4), 5=Cx5_Stufe_5 (CM_KL_Heizstufe_LSH_Cx5_Stufe_5), 6=Cx6_Stufe_6 (CM_KL_Heizstufe_LSH_Cx6_Stufe_6), 7=Cx7_Stufe_7 (CM_KL_Heizstufe_LSH_Cx7_Stufe_7), 8=Cx8_Stufe_8 (CM_KL_Heizstufe_LSH_Cx8_Stufe_8), 9=Cx9_Stufe_9 (CM_KL_Heizstufe_LSH_Cx9_Stufe_9), 10=Cxa_Stufe_10 (CM_KL_Heizstufe_LSH_Cxa_Stufe_10), 15=Cxf_Fehler (CM_KL_Heizstufe_LSH_Cxf_Fehler)}, range raw 0..15, transfer-property=TRIGGERED-ON-CHANGE-WITHOUT-REPETITION  # Vom Klimabedienteil gesendete Heizstufe der Luftstandheizung
          signal KL_LSH_Betriebsdauer_XIX_Klima_16_XIX_E3V_EVCANFD: start 49, 7 bit, little-endian, data-type-policy=OVERRIDE, i-signal-type=PRIMITIVE, init-value=0, base-type=BT_KL_LSH_Betriebsdauer, compu {phys=raw for raw 0..120, 127=Cx7f_Dauerbetrieb (CM_KL_LSH_Betriebsdauer_Cx7f_Dauerbetrieb); unit Unit_Minut}, range phys 0..120 Unit_Minut, raw 0..127, unit=Unit_Minut, transfer-property=TRIGGERED-ON-CHANGE-WITHOUT-REPETITION  # Betriebsdauer LSH
          signal KL_Temp_ZH_Soll_XIX_Klima_16_XIX_E3V_EVCANFD: start 56, 8 bit, little-endian, data-type-policy=OVERRIDE, i-signal-type=PRIMITIVE, init-value=0, base-type=BT_KL_Temp_ZH_Soll, invalid-value=Invalid_KL_Temp_ZH_Soll_XIX_Klima_16_XIX_E3V_EVCANFD:255, compu {0=Cx0_Funk_nicht_verbaut_nicht_aktiv (CM_KL_Temp_ZH_Soll_Cx0_Funk_nicht_verbaut_nicht_aktiv), phys=raw*0.5 for raw 1..254, 255=Cxff_Fehler (CM_KL_Temp_ZH_Soll_Cxff_Fehler); unit Unit_DegreCelsi}, range phys 0.5..127 Unit_DegreCelsi, raw 0..255, unit=Unit_DegreCelsi, transfer-property=TRIGGERED-ON-CHANGE-WITHOUT-REPETITION  # Übertragung der Temperaturvorgabe der Klimaanlage an die Wasserzusatzheizung
      frame Klima_21_XIX_E3V_EVCANFD: id 0x1A5556AF, from Klima, frame-length=8, can-addressing-mode=EXTENDED, can-frame-rx-behavior=CAN-FD, can-frame-tx-behavior=CAN-FD
        pdu Klima_21_XIX_E3V_EVCANFD: length=8, transmission-mode-true-timing=cyclic-timing={time-offset=0.0, time-period=1.0}, unused-bit-pattern=0
          signal KL_LRH_FoD_Status_XIX_Klima_21_XIX_E3V_EVCANFD: start 12, 2 bit, little-endian, data-type-policy=OVERRIDE, i-signal-type=PRIMITIVE, init-value=0, base-type=BT_KL_LRH_FoD_Status, compu {0=Cx0_init (CM_KL_LRH_FoD_Status_Cx0_init), 1=Cx1_Funktion_inaktiv (CM_KL_LRH_FoD_Status_Cx1_Funktion_inaktiv), 2=Cx2_Funktion_aktiv (CM_KL_LRH_FoD_Status_Cx2_Funktion_aktiv)}, range raw 0..2, transfer-property=PENDING  # LRH-Funktionsspezifisches FoD Statussignal
      frame Klima_EV_03_XIX_E3V_EVCANFD: id 0x5E7, from Klima, frame-length=8, can-addressing-mode=STANDARD, can-frame-rx-behavior=CAN-FD, can-frame-tx-behavior=CAN-FD
        pdu Klima_EV_03_XIX_E3V_EVCANFD: length=8, transmission-mode-true-timing=cyclic-timing={time-offset=0.0, time-period=0.2}, unused-bit-pattern=0
          signal KL_HV_Heizer_Strom_XIX_Klima_EV_03_XIX_E3V_EVCANFD: start 0, 8 bit, little-endian, data-type-policy=OVERRIDE, i-signal-type=PRIMITIVE, init-value=255, base-type=BT_KL_HV_Heizer_Strom, compu {phys=raw*0.25 for raw 0..254, 255=Cxff_Init (CM_KL_HV_Heizer_Strom_Cxff_Init); unit Unit_Amper}, range phys 0..63.5 Unit_Amper, raw 0..255, unit=Unit_Amper, transfer-property=PENDING  # Strom HV-Heizer für Reichweitenberechnung
          signal KL_EKK_Strom_XIX_Klima_EV_03_XIX_E3V_EVCANFD: start 8, 8 bit, little-endian, data-type-policy=OVERRIDE, i-signal-type=PRIMITIVE, init-value=255, base-type=BT_KL_EKK_Strom, compu {phys=raw*0.25 for raw 0..254, 255=Cxff_Init (CM_KL_EKK_Strom_Cxff_Init); unit Unit_Amper}, range phys 0..63.5 Unit_Amper, raw 0..255, unit=Unit_Amper, transfer-property=PENDING  # EKK Stromaufnahme (Hochvolt)
          signal KL_Pumpe_02_Soll_XIX_Klima_EV_03_XIX_E3V_EVCANFD: start 16, 7 bit, little-endian, data-type-policy=OVERRIDE, i-signal-type=PRIMITIVE, init-value=126, base-type=BT_KL_Pumpe_02_Soll, invalid-value=Invalid_KL_Pumpe_02_Soll_XIX_Klima_EV_03_XIX_E3V_EVCANFD:127, compu {phys=raw for raw 0..100, 126=Cx7e_Init (CM_KL_Pumpe_02_Soll_Cx7e_Init), 127=Cx7f_Fehler (CM_KL_Pumpe_02_Soll_Cx7f_Fehler); unit Unit_PerCent}, range phys 0..100 Unit_PerCent, raw 0..127, unit=Unit_PerCent, transfer-property=PENDING  # Anforderung KM-Pumpe Klimakreislauf Init (126dec) = 0% Ansteuerung Pumpe Fehler (127dec) = 100% Ansteuerung Pumpe
          signal KL_Ventil_03_Soll_XIX_Klima_EV_03_XIX_E3V_EVCANFD: start 23, 1 bit, little-endian, data-type-policy=OVERRIDE, i-signal-type=PRIMITIVE, init-value=0, base-type=BT_KL_Ventil_03_Soll, compu {0=Cx0_nicht_ansteuern (CM_KL_Ventil_03_Soll_Cx0_nicht_ansteuern), 1=Cx1_Ventil_ansteuern (CM_KL_Ventil_03_Soll_Cx1_Ventil_ansteuern)}, range raw 0..1, transfer-property=PENDING  # Anforderung Batteriebypass-Ventil im Klimakreislauf
          signal KL_Ventil_10_Status_XIX_Klima_EV_03_XIX_E3V_EVCANFD: start 24, 3 bit, little-endian, data-type-policy=OVERRIDE, i-signal-type=PRIMITIVE, init-value=6, base-type=BT_KL_Ventil_10_Status, invalid-value=Invalid_KL_Ventil_10_Status_XIX_Klima_EV_03_XIX_E3V_EVCANFD:7, compu {0=Cx0_Ventil_nicht_angesteuert (CM_KL_Ventil_10_Status_Cx0_Ventil_nicht_angesteuert), 1=Cx1_Ventil_angesteuert (CM_KL_Ventil_10_Status_Cx1_Ventil_angesteuert), 2=Cx2_reserviert (CM_KL_Ventil_10_Status_Cx2_reserviert), 3=Cx3_reserviert (CM_KL_Ventil_10_Status_Cx3_reserviert), 4=Cx4_reserviert (CM_KL_Ventil_10_Status_Cx4_reserviert), 5=Cx5_Ventil_nicht_verbaut (CM_KL_Ventil_10_Status_Cx5_Ventil_nicht_verbaut), 6=Cx6_Init (CM_KL_Ventil_10_Status_Cx6_Init), 7=Cx7_Fehler (CM_KL_Ventil_10_Status_Cx7_Fehler)}, range raw 0..7, transfer-property=PENDING  # Status Ventil_Wärmepumpe; nicht angesteuert: Motor- und Heizkreislauf getrennt; angesteuert: Motor- und Heizkreislauf verbunden.
          signal KL_Senderkennung_XIX_Klima_EV_03_XIX_E3V_EVCANFD: start 27, 1 bit, little-endian, data-type-policy=OVERRIDE, i-signal-type=PRIMITIVE, init-value=0, base-type=BT_KL_Senderkennung, compu {0=Cx0_Sender_Climatronic_SG (CM_KL_Senderkennung_Cx0_Sender_Climatronic_SG) (Sender Climatronic SG), 1=Cx1_Sender_Waermepumpen_SG (CM_KL_Senderkennung_Cx1_Sender_Waermepumpen_SG) (Sender Waermepumpen SG)}, range raw 0..1, transfer-property=PENDING  # Gibt an, welches SG (Klima oder WP) die Botschaft sendet
          signal WP_KJ_Soll_XIX_Klima_EV_03_XIX_E3V_EVCANFD: start 28, 2 bit, little-endian, data-type-policy=OVERRIDE, i-signal-type=PRIMITIVE, init-value=0, base-type=BT_WP_KJ_Soll, invalid-value=Invalid_WP_KJ_Soll_XIX_Klima_EV_03_XIX_E3V_EVCANFD:3, compu {0=Cx0_Init_Keine_Anforderung (CM_WP_KJ_Soll_Cx0_Init_Keine_Anforderung), 1=Cx1_KJ_oeffnen (CM_WP_KJ_Soll_Cx1_KJ_oeffnen), 2=Cx2_KJ_schliessen (CM_WP_KJ_Soll_Cx2_KJ_schliessen), 3=Cx3_Fehler (CM_WP_KJ_Soll_Cx3_Fehler)}, range raw 0..3, transfer-property=PENDING  # Anforderung der Kuehlerjalousiestellung durch Waermepumpen SG
          signal KL_Fehler_HV_EKK_XIX_Klima_EV_03_XIX_E3V_EVCANFD: start 30, 2 bit, little-endian, data-type-policy=OVERRIDE, i-signal-type=PRIMITIVE, init-value=0, base-type=BT_KL_Fehler_HV_EKK, invalid-value=Invalid_KL_Fehler_HV_EKK_XIX_Klima_EV_03_XIX_E3V_EVCANFD:3, compu {0=Cx0_Init (CM_KL_Fehler_HV_EKK_Cx0_Init), 1=Cx1_Kein_HV_Fehler_am_EKK_erkannt (CM_KL_Fehler_HV_EKK_Cx1_Kein_HV_Fehler_am_EKK_erkannt) (Kein HV Fehler am EKK erkannt), 2=Cx2_HV_Fehler_am_EKK_erkannt (CM_KL_Fehler_HV_EKK_Cx2_HV_Fehler_am_EKK_erkannt) (HV Fehler am EKK erkannt), 3=Cx3_Fehler (CM_KL_Fehler_HV_EKK_Cx3_Fehler)}, range raw 0..3, transfer-property=PENDING  # Fehlersignal bei Erkennung HV Fehler am elektrischen Klimakompressor EKK Sender: Klima MQB (evtl. Wärmepumpen SG MQB, OBD SG MQB)
          signal KL_Fehler_HV_Heizer_XIX_Klima_EV_03_XIX_E3V_EVCANFD: start 32, 2 bit, little-endian, data-type-policy=OVERRIDE, i-signal-type=PRIMITIVE, init-value=0, base-type=BT_KL_Fehler_HV_Heizer, invalid-value=Invalid_KL_Fehler_HV_Heizer_XIX_Klima_EV_03_XIX_E3V_EVCANFD:3, compu {0=Cx0_Init (CM_KL_Fehler_HV_Heizer_Cx0_Init), 1=Cx1_Kein_HV_Fehler_am_HV_Heizer_erkannt (CM_KL_Fehler_HV_Heizer_Cx1_Kein_HV_Fehler_am_HV_Heizer_erkannt) (Kein HV Fehler am HV Heizer erkannt), 2=Cx2_HV_Fehler_am_HV_Heizer_erkannt (CM_KL_Fehler_HV_Heizer_Cx2_HV_Fehler_am_HV_Heizer_erkannt) (HV Fehler am HV Heizer erkannt), 3=Cx3_Fehler (CM_KL_Fehler_HV_Heizer_Cx3_Fehler)}, range raw 0..3, transfer-property=PENDING  # Fehlersignal bei Erkennung HV Fehler am HV Heizer Sender: Klima MQB (evtl. Wärmepumpen SG MQB, OBD SG MQB)
          signal KL_BattKond_WaPu_DZMax_XIX_Klima_EV_03_XIX_E3V_EVCANFD: start 34, 6 bit, little-endian, data-type-policy=OVERRIDE, i-signal-type=PRIMITIVE, init-value=62, base-type=BT_KL_BattKond_WaPu_DZMax, invalid-value=Invalid_KL_BattKond_WaPu_DZMax_XIX_Klima_EV_03_XIX_E3V_EVCANFD:63, compu {phys=raw*2 for raw 0..50, 62=Cx3e_Init (CM_KL_BattKond_WaPu_DZMax_Cx3e_Init), 63=Cx3f_Fehler (CM_KL_BattKond_WaPu_DZMax_Cx3f_Fehler); unit Unit_PerCent}, range phys 0..100 Unit_PerCent, raw 0..63, unit=Unit_PerCent, transfer-property=PENDING  # Maximal-Drehzahl der Wasserpumpe im Batteriekühlkreislauf als Vorgabe für BMS
          signal WP_Kuehlerluefter_Anf_XIX_Klima_EV_03_XIX_E3V_EVCANFD: start 40, 8 bit, little-endian, data-type-policy=OVERRIDE, i-signal-type=PRIMITIVE, init-value=0, base-type=BT_WP_Kuehlerluefter_Anf, invalid-value=Invalid_WP_Kuehlerluefter_Anf_XIX_Klima_EV_03_XIX_E3V_EVCANFD:255, compu {phys=raw*0.4 for raw 0..254, 255=Cxff_Fehler (CM_WP_Kuehlerluefter_Anf_Cxff_Fehler); unit Unit_PerCent}, range phys 0..101.6 Unit_PerCent, raw 0..255, unit=Unit_PerCent, transfer-property=PENDING  # Anforderung Kühlerlüfter durch Wärmepumpen SG
          signal KL_KM_ASV_01_Status_XIX_Klima_EV_03_XIX_E3V_EVCANFD: start 48, 2 bit, little-endian, data-type-policy=OVERRIDE, i-signal-type=PRIMITIVE, base-type=BT_KL_KM_ASV_01_Status, invalid-value=Invalid_KL_KM_ASV_01_Status_XIX_Klima_EV_03_XIX_E3V_EVCANFD:3, compu {0=Cx0_Ventil_nicht_geschaltet (CM_KL_KM_ASV_01_Status_Cx0_Ventil_nicht_geschaltet) (Ventil nicht geschaltet), 1=Cx1_Ventil_geschaltet (CM_KL_KM_ASV_01_Status_Cx1_Ventil_geschaltet) (Ventil geschaltet), 2=Cx2_Ventil_nicht_verbaut (CM_KL_KM_ASV_01_Status_Cx2_Ventil_nicht_verbaut) (Ventil nicht verbaut), 3=Cx3_Fehler (CM_KL_KM_ASV_01_Status_Cx3_Fehler)}, range raw 0..3, transfer-property=PENDING  # Schaltstatus Kältemittel Absperrventil VW370/9 PHEV = Ventil vor Verdampfer
          signal KL_KM_ASV_02_Status_XIX_Klima_EV_03_XIX_E3V_EVCANFD: start 50, 2 bit, little-endian, data-type-policy=OVERRIDE, i-signal-type=PRIMITIVE, base-type=BT_KL_KM_ASV_02_Status, invalid-value=Invalid_KL_KM_ASV_02_Status_XIX_Klima_EV_03_XIX_E3V_EVCANFD:3, compu {0=Cx0_Ventil_nicht_geschaltet (CM_KL_KM_ASV_02_Status_Cx0_Ventil_nicht_geschaltet) (Ventil nicht geschaltet), 1=Cx1_Ventil_geschaltet (CM_KL_KM_ASV_02_Status_Cx1_Ventil_geschaltet) (Ventil geschaltet), 2=Cx2_Ventil_nicht_verbaut (CM_KL_KM_ASV_02_Status_Cx2_Ventil_nicht_verbaut) (Ventil nicht verbaut), 3=Cx3_Fehler (CM_KL_KM_ASV_02_Status_Cx3_Fehler)}, range raw 0..3, transfer-property=PENDING  # Schaltstatus Kältemittel Absperrventil VW370/9 PHEV = Ventil vor Chiller
          signal KL_Vorwarn_HVHeizer_Leistung_XIX_Klima_EV_03_XIX_E3V_EVCANFD: start 52, 4 bit, little-endian, data-type-policy=OVERRIDE, i-signal-type=PRIMITIVE, init-value=0, base-type=BT_KL_Vorwarn_HVHeizer_Leistung, invalid-value=Invalid_KL_Vorwarn_HVHeizer_Leistung_XIX_Klima_EV_03_XIX_E3V_EVCANFD:15, compu {0=Cx0_Init_Aus (CM_KL_Vorwarn_HVHeizer_Leistung_Cx0_Init_Aus), 1=Cx1_500W (CM_KL_Vorwarn_HVHeizer_Leistung_Cx1_500W), 2=Cx2_1000W (CM_KL_Vorwarn_HVHeizer_Leistung_Cx2_1000W), 3=Cx3_1500W (CM_KL_Vorwarn_HVHeizer_Leistung_Cx3_1500W), 4=Cx4_2000W (CM_KL_Vorwarn_HVHeizer_Leistung_Cx4_2000W), 5=Cx5_2500W (CM_KL_Vorwarn_HVHeizer_Leistung_Cx5_2500W), 6=Cx6_3000W (CM_KL_Vorwarn_HVHeizer_Leistung_Cx6_3000W), 7=Cx7_3500W (CM_KL_Vorwarn_HVHeizer_Leistung_Cx7_3500W), 8=Cx8_4000W (CM_KL_Vorwarn_HVHeizer_Leistung_Cx8_4000W), 9=Cx9_4500W (CM_KL_Vorwarn_HVHeizer_Leistung_Cx9_4500W), 10=Cxa_5000W (CM_KL_Vorwarn_HVHeizer_Leistung_Cxa_5000W), 11=Cxb_5500W (CM_KL_Vorwarn_HVHeizer_Leistung_Cxb_5500W), 12=Cxc_6000W (CM_KL_Vorwarn_HVHeizer_Leistung_Cxc_6000W), 13=Cxd_6500W (CM_KL_Vorwarn_HVHeizer_Leistung_Cxd_6500W), 14=Cxe_7000W (CM_KL_Vorwarn_HVHeizer_Leistung_Cxe_7000W), 15=Cxf_Fehler (CM_KL_Vorwarn_HVHeizer_Leistung_Cxf_Fehler)}, range raw 0..15, transfer-property=PENDING  # Vorwarnung der Heizerleistung für die Stromregelung. Botschaft: Klima_EV_03, da das Signal entweder vom Klimasteuergerät oder dem Wärmepumpensteuergerät gesendet werden soll.
          signal KL_Status_EoHVL_EKK_XIX_Klima_EV_03_XIX_E3V_EVCANFD: start 56, 2 bit, little-endian, data-type-policy=OVERRIDE, i-signal-type=PRIMITIVE, init-value=0, base-type=BT_KL_Status_EoHVL_EKK, invalid-value=Invalid_KL_Status_EoHVL_EKK_XIX_Klima_EV_03_XIX_E3V_EVCANFD:3, compu {0=Cx0_Init (CM_KL_Status_EoHVL_EKK_Cx0_Init), 1=Cx1_Keine_offene_HV_Leitung_erkannt (CM_KL_Status_EoHVL_EKK_Cx1_Keine_offene_HV_Leitung_erkannt), 2=Cx2_offene_HV_Leitung_erkannt (CM_KL_Status_EoHVL_EKK_Cx2_offene_HV_Leitung_erkannt), 3=Cx3_Fehler (CM_KL_Status_EoHVL_EKK_Cx3_Fehler)}, range raw 0..3, transfer-property=PENDING  # Erkennung einer offenen HV-Leitung (EoHVL). Bewertet anhand einer Spannungsgrenze.
          signal KL_Status_EoHVL_Heizer_XIX_Klima_EV_03_XIX_E3V_EVCANFD: start 58, 2 bit, little-endian, data-type-policy=OVERRIDE, i-signal-type=PRIMITIVE, init-value=0, base-type=BT_KL_Status_EoHVL_Heizer, invalid-value=Invalid_KL_Status_EoHVL_Heizer_XIX_Klima_EV_03_XIX_E3V_EVCANFD:3, compu {0=Cx0_Init (CM_KL_Status_EoHVL_Heizer_Cx0_Init), 1=Cx1_Keine_offene_HV_Leitung_erkannt (CM_KL_Status_EoHVL_Heizer_Cx1_Keine_offene_HV_Leitung_erkannt), 2=Cx2_offene_HV_Leitung_erkannt (CM_KL_Status_EoHVL_Heizer_Cx2_offene_HV_Leitung_erkannt), 3=Cx3_Fehler (CM_KL_Status_EoHVL_Heizer_Cx3_Fehler)}, range raw 0..3, transfer-property=PENDING  # Erkennung einer offenen HV-Leitung (EoHVL). Bewertet anhand einer Spannungsgrenze.
          signal KL_Status_EoHVL_Heizer_2_XIX_Klima_EV_03_XIX_E3V_EVCANFD: start 62, 2 bit, little-endian, data-type-policy=OVERRIDE, i-signal-type=PRIMITIVE, init-value=0, base-type=BT_KL_Status_EoHVL_Heizer_2, invalid-value=Invalid_KL_Status_EoHVL_Heizer_2_XIX_Klima_EV_03_XIX_E3V_EVCANFD:3, compu {0=Cx0_Init (CM_KL_Status_EoHVL_Heizer_2_Cx0_Init), 1=Cx1_Keine_offene_HV_Leitung_erkannt (CM_KL_Status_EoHVL_Heizer_2_Cx1_Keine_offene_HV_Leitung_erkannt), 2=Cx2_offene_HV_Leitung_erkannt (CM_KL_Status_EoHVL_Heizer_2_Cx2_offene_HV_Leitung_erkannt), 3=Cx3_Fehler (CM_KL_Status_EoHVL_Heizer_2_Cx3_Fehler)}, range raw 0..3, transfer-property=PENDING  # Erkennung einer offenen HV-Leitung (EoHVL). Bewertet anhand einer Spannungsgrenze.
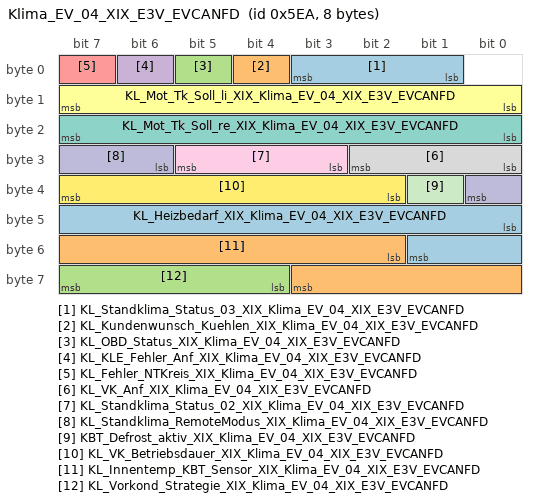
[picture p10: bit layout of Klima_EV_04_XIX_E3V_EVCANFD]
      frame Klima_EV_04_XIX_E3V_EVCANFD: id 0x5EA, from Klima, frame-length=8, can-addressing-mode=STANDARD, can-frame-rx-behavior=CAN-FD, can-frame-tx-behavior=CAN-FD
        pdu Klima_EV_04_XIX_E3V_EVCANFD: length=8, transmission-mode-true-timing=cyclic-timing={time-offset=0.0, time-period=0.5}, unused-bit-pattern=0
          signal KL_Standklima_Status_03_XIX_Klima_EV_04_XIX_E3V_EVCANFD: start 1, 3 bit, little-endian, data-type-policy=OVERRIDE, i-signal-type=PRIMITIVE, init-value=6, base-type=BT_KL_Standklima_Status_03, invalid-value=Invalid_KL_Standklima_Status_03_XIX_Klima_EV_04_XIX_E3V_EVCANFD:7, compu {0=Cx0_nicht_aktiv (CM_KL_Standklima_Status_03_Cx0_nicht_aktiv), 1=Cx1_aktiv (CM_KL_Standklima_Status_03_Cx1_aktiv), 2=Cx2_eingeschraenkt_aktiv (CM_KL_Standklima_Status_03_Cx2_eingeschraenkt_aktiv), 3=Cx3_Systemfehler (CM_KL_Standklima_Status_03_Cx3_Systemfehler), 4=Cx4_nicht_moeglich (CM_KL_Standklima_Status_03_Cx4_nicht_moeglich), 5=Cx5_keine_Freigabe (CM_KL_Standklima_Status_03_Cx5_keine_Freigabe), 6=Cx6_Init (CM_KL_Standklima_Status_03_Cx6_Init), 7=Cx7_Fehler (CM_KL_Standklima_Status_03_Cx7_Fehler)}, range raw 0..7, transfer-property=PENDING  # Standklimatisierung Innenraum
          signal KL_Kundenwunsch_Kuehlen_XIX_Klima_EV_04_XIX_E3V_EVCANFD: start 4, 1 bit, little-endian, data-type-policy=OVERRIDE, i-signal-type=PRIMITIVE, init-value=0, base-type=BT_KL_Kundenwunsch_Kuehlen, compu {0=Cx0_Keine_Kuehlung_gewuenscht (CM_KL_Kundenwunsch_Kuehlen_Cx0_Keine_Kuehlung_gewuenscht), 1=Cx1_Kuehlung_gewuenscht (CM_KL_Kundenwunsch_Kuehlen_Cx1_Kuehlung_gewuenscht)}, range raw 0..1, transfer-property=PENDING  # KBT meldet aktiven Kühlungswunsch an Waermepumpen SG
          signal KL_OBD_Status_XIX_Klima_EV_04_XIX_E3V_EVCANFD: start 5, 1 bit, little-endian, data-type-policy=OVERRIDE, i-signal-type=PRIMITIVE, init-value=0, base-type=BT_KL_OBD_Status, compu {0=Cx0_MILaus (CM_KL_OBD_Status_Cx0_MILaus), 1=Cx1_MILan (CM_KL_OBD_Status_Cx1_MILan)}, range raw 0..1, transfer-property=PENDING  # Dieses Bit steuert die MIL-Lampe an (Motorsteuergerät reicht diese Info an Kombi weiter).
          signal KL_KLE_Fehler_Anf_XIX_Klima_EV_04_XIX_E3V_EVCANFD: start 6, 1 bit, little-endian, data-type-policy=OVERRIDE, i-signal-type=PRIMITIVE, init-value=0, base-type=BT_KL_KLE_Fehler_Anf, compu {0=Cx0_inaktiv (CM_KL_KLE_Fehler_Anf_Cx0_inaktiv), 1=Cx1_aktiv (CM_KL_KLE_Fehler_Anf_Cx1_aktiv)}, range raw 0..1, transfer-property=PENDING  # Anfrage der Klimatisierung an das MSG, ob ein Fehler im Kühlerlüfter vorliegt.
          signal KL_Fehler_NTKreis_XIX_Klima_EV_04_XIX_E3V_EVCANFD: start 7, 1 bit, little-endian, data-type-policy=OVERRIDE, i-signal-type=PRIMITIVE, init-value=0, base-type=BT_KL_Fehler_NTKreis, invalid-value=Invalid_KL_Fehler_NTKreis_XIX_Klima_EV_04_XIX_E3V_EVCANFD:1, compu {0=Cx0_KeinFehler (CM_KL_Fehler_NTKreis_Cx0_KeinFehler), 1=Cx1_Fehler (CM_KL_Fehler_NTKreis_Cx1_Fehler)}, range raw 0..1, transfer-property=PENDING  # Über dieses Fehlersignal werden andere Steuergeräte am NT-Kreis über einen Fehler in der Klimatisierung informiert und können so Folgefehlereinträge vermeiden.
          signal KL_Mot_Tk_Soll_li_XIX_Klima_EV_04_XIX_E3V_EVCANFD: start 8, 8 bit, little-endian, data-type-policy=OVERRIDE, i-signal-type=PRIMITIVE, init-value=0, base-type=BT_KL_Mot_Tk_Soll_li, compu {phys=raw*0.5 for raw 0..200; unit Unit_PerCent}, range phys 0..100 Unit_PerCent, raw 0..200, unit=Unit_PerCent, transfer-property=PENDING  # Stellung Temperaturklappe Soll links
          signal KL_Mot_Tk_Soll_re_XIX_Klima_EV_04_XIX_E3V_EVCANFD: start 16, 8 bit, little-endian, data-type-policy=OVERRIDE, i-signal-type=PRIMITIVE, init-value=0, base-type=BT_KL_Mot_Tk_Soll_re, compu {phys=raw*0.5 for raw 0..200; unit Unit_PerCent}, range phys 0..100 Unit_PerCent, raw 0..200, unit=Unit_PerCent, transfer-property=PENDING  # Stellung Temperaturklappe Soll rechts
          signal KL_VK_Anf_XIX_Klima_EV_04_XIX_E3V_EVCANFD: start 24, 3 bit, little-endian, data-type-policy=OVERRIDE, i-signal-type=PRIMITIVE, init-value=6, base-type=BT_KL_VK_Anf, invalid-value=Invalid_KL_VK_Anf_XIX_Klima_EV_04_XIX_E3V_EVCANFD:7, compu {0=Cx0_keine_Startanf_von_Climatronic (CM_KL_VK_Anf_Cx0_keine_Startanf_von_Climatronic), 1=Cx1_Startanf_via_FFB (CM_KL_VK_Anf_Cx1_Startanf_via_FFB), 2=Cx2_Startanf_via_Sofortheiztaste (CM_KL_VK_Anf_Cx2_Startanf_via_Sofortheiztaste), 3=Cx3_VK_Strategie_STH (CM_KL_VK_Anf_Cx3_VK_Strategie_STH), 4=Cx4_Startanf_via_ZV_FFB (CM_KL_VK_Anf_Cx4_Startanf_via_ZV_FFB), 5=Cx5_VK_Abbruch (CM_KL_VK_Anf_Cx5_VK_Abbruch), 6=Cx6_Init (CM_KL_VK_Anf_Cx6_Init), 7=Cx7_Fehler (CM_KL_VK_Anf_Cx7_Fehler)}, range raw 0..7, transfer-property=PENDING  # Starten einer Standklimatisierung ausgehend von der Climatronic Richtung Lademanagment.
          signal KL_Standklima_Status_02_XIX_Klima_EV_04_XIX_E3V_EVCANFD: start 27, 3 bit, little-endian, data-type-policy=OVERRIDE, i-signal-type=PRIMITIVE, init-value=6, base-type=BT_KL_Standklima_Status_02, invalid-value=Invalid_KL_Standklima_Status_02_XIX_Klima_EV_04_XIX_E3V_EVCANFD:7, compu {0=Cx0_nicht_aktiv (CM_KL_Standklima_Status_02_Cx0_nicht_aktiv), 1=Cx1_aktiv (CM_KL_Standklima_Status_02_Cx1_aktiv), 2=Cx2_eingeschraenkt_aktiv (CM_KL_Standklima_Status_02_Cx2_eingeschraenkt_aktiv), 3=Cx3_Abbruch_durch_Benutzer (CM_KL_Standklima_Status_02_Cx3_Abbruch_durch_Benutzer), 4=Cx4_nicht_moeglich (CM_KL_Standklima_Status_02_Cx4_nicht_moeglich), 5=Cx5_Aussenhuelle_offen (CM_KL_Standklima_Status_02_Cx5_Aussenhuelle_offen), 6=Cx6_Init (CM_KL_Standklima_Status_02_Cx6_Init), 7=Cx7_Fehler (CM_KL_Standklima_Status_02_Cx7_Fehler)}, range raw 0..7, transfer-property=PENDING  # Status der Standklimatisierung (Innenraum)
          signal KL_Standklima_RemoteModus_XIX_Klima_EV_04_XIX_E3V_EVCANFD: start 30, 3 bit, little-endian, data-type-policy=OVERRIDE, i-signal-type=PRIMITIVE, init-value=0, base-type=BT_KL_Standklima_RemoteModus, compu {0=Cx0_Init_nicht_aktiv (CM_KL_Standklima_RemoteModus_Cx0_Init_nicht_aktiv) (Init__nicht_aktiv), 1=Cx1_Lueften (CM_KL_Standklima_RemoteModus_Cx1_Lueften), 2=Cx2_Kuehlen (CM_KL_Standklima_RemoteModus_Cx2_Kuehlen), 3=Cx3_Heizen (CM_KL_Standklima_RemoteModus_Cx3_Heizen), 4=Cx4_reserviert (CM_KL_Standklima_RemoteModus_Cx4_reserviert), 5=Cx5_reserviert (CM_KL_Standklima_RemoteModus_Cx5_reserviert), 6=Cx6_reserviert (CM_KL_Standklima_RemoteModus_Cx6_reserviert), 7=Cx7_reserviert (CM_KL_Standklima_RemoteModus_Cx7_reserviert)}, range raw 0..7, transfer-property=PENDING  # Modus (Lüften, Kühlen, Heizen) der Standklimatisierung (Innenraum) zur Remote Anzeige
          signal KBT_Defrost_aktiv_XIX_Klima_EV_04_XIX_E3V_EVCANFD: start 33, 1 bit, little-endian, data-type-policy=OVERRIDE, i-signal-type=PRIMITIVE, init-value=0, base-type=BT_KBT_Defrost_aktiv, compu {0=Cx0_inaktiv (CM_KBT_Defrost_aktiv_Cx0_inaktiv), 1=Cx1_aktiv (CM_KBT_Defrost_aktiv_Cx1_aktiv)}, range raw 0..1, transfer-property=PENDING  # Defrostmodus im KBT aktiv
          signal KL_VK_Betriebsdauer_XIX_Klima_EV_04_XIX_E3V_EVCANFD: start 34, 6 bit, little-endian, data-type-policy=OVERRIDE, i-signal-type=PRIMITIVE, init-value=62, base-type=BT_KL_VK_Betriebsdauer, invalid-value=Invalid_KL_VK_Betriebsdauer_XIX_Klima_EV_04_XIX_E3V_EVCANFD:63, compu {phys=raw for raw 0..60, 62=Cx3e_Init (CM_KL_VK_Betriebsdauer_Cx3e_Init), 63=Cx3f_Fehler (CM_KL_VK_Betriebsdauer_Cx3f_Fehler); unit Unit_Minut}, range phys 0..60 Unit_Minut, raw 0..63, unit=Unit_Minut, transfer-property=PENDING  # Berechnete notwendige Betriebsdauer der Vorkonditionierung des Innerraumes (Standklimatisierung).
          signal KL_Heizbedarf_XIX_Klima_EV_04_XIX_E3V_EVCANFD: start 40, 10 bit, little-endian, data-type-policy=OVERRIDE, i-signal-type=PRIMITIVE, init-value=1022, base-type=BT_KL_Heizbedarf, invalid-value=Invalid_KL_Heizbedarf_XIX_Klima_EV_04_XIX_E3V_EVCANFD:1023, compu {0=Cx0_Kein_Heizbedarf (CM_KL_Heizbedarf_Cx0_Kein_Heizbedarf), phys=raw*0.1 for raw 1..900, 1022=Cx3fe_Init (CM_KL_Heizbedarf_Cx3fe_Init), 1023=Cx3ff_Fehler (CM_KL_Heizbedarf_Cx3ff_Fehler); unit Unit_DegreCelsi}, range phys 0.1..90 Unit_DegreCelsi, raw 0..1023, unit=Unit_DegreCelsi, transfer-property=PENDING  # Bedarf an Heizmenge für Innenraumklimatisierung
          signal KL_Innentemp_KBT_Sensor_XIX_Klima_EV_04_XIX_E3V_EVCANFD: start 50, 10 bit, little-endian, data-type-policy=OVERRIDE, i-signal-type=PRIMITIVE, init-value=1022, base-type=BT_KL_Innentemp_KBT_Sensor, invalid-value=Invalid_KL_Innentemp_KBT_Sensor_XIX_Klima_EV_04_XIX_E3V_EVCANFD:1023, compu {phys=raw*0.1-40 for raw 0..1020, 1022=Cx3fe_Init (CM_KL_Innentemp_KBT_Sensor_Cx3fe_Init), 1023=Cx3ff_Fehler (CM_KL_Innentemp_KBT_Sensor_Cx3ff_Fehler); unit Unit_DegreCelsi}, range phys -40..62 Unit_DegreCelsi, raw 0..1023, unit=Unit_DegreCelsi, transfer-property=PENDING  # Temperatur Innenraum vor Klimabedienteil
          signal KL_Vorkond_Strategie_XIX_Klima_EV_04_XIX_E3V_EVCANFD: start 60, 4 bit, little-endian, data-type-policy=OVERRIDE, i-signal-type=PRIMITIVE, init-value=15, base-type=BT_KL_Vorkond_Strategie, compu {0=Cx0_Aus (CM_KL_Vorkond_Strategie_Cx0_Aus), 1=Cx1_Spuelen (CM_KL_Vorkond_Strategie_Cx1_Spuelen) (Spülen), 2=Cx2_Kanalkuehlung (CM_KL_Vorkond_Strategie_Cx2_Kanalkuehlung) (Kanalkühlung), 3=Cx3_Kuehlwasserzirkulation (CM_KL_Vorkond_Strategie_Cx3_Kuehlwasserzirkulation) (Kühlwasserzirkulation), 4=Cx4_Aktive_Kuehlung (CM_KL_Vorkond_Strategie_Cx4_Aktive_Kuehlung) (Aktive Kühlung), 5=Cx5_Heizen (CM_KL_Vorkond_Strategie_Cx5_Heizen), 6=Cx6_Reheat (CM_KL_Vorkond_Strategie_Cx6_Reheat), 7=Cx7_Heizen_elektrisch (CM_KL_Vorkond_Strategie_Cx7_Heizen_elektrisch), 8=Cx8_Heizen_verbrennungstechnisch (CM_KL_Vorkond_Strategie_Cx8_Heizen_verbrennungstechnisch), 13=Cxd_Strategie_nicht_berechnet (CM_KL_Vorkond_Strategie_Cxd_Strategie_nicht_berechnet), 14=Cxe_Konditionierung_nicht_moeglich (CM_KL_Vorkond_Strategie_Cxe_Konditionierung_nicht_moeglich), 15=Cxf_Init (CM_KL_Vorkond_Strategie_Cxf_Init)}, range raw 0..15, transfer-property=PENDING  # Strategie der Vorkonditionierung des Innenraums
